VERSION ""

NS_ :

BS_:

BU_: EOCM2B_IMX6_HS EOCM2A_IMX6_HS EOCM2B_K2_HS EOCM2A_K2_HS TTPM_HS AMM_HS EBOOST_OBD_HS CGM_HS BSM_HS HCP_B_HS AVM_HS PFAF_HS LVMPC_HS DCDC_HS DEFC_HS VPM_HS IPC_HS V2V_HS TCP_HS CSM_HS EOCM2B_K1_HS EOCM2A_K1_HS TRCM_HS ESCM_SP_HS ICCM_B_HS AMP_HS FICM_HS ARS_HS MCP_B_HS MCP_A_HS ICCM_OBD_HS SAS_HS ACCM_HS VLBS_HS EBCM_OBD_HS HCP_T_HS EDI_HS PLCM_HS VITM_OBD_HS VICM_HS HCP_HS APPS_HS ICCM_HS EOCM_F_HS GPCM_HS VCM_HS HMIM_HS VES_HS Dummy_HS MCP_C_HS ONSTAR_HS EPS_HS TestTool_HS MCP_HS BCP_HS ALC_HS AHL_AFL_HS SADS_HS EPB_HS FCM_HS TCCM_HS RDCM_HS PTO_HS EBCM_HS ACC_HS BCM_HS TCM_HS ECM_HS

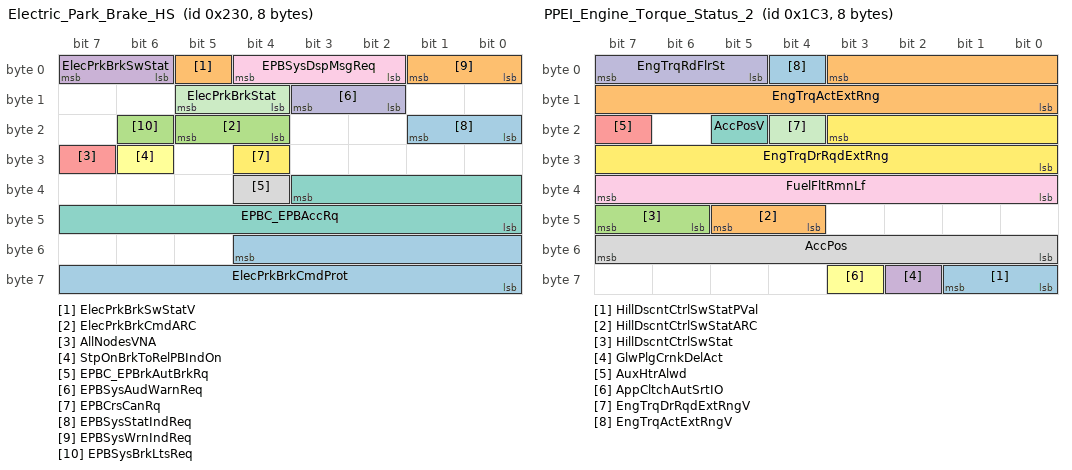
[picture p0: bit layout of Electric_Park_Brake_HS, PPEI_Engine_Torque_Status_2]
BO_ 560 Electric_Park_Brake_HS: 8 EPB_HS
 SG_ ElecPrkBrkCmdProt : 52|13@0+ (1,0) [0|8191] ""  EOCM2B_IMX6_HS,EOCM2A_IMX6_HS,EOCM2B_K1_HS,EOCM2A_K1_HS,CGM_HS,EBCM_OBD_HS,EBCM_HS
 SG_ ElecPrkBrkSwStatV : 5|1@0+ (1,0) [0|1] ""  EOCM2B_IMX6_HS,EOCM2A_IMX6_HS,EOCM2B_K1_HS,EOCM2A_K1_HS,CGM_HS,EBCM_OBD_HS,EBCM_HS
 SG_ ElecPrkBrkCmdARC : 21|2@0+ (1,0) [0|3] ""  EOCM2B_IMX6_HS,EOCM2A_IMX6_HS,EOCM2B_K1_HS,EOCM2A_K1_HS,CGM_HS,EBCM_OBD_HS,EBCM_HS
 SG_ ElecPrkBrkSwStat : 7|2@0+ (1,0) [0|3] ""  EOCM2B_IMX6_HS,EOCM2A_IMX6_HS,EOCM2B_K1_HS,EOCM2A_K1_HS,CGM_HS,EBCM_OBD_HS,EBCM_HS
 SG_ AllNodesVNA : 31|1@0+ (1,0) [0|1] ""  EOCM2B_IMX6_HS,EOCM2A_IMX6_HS,EOCM2B_K1_HS,EOCM2A_K1_HS,CGM_HS,BCM_HS
 SG_ StpOnBrkToRelPBIndOn : 30|1@0+ (1,0) [0|1] ""  EOCM2B_IMX6_HS,EOCM2A_IMX6_HS,EOCM2B_K1_HS,EOCM2A_K1_HS,CGM_HS,BCM_HS
 SG_ EPBC_EPBAccRq : 35|12@0- (0.01,0) [-20.48|20.47] "m/s^2"  EOCM2B_IMX6_HS,EOCM2A_IMX6_HS,EOCM2B_K1_HS,EOCM2A_K1_HS,CGM_HS,EBCM_OBD_HS,EBCM_HS
 SG_ EPBC_EPBrkAutBrkRq : 36|1@0+ (1,0) [0|1] ""  EOCM2B_IMX6_HS,EOCM2A_IMX6_HS,EOCM2B_K1_HS,EOCM2A_K1_HS,CGM_HS,EBCM_OBD_HS,EBCM_HS
 SG_ EPBSysDspMsgReq : 4|3@0+ (1,0) [0|7] ""  EOCM2B_IMX6_HS,EOCM2A_IMX6_HS,EOCM2B_K1_HS,EOCM2A_K1_HS,CGM_HS,BCM_HS
 SG_ EPBSysAudWarnReq : 11|2@0+ (1,0) [0|3] ""  EOCM2B_IMX6_HS,EOCM2A_IMX6_HS,EOCM2B_K1_HS,EOCM2A_K1_HS,CGM_HS,BCM_HS
 SG_ ElecPrkBrkStat : 13|2@0+ (1,0) [0|3] ""  EOCM2B_IMX6_HS,EOCM2A_IMX6_HS,FCM_HS,EOCM2B_K1_HS,EOCM2A_K1_HS,CGM_HS,ICCM_B_HS,ICCM_OBD_HS,ICCM_HS,ACC_HS,EOCM_F_HS,BCM_HS,EBCM_OBD_HS,EBCM_HS,RDCM_HS
 SG_ EPBCrsCanRq : 28|1@0+ (1,0) [0|1] ""  EOCM2B_IMX6_HS,EOCM2A_IMX6_HS,FCM_HS,EOCM2B_K1_HS,EOCM2A_K1_HS,CGM_HS,ACC_HS,EOCM_F_HS,EBCM_OBD_HS,EBCM_HS,BCM_HS
 SG_ EPBSysStatIndReq : 17|2@0+ (1,0) [0|3] ""  EOCM2B_IMX6_HS,EOCM2A_IMX6_HS,EOCM2B_K1_HS,EOCM2A_K1_HS,CGM_HS,BCM_HS
 SG_ EPBSysWrnIndReq : 1|2@0+ (1,0) [0|3] ""  EOCM2B_IMX6_HS,EOCM2A_IMX6_HS,EOCM2B_K1_HS,EOCM2A_K1_HS,CGM_HS,BCM_HS
 SG_ EPBSysBrkLtsReq : 22|1@0+ (1,0) [0|1] ""  EOCM2B_IMX6_HS,EOCM2A_IMX6_HS,EOCM2B_K1_HS,EOCM2A_K1_HS,CGM_HS,BCM_HS

BO_ 451 PPEI_Engine_Torque_Status_2: 8 ECM_HS
 SG_ HillDscntCtrlSwStatPVal : 57|2@0+ (1,0) [0|3] ""  EOCM2B_K2_HS,EOCM2A_K2_HS,EOCM2B_K1_HS,CGM_HS,EOCM2A_K1_HS,EBCM_OBD_HS,EBCM_HS
 SG_ HillDscntCtrlSwStatARC : 45|2@0+ (1,0) [0|3] ""  EOCM2B_K2_HS,EOCM2A_K2_HS,EOCM2B_K1_HS,CGM_HS,EOCM2A_K1_HS,EBCM_OBD_HS,EBCM_HS
 SG_ HillDscntCtrlSwStat : 47|2@0+ (1,0) [0|3] ""  EOCM2B_K2_HS,EOCM2A_K2_HS,EOCM2B_K1_HS,CGM_HS,EOCM2A_K1_HS,EBCM_OBD_HS,EBCM_HS
 SG_ GlwPlgCrnkDelAct : 58|1@0+ (1,0) [0|1] ""  EOCM2B_K2_HS,EOCM2A_K2_HS,EOCM2B_K1_HS,CGM_HS,EOCM2A_K1_HS,BCM_HS
 SG_ AuxHtrAlwd : 23|1@0+ (1,0) [0|1] ""  EOCM2B_K2_HS,EOCM2A_K2_HS,EOCM2B_K1_HS,CGM_HS,EOCM2A_K1_HS,BCM_HS
 SG_ AppCltchAutSrtIO : 59|1@0+ (1,0) [0|1] ""  EOCM2B_K2_HS,EOCM2A_K2_HS,EOCM2B_K1_HS,CGM_HS,EOCM2A_K1_HS,BCM_HS
 SG_ AccPosV : 21|1@0+ (1,0) [0|1] ""  EOCM2B_K2_HS,EOCM2A_K2_HS,FCM_HS,EOCM2B_K1_HS,RDCM_HS,CGM_HS,EOCM2A_K1_HS,ICCM_B_HS,ICCM_OBD_HS,ICCM_HS,ACC_HS,EOCM_F_HS,TCCM_HS,EBCM_OBD_HS,EBCM_HS
 SG_ AccPos : 55|8@0+ (0.392157,0) [0|100.000035] "%"  EOCM2B_K2_HS,EOCM2A_K2_HS,FCM_HS,EOCM2B_K1_HS,RDCM_HS,CGM_HS,EOCM2A_K1_HS,ICCM_B_HS,ICCM_OBD_HS,ICCM_HS,EOCM_F_HS,BSM_HS,VICM_HS,ACC_HS,TCCM_HS,EBCM_OBD_HS,EBCM_HS
 SG_ FuelFltRmnLf : 39|8@0+ (0.392157,0) [0|100.000035] "%"  EOCM2B_K2_HS,EOCM2A_K2_HS,EOCM2B_K1_HS,CGM_HS,EOCM2A_K1_HS,TCP_HS,ONSTAR_HS,BCM_HS
 SG_ EngTrqRdFlrSt : 7|3@0+ (1,0) [0|7] ""  EOCM2B_K2_HS,EOCM2A_K2_HS,EOCM2B_K1_HS,CGM_HS,EOCM2A_K1_HS,EBCM_OBD_HS,EBCM_HS
 SG_ EngTrqDrRqdExtRngV : 20|1@0+ (1,0) [0|1] ""  EOCM2B_K2_HS,EOCM2A_K2_HS,TCCM_HS,EOCM2B_K1_HS,CGM_HS,EOCM2A_K1_HS,BCM_HS,ACC_HS,LVMPC_HS,RDCM_HS,EBCM_OBD_HS,EBCM_HS,SADS_HS
 SG_ EngTrqDrRqdExtRng : 19|12@0+ (0.5,-848) [-848|1199.5] "Nm"  EOCM2B_K2_HS,EOCM2A_K2_HS,TCCM_HS,EOCM2B_K1_HS,CGM_HS,EOCM2A_K1_HS,BCM_HS,LVMPC_HS,ACC_HS,RDCM_HS,EBCM_OBD_HS,EBCM_HS,SADS_HS
 SG_ EngTrqActExtRngV : 4|1@0+ (1,0) [0|1] ""  EOCM2B_K2_HS,EOCM2A_K2_HS,EOCM2B_K1_HS,CGM_HS,EOCM2A_K1_HS,AVM_HS,PTO_HS,ICCM_B_HS,ICCM_OBD_HS,ICCM_HS,AMP_HS,TCCM_HS,VES_HS,ACC_HS,EPS_HS,EPB_HS,BCM_HS,RDCM_HS,EBCM_OBD_HS,EBCM_HS,SADS_HS
 SG_ EngTrqActExtRng : 3|12@0+ (0.5,-848) [-848|1199.5] "Nm"  EOCM2B_K2_HS,EOCM2A_K2_HS,EOCM2B_K1_HS,CGM_HS,EOCM2A_K1_HS,AVM_HS,ICCM_B_HS,ICCM_OBD_HS,ICCM_HS,PTO_HS,AMP_HS,TCCM_HS,VES_HS,ACC_HS,EPS_HS,EPB_HS,BCM_HS,RDCM_HS,EBCM_OBD_HS,EBCM_HS,SADS_HS

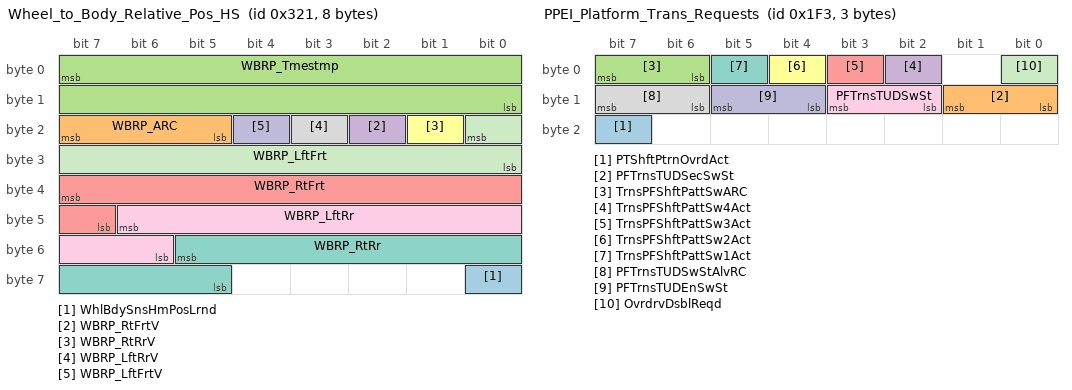
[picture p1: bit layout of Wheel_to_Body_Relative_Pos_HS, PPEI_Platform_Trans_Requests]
BO_ 801 Wheel_to_Body_Relative_Pos_HS: 8 SADS_HS
 SG_ WhlBdySnsHmPosLrnd : 56|1@0+ (1,0) [0|1] ""  EOCM2B_K1_HS,EOCM2A_K1_HS,CGM_HS,EDI_HS,ICCM_B_HS,ICCM_OBD_HS,ICCM_HS,ALC_HS,SADS_HS,FCM_HS,AHL_AFL_HS,EBCM_OBD_HS,EBCM_HS
 SG_ WBRP_ARC : 23|3@0+ (1,0) [0|7] "counts"  LVMPC_HS,EOCM2B_K1_HS,EOCM2A_K1_HS,CGM_HS,EDI_HS,ICCM_B_HS,ICCM_OBD_HS,ICCM_HS,ALC_HS,SADS_HS,FCM_HS,EBCM_OBD_HS,EBCM_HS,AHL_AFL_HS
 SG_ WBRP_Tmestmp : 7|16@0+ (1,0) [0|65535] "micro sec"  LVMPC_HS,EOCM2B_K1_HS,EOCM2A_K1_HS,CGM_HS,EDI_HS,ICCM_B_HS,ICCM_OBD_HS,ICCM_HS,ALC_HS,SADS_HS,FCM_HS,EBCM_OBD_HS,EBCM_HS,AHL_AFL_HS
 SG_ WBRP_RtFrtV : 18|1@0+ (1,0) [0|1] ""  LVMPC_HS,EOCM2B_K1_HS,EOCM2A_K1_HS,CGM_HS,EDI_HS,ICCM_B_HS,ICCM_OBD_HS,ICCM_HS,ALC_HS,SADS_HS,FCM_HS,EBCM_OBD_HS,EBCM_HS,AHL_AFL_HS
 SG_ WBRP_RtFrt : 39|9@0- (1,0) [-256|255] "mm"  LVMPC_HS,EOCM2B_K1_HS,EOCM2A_K1_HS,CGM_HS,EDI_HS,ICCM_B_HS,ICCM_OBD_HS,ICCM_HS,ALC_HS,SADS_HS,FCM_HS,EBCM_OBD_HS,EBCM_HS,AHL_AFL_HS
 SG_ WBRP_RtRrV : 17|1@0+ (1,0) [0|1] ""  LVMPC_HS,EOCM2B_K1_HS,EOCM2A_K1_HS,CGM_HS,EDI_HS,ICCM_B_HS,ICCM_OBD_HS,ICCM_HS,ALC_HS,SADS_HS,FCM_HS,EBCM_OBD_HS,EBCM_HS,AHL_AFL_HS
 SG_ WBRP_RtRr : 53|9@0- (1,0) [-256|255] "mm"  LVMPC_HS,EOCM2B_K1_HS,EOCM2A_K1_HS,CGM_HS,EDI_HS,ICCM_B_HS,ICCM_OBD_HS,ICCM_HS,ALC_HS,SADS_HS,FCM_HS,EBCM_OBD_HS,EBCM_HS,AHL_AFL_HS
 SG_ WBRP_LftRrV : 19|1@0+ (1,0) [0|1] ""  LVMPC_HS,EOCM2B_K1_HS,EOCM2A_K1_HS,CGM_HS,EDI_HS,ICCM_B_HS,ICCM_OBD_HS,ICCM_HS,ALC_HS,SADS_HS,FCM_HS,EBCM_OBD_HS,EBCM_HS,AHL_AFL_HS
 SG_ WBRP_LftRr : 46|9@0- (1,0) [-256|255] "mm"  LVMPC_HS,EOCM2B_K1_HS,EOCM2A_K1_HS,CGM_HS,EDI_HS,ICCM_B_HS,ICCM_OBD_HS,ICCM_HS,ALC_HS,SADS_HS,FCM_HS,EBCM_OBD_HS,EBCM_HS,AHL_AFL_HS
 SG_ WBRP_LftFrtV : 20|1@0+ (1,0) [0|1] ""  LVMPC_HS,EOCM2B_K1_HS,EOCM2A_K1_HS,CGM_HS,EDI_HS,ICCM_B_HS,ICCM_OBD_HS,ICCM_HS,ALC_HS,SADS_HS,FCM_HS,EBCM_OBD_HS,EBCM_HS,AHL_AFL_HS
 SG_ WBRP_LftFrt : 16|9@0- (1,0) [-256|255] "mm"  LVMPC_HS,EOCM2B_K1_HS,EOCM2A_K1_HS,CGM_HS,EDI_HS,ICCM_B_HS,ICCM_OBD_HS,ICCM_HS,ALC_HS,SADS_HS,FCM_HS,EBCM_OBD_HS,EBCM_HS,AHL_AFL_HS

BO_ 320 Exterior_Lighting_HS: 3 BCM_HS
 SG_ Ky_IdDevPrgmAuthReq : 14|1@0+ (1,0) [0|1] ""  EOCM2B_IMX6_HS,EOCM2A_IMX6_HS,EOCM2B_K1_HS,CGM_HS,EPS_HS,EOCM2A_K1_HS
 SG_ ClmnLckStatV : 15|1@0+ (1,0) [0|1] ""  EOCM2B_IMX6_HS,EOCM2A_IMX6_HS,EOCM2B_K1_HS,CGM_HS,EPS_HS,EOCM2A_K1_HS
 SG_ ClmnLckStat : 21|2@0+ (1,0) [0|3] ""  EOCM2B_IMX6_HS,EOCM2A_IMX6_HS,EOCM2B_K1_HS,CGM_HS,EPS_HS,EOCM2A_K1_HS
 SG_ AutoBmSlctAllwd : 13|1@0+ (1,0) [0|1] ""  EOCM2B_IMX6_HS,EOCM2A_IMX6_HS,EOCM2B_K1_HS,CGM_HS,AHL_AFL_HS,EOCM2A_K1_HS
 SG_ BrkLtsAtv : 6|1@0+ (1,0) [0|1] ""  EOCM2B_IMX6_HS,EOCM2A_IMX6_HS,V2V_HS,VPM_HS,EOCM2B_K1_HS,CGM_HS,EOCM2A_K1_HS,AHL_AFL_HS,EOCM_F_HS,ACC_HS
 SG_ TrnSwAct : 19|2@0+ (1,0) [0|3] ""  EOCM2B_IMX6_HS,EOCM2A_IMX6_HS,VPM_HS,EOCM2B_K1_HS,V2V_HS,CGM_HS,EBCM_OBD_HS,EBCM_HS,EOCM2A_K1_HS,ECM_HS,EOCM_F_HS,AHL_AFL_HS
 SG_ RrFogLmpsAct : 8|1@0+ (1,0) [0|1] ""  EOCM2B_IMX6_HS,EOCM2A_IMX6_HS,VPM_HS,EOCM2B_K1_HS,V2V_HS,CGM_HS,EOCM2A_K1_HS,AHL_AFL_HS
 SG_ OtsdAmbtLtLvlStatV : 2|1@0+ (1,0) [0|1] ""  EOCM2B_IMX6_HS,EOCM2A_IMX6_HS,ICCM_B_HS,EBCM_OBD_HS,EBCM_HS,ECM_HS,VPM_HS,ICCM_HS,EOCM2B_K1_HS,CGM_HS,EOCM2A_K1_HS,FCM_HS,EOCM_F_HS,AHL_AFL_HS
 SG_ OtsdAmbtLtLvlStat : 17|2@0+ (1,0) [0|3] ""  EOCM2B_IMX6_HS,EOCM2A_IMX6_HS,ICCM_B_HS,EBCM_OBD_HS,EBCM_HS,ECM_HS,VPM_HS,ICCM_HS,EOCM2B_K1_HS,CGM_HS,EOCM2A_K1_HS,FCM_HS,EOCM_F_HS,AHL_AFL_HS
 SG_ MainLghtSw : 12|2@0+ (1,0) [0|3] "N/A"  EOCM2B_IMX6_HS,EOCM2A_IMX6_HS,VPM_HS,EOCM2B_K1_HS,CGM_HS,EOCM2A_K1_HS,FCM_HS,AHL_AFL_HS
 SG_ LowBmAct : 1|1@0+ (1,0) [0|1] ""  EOCM2B_IMX6_HS,EOCM2A_IMX6_HS,VPM_HS,EOCM2B_K1_HS,V2V_HS,CGM_HS,EOCM2A_K1_HS,FCM_HS,EOCM_F_HS,AHL_AFL_HS
 SG_ HighBmAct : 7|1@0+ (1,0) [0|1] ""  EOCM2B_IMX6_HS,EOCM2A_IMX6_HS,VPM_HS,EOCM2B_K1_HS,V2V_HS,CGM_HS,EOCM2A_K1_HS,FCM_HS,EOCM_F_HS,AHL_AFL_HS
 SG_ HdlmpBmSelectStat : 10|2@0+ (1,0) [0|3] ""  EOCM2B_IMX6_HS,EOCM2A_IMX6_HS,VPM_HS,EOCM2B_K1_HS,CGM_HS,EOCM2A_K1_HS,FCM_HS,AHL_AFL_HS
 SG_ FlToPsSwAtv : 5|1@0+ (1,0) [0|1] ""  EOCM2B_IMX6_HS,EOCM2A_IMX6_HS,EOCM2B_K1_HS,CGM_HS,EOCM2A_K1_HS,FCM_HS,AHL_AFL_HS
 SG_ AdvFrntLghtSysEnbld : 3|1@0+ (1,0) [0|1] ""  EOCM2B_IMX6_HS,EOCM2A_IMX6_HS,V2V_HS,EOCM2B_K1_HS,CGM_HS,EOCM2A_K1_HS,AHL_AFL_HS
 SG_ FrFogLmpsAct : 0|1@0+ (1,0) [0|1] ""  EOCM2B_IMX6_HS,EOCM2A_IMX6_HS,VPM_HS,EOCM2B_K1_HS,V2V_HS,CGM_HS,EOCM2A_K1_HS,FCM_HS,AHL_AFL_HS
 SG_ AutLghtCtrl : 4|1@0+ (1,0) [0|1] "N/A"  EOCM2B_IMX6_HS,EOCM2A_IMX6_HS,V2V_HS,EOCM2B_K1_HS,CGM_HS,EOCM2A_K1_HS,AHL_AFL_HS

BO_ 957 ETEI_Glow_Plug_Diagnostic_Status: 8 GPCM_HS
 SG_ RdctHtrCStat : 26|1@0+ (1,0) [0|1] ""  CGM_HS,ECM_HS
 SG_ RdctHtrBStat : 27|1@0+ (1,0) [0|1] ""  CGM_HS,ECM_HS
 SG_ RdctHtrAStat : 28|1@0+ (1,0) [0|1] ""  CGM_HS,ECM_HS
 SG_ GPCMDS2_DTCStatus : 58|3@0+ (1,0) [0|7] ""  CGM_HS,ECM_HS
 SG_ GPCMDS2_DTCIndex : 63|5@0+ (1,0) [0|31] ""  CGM_HS,ECM_HS
 SG_ IntAirHtrPwrConsmp : 55|8@0+ (20,0) [0|5100] "W"  CGM_HS,ECM_HS
 SG_ IntAirHtrPwrConsmpV : 29|1@0+ (1,0) [0|1] ""  CGM_HS,ECM_HS
 SG_ DslGlwPlgMdOvTmOD : 25|1@0+ (1,0) [0|1] ""  CGM_HS,ECM_HS
 SG_ IQAI_DataByte : 47|8@0+ (1,0) [0|255] ""  CGM_HS,ECM_HS
 SG_ IQAI_DataSeqNmbr : 35|4@0+ (1,0) [0|15] ""  CGM_HS,ECM_HS
 SG_ IQAI_InjIdInd : 38|3@0+ (1,0) [0|7] ""  CGM_HS,ECM_HS
 SG_ IQAI_DataStat : 39|1@0+ (1,0) [0|1] ""  CGM_HS,ECM_HS
 SG_ IntAirHtrTempSensVoltV : 30|1@0+ (1,0) [0|1] ""  CGM_HS,ECM_HS
 SG_ IntAirHtrTempSensVolt : 23|8@0+ (0.0196078,0) [0|4.999989] "volts"  CGM_HS,ECM_HS
 SG_ IntAirHtrSupVoltV : 31|1@0+ (1,0) [0|1] ""  CGM_HS,ECM_HS
 SG_ IntAirHtrSupVolt : 15|8@0+ (0.1,0) [0|25.5] "volts"  CGM_HS,ECM_HS
 SG_ GPCMDS_DTCStatus : 2|3@0+ (1,0) [0|7] ""  CGM_HS,ECM_HS
 SG_ GPCMDS_DTCIndex : 7|5@0+ (1,0) [0|31] ""  CGM_HS,ECM_HS

BO_ 1364 UUDT_Resp_From_EPB_HS: 8 EPB_HS
 SG_ DgnInf_HS554 : 7|64@0+ (1,0) [0|1.8446744074e+19] ""  HMIM_HS,CSM_HS,CGM_HS,TCP_HS,ONSTAR_HS,TestTool_HS

BO_ 2041 PCU_Resp_From_SDM_HS: 8 BCM_HS
 SG_ PCUInfo_7F9 : 7|64@0+ (1,0) [0|1.8446744074e+19] ""  CGM_HS,TestTool_HS

BO_ 1904 DTC_Triggered_770: 7 ICCM_OBD_HS
 SG_ DTCI_WrnIndRqdSt_770 : 47|1@0+ (1,0) [0|1] ""  CGM_HS,CSM_HS,HMIM_HS,TCP_HS,VLBS_HS,ONSTAR_HS
 SG_ DTCIUnused7_770 : 7|1@0+ (1,0) [0|1] ""  CGM_HS,CSM_HS,HMIM_HS,TCP_HS,VLBS_HS,ONSTAR_HS
 SG_ DTCIUnused6_770 : 6|1@0+ (1,0) [0|1] ""  CGM_HS,CSM_HS,HMIM_HS,TCP_HS,VLBS_HS,ONSTAR_HS
 SG_ DTCIUnused5_770 : 5|1@0+ (1,0) [0|1] ""  CGM_HS,CSM_HS,HMIM_HS,TCP_HS,VLBS_HS,ONSTAR_HS
 SG_ DTCIUnused4_770 : 4|1@0+ (1,0) [0|1] ""  CGM_HS,CSM_HS,HMIM_HS,TCP_HS,VLBS_HS,ONSTAR_HS
 SG_ DTCIUnused3_770 : 3|1@0+ (1,0) [0|1] ""  CGM_HS,CSM_HS,HMIM_HS,TCP_HS,VLBS_HS,ONSTAR_HS
 SG_ DTCIUnused2_770 : 2|1@0+ (1,0) [0|1] ""  CGM_HS,CSM_HS,HMIM_HS,TCP_HS,VLBS_HS,ONSTAR_HS
 SG_ DTCIUnused1_770 : 1|1@0+ (1,0) [0|1] ""  CGM_HS,CSM_HS,HMIM_HS,TCP_HS,VLBS_HS,ONSTAR_HS
 SG_ DTCI_TstNPsdPwrUpSt_770 : 45|1@0+ (1,0) [0|1] ""  CGM_HS,CSM_HS,HMIM_HS,TCP_HS,VLBS_HS,ONSTAR_HS
 SG_ DTCI_TstNPsdCdClrdSt_770 : 42|1@0+ (1,0) [0|1] ""  CGM_HS,CSM_HS,HMIM_HS,TCP_HS,VLBS_HS,ONSTAR_HS
 SG_ DTCI_TstFldPwrUpSt_770 : 46|1@0+ (1,0) [0|1] ""  CGM_HS,CSM_HS,HMIM_HS,TCP_HS,VLBS_HS,ONSTAR_HS
 SG_ DTCI_TstFldCdClrdStat_770 : 43|1@0+ (1,0) [0|1] ""  CGM_HS,CSM_HS,HMIM_HS,TCP_HS,VLBS_HS,ONSTAR_HS
 SG_ DTCI_HistStat_770 : 44|1@0+ (1,0) [0|1] ""  CGM_HS,CSM_HS,HMIM_HS,TCP_HS,VLBS_HS,ONSTAR_HS
 SG_ DTCI_DTCTriggered_770 : 0|1@0+ (1,0) [0|1] ""  CGM_HS,CSM_HS,HMIM_HS,TCP_HS,VLBS_HS,ONSTAR_HS
 SG_ DTCI_DTCSource_770 : 15|8@0+ (1,0) [0|255] ""  CGM_HS,CSM_HS,HMIM_HS,TCP_HS,VLBS_HS,ONSTAR_HS
 SG_ DTCI_DTCNumber_770 : 23|16@0+ (1,0) [0|65535] ""  CGM_HS,CSM_HS,HMIM_HS,TCP_HS,VLBS_HS,ONSTAR_HS
 SG_ DTCI_DTCFaultType_770 : 55|8@0+ (1,0) [0|255] ""  CGM_HS,CSM_HS,HMIM_HS,TCP_HS,VLBS_HS,ONSTAR_HS
 SG_ DTCI_DTCFailType_770 : 39|8@0+ (1,0) [0|255] ""  CGM_HS,CSM_HS,HMIM_HS,TCP_HS,VLBS_HS,ONSTAR_HS
 SG_ DTCI_CurrentStatus_770 : 41|1@0+ (1,0) [0|1] ""  CGM_HS,CSM_HS,HMIM_HS,TCP_HS,VLBS_HS,ONSTAR_HS
 SG_ DTCI_CodeSupported_770 : 40|1@0+ (1,0) [0|1] ""  CGM_HS,CSM_HS,HMIM_HS,TCP_HS,VLBS_HS,ONSTAR_HS

BO_ 1908 DTC_Triggered_774: 7 DCDC_HS
 SG_ DTCI_DTCFaultType_774 : 55|8@0+ (1,0) [0|255] ""  CGM_HS,CSM_HS,HMIM_HS,TCP_HS,VLBS_HS,ONSTAR_HS
 SG_ DTCI_CodeSupported_774 : 40|1@0+ (1,0) [0|1] ""  CGM_HS,CSM_HS,HMIM_HS,TCP_HS,VLBS_HS,ONSTAR_HS
 SG_ DTCI_CurrentStatus_774 : 41|1@0+ (1,0) [0|1] ""  CGM_HS,CSM_HS,HMIM_HS,TCP_HS,VLBS_HS,ONSTAR_HS
 SG_ DTCI_TstNPsdCdClrdSt_774 : 42|1@0+ (1,0) [0|1] ""  CGM_HS,CSM_HS,HMIM_HS,TCP_HS,VLBS_HS,ONSTAR_HS
 SG_ DTCI_TstFldCdClrdStat_774 : 43|1@0+ (1,0) [0|1] ""  CGM_HS,CSM_HS,HMIM_HS,TCP_HS,VLBS_HS,ONSTAR_HS
 SG_ DTCI_HistStat_774 : 44|1@0+ (1,0) [0|1] ""  CGM_HS,CSM_HS,HMIM_HS,TCP_HS,VLBS_HS,ONSTAR_HS
 SG_ DTCI_TstNPsdPwrUpSt_774 : 45|1@0+ (1,0) [0|1] ""  CGM_HS,CSM_HS,HMIM_HS,TCP_HS,VLBS_HS,ONSTAR_HS
 SG_ DTCI_TstFldPwrUpSt_774 : 46|1@0+ (1,0) [0|1] ""  CGM_HS,CSM_HS,HMIM_HS,TCP_HS,VLBS_HS,ONSTAR_HS
 SG_ DTCI_WrnIndRqdSt_774 : 47|1@0+ (1,0) [0|1] ""  CGM_HS,CSM_HS,HMIM_HS,TCP_HS,VLBS_HS,ONSTAR_HS
 SG_ DTCI_DTCFailType_774 : 39|8@0+ (1,0) [0|255] ""  CGM_HS,CSM_HS,HMIM_HS,TCP_HS,VLBS_HS,ONSTAR_HS
 SG_ DTCI_DTCNumber_774 : 23|16@0+ (1,0) [0|65535] ""  CGM_HS,CSM_HS,HMIM_HS,TCP_HS,VLBS_HS,ONSTAR_HS
 SG_ DTCI_DTCSource_774 : 15|8@0+ (1,0) [0|255] ""  CGM_HS,CSM_HS,HMIM_HS,TCP_HS,VLBS_HS,ONSTAR_HS
 SG_ DTCI_DTCTriggered_774 : 0|1@0+ (1,0) [0|1] ""  CGM_HS,CSM_HS,HMIM_HS,TCP_HS,VLBS_HS,ONSTAR_HS
 SG_ DTCIUnused7_774 : 1|1@0+ (1,0) [0|1] ""  CGM_HS,CSM_HS,HMIM_HS,TCP_HS,VLBS_HS,ONSTAR_HS
 SG_ DTCIUnused6_774 : 2|1@0+ (1,0) [0|1] ""  CGM_HS,CSM_HS,HMIM_HS,TCP_HS,VLBS_HS,ONSTAR_HS
 SG_ DTCIUnused5_774 : 3|1@0+ (1,0) [0|1] ""  CGM_HS,CSM_HS,HMIM_HS,TCP_HS,VLBS_HS,ONSTAR_HS
 SG_ DTCIUnused4_774 : 4|1@0+ (1,0) [0|1] ""  CGM_HS,CSM_HS,HMIM_HS,TCP_HS,VLBS_HS,ONSTAR_HS
 SG_ DTCIUnused3_774 : 5|1@0+ (1,0) [0|1] ""  CGM_HS,CSM_HS,HMIM_HS,TCP_HS,VLBS_HS,ONSTAR_HS
 SG_ DTCIUnused2_774 : 6|1@0+ (1,0) [0|1] ""  CGM_HS,CSM_HS,HMIM_HS,TCP_HS,VLBS_HS,ONSTAR_HS
 SG_ DTCIUnused1_774 : 7|1@0+ (1,0) [0|1] ""  CGM_HS,CSM_HS,HMIM_HS,TCP_HS,VLBS_HS,ONSTAR_HS

BO_ 1909 DTC_Triggered_775: 7 MCP_HS
 SG_ DTCI_DTCFaultType_775 : 55|8@0+ (1,0) [0|255] ""  CGM_HS,CSM_HS,HMIM_HS,TCP_HS,VLBS_HS,ONSTAR_HS
 SG_ DTCI_CodeSupported_775 : 40|1@0+ (1,0) [0|1] ""  CGM_HS,CSM_HS,HMIM_HS,TCP_HS,VLBS_HS,ONSTAR_HS
 SG_ DTCI_CurrentStatus_775 : 41|1@0+ (1,0) [0|1] ""  CGM_HS,CSM_HS,HMIM_HS,TCP_HS,VLBS_HS,ONSTAR_HS
 SG_ DTCI_TstNPsdCdClrdSt_775 : 42|1@0+ (1,0) [0|1] ""  CGM_HS,CSM_HS,HMIM_HS,TCP_HS,VLBS_HS,ONSTAR_HS
 SG_ DTCI_TstFldCdClrdStat_775 : 43|1@0+ (1,0) [0|1] ""  CGM_HS,CSM_HS,HMIM_HS,TCP_HS,VLBS_HS,ONSTAR_HS
 SG_ DTCI_HistStat_775 : 44|1@0+ (1,0) [0|1] ""  CGM_HS,CSM_HS,HMIM_HS,TCP_HS,VLBS_HS,ONSTAR_HS
 SG_ DTCI_TstNPsdPwrUpSt_775 : 45|1@0+ (1,0) [0|1] ""  CGM_HS,CSM_HS,HMIM_HS,TCP_HS,VLBS_HS,ONSTAR_HS
 SG_ DTCI_TstFldPwrUpSt_775 : 46|1@0+ (1,0) [0|1] ""  CGM_HS,CSM_HS,HMIM_HS,TCP_HS,VLBS_HS,ONSTAR_HS
 SG_ DTCI_WrnIndRqdSt_775 : 47|1@0+ (1,0) [0|1] ""  CGM_HS,CSM_HS,HMIM_HS,TCP_HS,VLBS_HS,ONSTAR_HS
 SG_ DTCI_DTCFailType_775 : 39|8@0+ (1,0) [0|255] ""  CGM_HS,CSM_HS,HMIM_HS,TCP_HS,VLBS_HS,ONSTAR_HS
 SG_ DTCI_DTCNumber_775 : 23|16@0+ (1,0) [0|65535] ""  CGM_HS,CSM_HS,HMIM_HS,TCP_HS,VLBS_HS,ONSTAR_HS
 SG_ DTCI_DTCSource_775 : 15|8@0+ (1,0) [0|255] ""  CGM_HS,CSM_HS,HMIM_HS,TCP_HS,VLBS_HS,ONSTAR_HS
 SG_ DTCI_DTCTriggered_775 : 0|1@0+ (1,0) [0|1] ""  CGM_HS,CSM_HS,HMIM_HS,TCP_HS,VLBS_HS,ONSTAR_HS
 SG_ DTCIUnused7_775 : 1|1@0+ (1,0) [0|1] ""  CGM_HS,CSM_HS,HMIM_HS,TCP_HS,VLBS_HS,ONSTAR_HS
 SG_ DTCIUnused6_775 : 2|1@0+ (1,0) [0|1] ""  CGM_HS,CSM_HS,HMIM_HS,TCP_HS,VLBS_HS,ONSTAR_HS
 SG_ DTCIUnused5_775 : 3|1@0+ (1,0) [0|1] ""  CGM_HS,CSM_HS,HMIM_HS,TCP_HS,VLBS_HS,ONSTAR_HS
 SG_ DTCIUnused4_775 : 4|1@0+ (1,0) [0|1] ""  CGM_HS,CSM_HS,HMIM_HS,TCP_HS,VLBS_HS,ONSTAR_HS
 SG_ DTCIUnused3_775 : 5|1@0+ (1,0) [0|1] ""  CGM_HS,CSM_HS,HMIM_HS,TCP_HS,VLBS_HS,ONSTAR_HS
 SG_ DTCIUnused2_775 : 6|1@0+ (1,0) [0|1] ""  CGM_HS,CSM_HS,HMIM_HS,TCP_HS,VLBS_HS,ONSTAR_HS
 SG_ DTCIUnused1_775 : 7|1@0+ (1,0) [0|1] ""  CGM_HS,CSM_HS,HMIM_HS,TCP_HS,VLBS_HS,ONSTAR_HS

BO_ 1910 DTC_Triggered_776: 7 BCP_HS
 SG_ DTCI_DTCFaultType_776 : 55|8@0+ (1,0) [0|255] ""  CGM_HS,CSM_HS,HMIM_HS,TCP_HS,VLBS_HS,ONSTAR_HS
 SG_ DTCI_CodeSupported_776 : 40|1@0+ (1,0) [0|1] ""  CGM_HS,CSM_HS,HMIM_HS,TCP_HS,VLBS_HS,ONSTAR_HS
 SG_ DTCI_CurrentStatus_776 : 41|1@0+ (1,0) [0|1] ""  CGM_HS,CSM_HS,HMIM_HS,TCP_HS,VLBS_HS,ONSTAR_HS
 SG_ DTCI_TstNPsdCdClrdSt_776 : 42|1@0+ (1,0) [0|1] ""  CGM_HS,CSM_HS,HMIM_HS,TCP_HS,VLBS_HS,ONSTAR_HS
 SG_ DTCI_TstFldCdClrdStat_776 : 43|1@0+ (1,0) [0|1] ""  CGM_HS,CSM_HS,HMIM_HS,TCP_HS,VLBS_HS,ONSTAR_HS
 SG_ DTCI_HistStat_776 : 44|1@0+ (1,0) [0|1] ""  CGM_HS,CSM_HS,HMIM_HS,TCP_HS,VLBS_HS,ONSTAR_HS
 SG_ DTCI_TstNPsdPwrUpSt_776 : 45|1@0+ (1,0) [0|1] ""  CGM_HS,CSM_HS,HMIM_HS,TCP_HS,VLBS_HS,ONSTAR_HS
 SG_ DTCI_TstFldPwrUpSt_776 : 46|1@0+ (1,0) [0|1] ""  CGM_HS,CSM_HS,HMIM_HS,TCP_HS,VLBS_HS,ONSTAR_HS
 SG_ DTCI_WrnIndRqdSt_776 : 47|1@0+ (1,0) [0|1] ""  CGM_HS,CSM_HS,HMIM_HS,TCP_HS,VLBS_HS,ONSTAR_HS
 SG_ DTCI_DTCFailType_776 : 39|8@0+ (1,0) [0|255] ""  CGM_HS,CSM_HS,HMIM_HS,TCP_HS,VLBS_HS,ONSTAR_HS
 SG_ DTCI_DTCNumber_776 : 23|16@0+ (1,0) [0|65535] ""  CGM_HS,CSM_HS,HMIM_HS,TCP_HS,VLBS_HS,ONSTAR_HS
 SG_ DTCI_DTCSource_776 : 15|8@0+ (1,0) [0|255] ""  CGM_HS,CSM_HS,HMIM_HS,TCP_HS,VLBS_HS,ONSTAR_HS
 SG_ DTCI_DTCTriggered_776 : 0|1@0+ (1,0) [0|1] ""  CGM_HS,CSM_HS,HMIM_HS,TCP_HS,VLBS_HS,ONSTAR_HS
 SG_ DTCIUnused7_776 : 1|1@0+ (1,0) [0|1] ""  CGM_HS,CSM_HS,HMIM_HS,TCP_HS,VLBS_HS,ONSTAR_HS
 SG_ DTCIUnused6_776 : 2|1@0+ (1,0) [0|1] ""  CGM_HS,CSM_HS,HMIM_HS,TCP_HS,VLBS_HS,ONSTAR_HS
 SG_ DTCIUnused5_776 : 3|1@0+ (1,0) [0|1] ""  CGM_HS,CSM_HS,HMIM_HS,TCP_HS,VLBS_HS,ONSTAR_HS
 SG_ DTCIUnused4_776 : 4|1@0+ (1,0) [0|1] ""  CGM_HS,CSM_HS,HMIM_HS,TCP_HS,VLBS_HS,ONSTAR_HS
 SG_ DTCIUnused3_776 : 5|1@0+ (1,0) [0|1] ""  CGM_HS,CSM_HS,HMIM_HS,TCP_HS,VLBS_HS,ONSTAR_HS
 SG_ DTCIUnused2_776 : 6|1@0+ (1,0) [0|1] ""  CGM_HS,CSM_HS,HMIM_HS,TCP_HS,VLBS_HS,ONSTAR_HS
 SG_ DTCIUnused1_776 : 7|1@0+ (1,0) [0|1] ""  CGM_HS,CSM_HS,HMIM_HS,TCP_HS,VLBS_HS,ONSTAR_HS

BO_ 1912 DTC_Triggered_778: 7 EPS_HS
 SG_ DTCI_DTCFaultType_778 : 55|8@0+ (1,0) [0|255] ""  CGM_HS,CSM_HS,HMIM_HS,TCP_HS,VLBS_HS,ONSTAR_HS
 SG_ DTCI_CodeSupported_778 : 40|1@0+ (1,0) [0|1] ""  CGM_HS,CSM_HS,HMIM_HS,TCP_HS,VLBS_HS,ONSTAR_HS
 SG_ DTCI_CurrentStatus_778 : 41|1@0+ (1,0) [0|1] ""  CGM_HS,CSM_HS,HMIM_HS,TCP_HS,VLBS_HS,ONSTAR_HS
 SG_ DTCI_TstNPsdCdClrdSt_778 : 42|1@0+ (1,0) [0|1] ""  CGM_HS,CSM_HS,HMIM_HS,TCP_HS,VLBS_HS,ONSTAR_HS
 SG_ DTCI_TstFldCdClrdStat_778 : 43|1@0+ (1,0) [0|1] ""  CGM_HS,CSM_HS,HMIM_HS,TCP_HS,VLBS_HS,ONSTAR_HS
 SG_ DTCI_HistStat_778 : 44|1@0+ (1,0) [0|1] ""  CGM_HS,CSM_HS,HMIM_HS,TCP_HS,VLBS_HS,ONSTAR_HS
 SG_ DTCI_TstNPsdPwrUpSt_778 : 45|1@0+ (1,0) [0|1] ""  CGM_HS,CSM_HS,HMIM_HS,TCP_HS,VLBS_HS,ONSTAR_HS
 SG_ DTCI_TstFldPwrUpSt_778 : 46|1@0+ (1,0) [0|1] ""  CGM_HS,CSM_HS,HMIM_HS,TCP_HS,VLBS_HS,ONSTAR_HS
 SG_ DTCI_WrnIndRqdSt_778 : 47|1@0+ (1,0) [0|1] ""  CGM_HS,CSM_HS,HMIM_HS,TCP_HS,VLBS_HS,ONSTAR_HS
 SG_ DTCI_DTCFailType_778 : 39|8@0+ (1,0) [0|255] ""  CGM_HS,CSM_HS,HMIM_HS,TCP_HS,VLBS_HS,ONSTAR_HS
 SG_ DTCI_DTCNumber_778 : 23|16@0+ (1,0) [0|65535] ""  CGM_HS,CSM_HS,HMIM_HS,TCP_HS,VLBS_HS,ONSTAR_HS
 SG_ DTCI_DTCSource_778 : 15|8@0+ (1,0) [0|255] ""  CGM_HS,CSM_HS,HMIM_HS,TCP_HS,VLBS_HS,ONSTAR_HS
 SG_ DTCI_DTCTriggered_778 : 0|1@0+ (1,0) [0|1] ""  CGM_HS,CSM_HS,HMIM_HS,TCP_HS,VLBS_HS,ONSTAR_HS
 SG_ DTCIUnused7_778 : 1|1@0+ (1,0) [0|1] ""  CGM_HS,CSM_HS,HMIM_HS,TCP_HS,VLBS_HS,ONSTAR_HS
 SG_ DTCIUnused6_778 : 2|1@0+ (1,0) [0|1] ""  CGM_HS,CSM_HS,HMIM_HS,TCP_HS,VLBS_HS,ONSTAR_HS
 SG_ DTCIUnused5_778 : 3|1@0+ (1,0) [0|1] ""  CGM_HS,CSM_HS,HMIM_HS,TCP_HS,VLBS_HS,ONSTAR_HS
 SG_ DTCIUnused4_778 : 4|1@0+ (1,0) [0|1] ""  CGM_HS,CSM_HS,HMIM_HS,TCP_HS,VLBS_HS,ONSTAR_HS
 SG_ DTCIUnused3_778 : 5|1@0+ (1,0) [0|1] ""  CGM_HS,CSM_HS,HMIM_HS,TCP_HS,VLBS_HS,ONSTAR_HS
 SG_ DTCIUnused2_778 : 6|1@0+ (1,0) [0|1] ""  CGM_HS,CSM_HS,HMIM_HS,TCP_HS,VLBS_HS,ONSTAR_HS
 SG_ DTCIUnused1_778 : 7|1@0+ (1,0) [0|1] ""  CGM_HS,CSM_HS,HMIM_HS,TCP_HS,VLBS_HS,ONSTAR_HS

BO_ 1913 DTC_Triggered_779: 7 TRCM_HS
 SG_ DTCI_DTCFaultType_779 : 55|8@0+ (1,0) [0|255] ""  CGM_HS,CSM_HS,HMIM_HS,TCP_HS,VLBS_HS,ONSTAR_HS
 SG_ DTCI_CodeSupported_779 : 40|1@0+ (1,0) [0|1] ""  CGM_HS,CSM_HS,HMIM_HS,TCP_HS,VLBS_HS,ONSTAR_HS
 SG_ DTCI_CurrentStatus_779 : 41|1@0+ (1,0) [0|1] ""  CGM_HS,CSM_HS,HMIM_HS,TCP_HS,VLBS_HS,ONSTAR_HS
 SG_ DTCI_TstNPsdCdClrdSt_779 : 42|1@0+ (1,0) [0|1] ""  CGM_HS,CSM_HS,HMIM_HS,TCP_HS,VLBS_HS,ONSTAR_HS
 SG_ DTCI_TstFldCdClrdStat_779 : 43|1@0+ (1,0) [0|1] ""  CGM_HS,CSM_HS,HMIM_HS,TCP_HS,VLBS_HS,ONSTAR_HS
 SG_ DTCI_HistStat_779 : 44|1@0+ (1,0) [0|1] ""  CGM_HS,CSM_HS,HMIM_HS,TCP_HS,VLBS_HS,ONSTAR_HS
 SG_ DTCI_TstNPsdPwrUpSt_779 : 45|1@0+ (1,0) [0|1] ""  CGM_HS,CSM_HS,HMIM_HS,TCP_HS,VLBS_HS,ONSTAR_HS
 SG_ DTCI_TstFldPwrUpSt_779 : 46|1@0+ (1,0) [0|1] ""  CGM_HS,CSM_HS,HMIM_HS,TCP_HS,VLBS_HS,ONSTAR_HS
 SG_ DTCI_WrnIndRqdSt_779 : 47|1@0+ (1,0) [0|1] ""  CGM_HS,CSM_HS,HMIM_HS,TCP_HS,VLBS_HS,ONSTAR_HS
 SG_ DTCI_DTCFailType_779 : 39|8@0+ (1,0) [0|255] ""  CGM_HS,CSM_HS,HMIM_HS,TCP_HS,VLBS_HS,ONSTAR_HS
 SG_ DTCI_DTCNumber_779 : 23|16@0+ (1,0) [0|65535] ""  CGM_HS,CSM_HS,HMIM_HS,TCP_HS,VLBS_HS,ONSTAR_HS
 SG_ DTCI_DTCSource_779 : 15|8@0+ (1,0) [0|255] ""  CGM_HS,CSM_HS,HMIM_HS,TCP_HS,VLBS_HS,ONSTAR_HS
 SG_ DTCI_DTCTriggered_779 : 0|1@0+ (1,0) [0|1] ""  CGM_HS,CSM_HS,HMIM_HS,TCP_HS,VLBS_HS,ONSTAR_HS
 SG_ DTCIUnused7_779 : 1|1@0+ (1,0) [0|1] ""  CGM_HS,CSM_HS,HMIM_HS,TCP_HS,VLBS_HS,ONSTAR_HS
 SG_ DTCIUnused6_779 : 2|1@0+ (1,0) [0|1] ""  CGM_HS,CSM_HS,HMIM_HS,TCP_HS,VLBS_HS,ONSTAR_HS
 SG_ DTCIUnused5_779 : 3|1@0+ (1,0) [0|1] ""  CGM_HS,CSM_HS,HMIM_HS,TCP_HS,VLBS_HS,ONSTAR_HS
 SG_ DTCIUnused4_779 : 4|1@0+ (1,0) [0|1] ""  CGM_HS,CSM_HS,HMIM_HS,TCP_HS,VLBS_HS,ONSTAR_HS
 SG_ DTCIUnused3_779 : 5|1@0+ (1,0) [0|1] ""  CGM_HS,CSM_HS,HMIM_HS,TCP_HS,VLBS_HS,ONSTAR_HS
 SG_ DTCIUnused2_779 : 6|1@0+ (1,0) [0|1] ""  CGM_HS,CSM_HS,HMIM_HS,TCP_HS,VLBS_HS,ONSTAR_HS
 SG_ DTCIUnused1_779 : 7|1@0+ (1,0) [0|1] ""  CGM_HS,CSM_HS,HMIM_HS,TCP_HS,VLBS_HS,ONSTAR_HS

BO_ 1916 DTC_Triggered_77C: 7 CGM_HS
 SG_ DTCI_DTCFaultType_77C : 55|8@0+ (1,0) [0|255] ""  CGM_HS,CSM_HS,HMIM_HS,TCP_HS,VLBS_HS,ONSTAR_HS
 SG_ DTCI_CodeSupported_77C : 40|1@0+ (1,0) [0|1] ""  CGM_HS,CSM_HS,HMIM_HS,TCP_HS,VLBS_HS,ONSTAR_HS
 SG_ DTCI_CurrentStatus_77C : 41|1@0+ (1,0) [0|1] ""  CGM_HS,CSM_HS,HMIM_HS,TCP_HS,VLBS_HS,ONSTAR_HS
 SG_ DTCI_TstNPsdCdClrdSt_77C : 42|1@0+ (1,0) [0|1] ""  CGM_HS,CSM_HS,HMIM_HS,TCP_HS,VLBS_HS,ONSTAR_HS
 SG_ DTCI_TstFldCdClrdStat_77C : 43|1@0+ (1,0) [0|1] ""  CGM_HS,CSM_HS,HMIM_HS,TCP_HS,VLBS_HS,ONSTAR_HS
 SG_ DTCI_HistStat_77C : 44|1@0+ (1,0) [0|1] ""  CGM_HS,CSM_HS,HMIM_HS,TCP_HS,VLBS_HS,ONSTAR_HS
 SG_ DTCI_TstNPsdPwrUpSt_77C : 45|1@0+ (1,0) [0|1] ""  CGM_HS,CSM_HS,HMIM_HS,TCP_HS,VLBS_HS,ONSTAR_HS
 SG_ DTCI_TstFldPwrUpSt_77C : 46|1@0+ (1,0) [0|1] ""  CGM_HS,CSM_HS,HMIM_HS,TCP_HS,VLBS_HS,ONSTAR_HS
 SG_ DTCI_WrnIndRqdSt_77C : 47|1@0+ (1,0) [0|1] ""  CGM_HS,CSM_HS,HMIM_HS,TCP_HS,VLBS_HS,ONSTAR_HS
 SG_ DTCI_DTCFailType_77C : 39|8@0+ (1,0) [0|255] ""  CGM_HS,CSM_HS,HMIM_HS,TCP_HS,VLBS_HS,ONSTAR_HS
 SG_ DTCI_DTCNumber_77C : 23|16@0+ (1,0) [0|65535] ""  CGM_HS,CSM_HS,HMIM_HS,TCP_HS,VLBS_HS,ONSTAR_HS
 SG_ DTCI_DTCSource_77C : 15|8@0+ (1,0) [0|255] ""  CGM_HS,CSM_HS,HMIM_HS,TCP_HS,VLBS_HS,ONSTAR_HS
 SG_ DTCI_DTCTriggered_77C : 0|1@0+ (1,0) [0|1] ""  CGM_HS,CSM_HS,HMIM_HS,TCP_HS,VLBS_HS,ONSTAR_HS
 SG_ DTCIUnused7_77C : 1|1@0+ (1,0) [0|1] ""  CGM_HS,CSM_HS,HMIM_HS,TCP_HS,VLBS_HS,ONSTAR_HS
 SG_ DTCIUnused6_77C : 2|1@0+ (1,0) [0|1] ""  CGM_HS,CSM_HS,HMIM_HS,TCP_HS,VLBS_HS,ONSTAR_HS
 SG_ DTCIUnused5_77C : 3|1@0+ (1,0) [0|1] ""  CGM_HS,CSM_HS,HMIM_HS,TCP_HS,VLBS_HS,ONSTAR_HS
 SG_ DTCIUnused4_77C : 4|1@0+ (1,0) [0|1] ""  CGM_HS,CSM_HS,HMIM_HS,TCP_HS,VLBS_HS,ONSTAR_HS
 SG_ DTCIUnused3_77C : 5|1@0+ (1,0) [0|1] ""  CGM_HS,CSM_HS,HMIM_HS,TCP_HS,VLBS_HS,ONSTAR_HS
 SG_ DTCIUnused2_77C : 6|1@0+ (1,0) [0|1] ""  CGM_HS,CSM_HS,HMIM_HS,TCP_HS,VLBS_HS,ONSTAR_HS
 SG_ DTCIUnused1_77C : 7|1@0+ (1,0) [0|1] ""  CGM_HS,CSM_HS,HMIM_HS,TCP_HS,VLBS_HS,ONSTAR_HS

BO_ 1917 DTC_Triggered_77D: 7 EPB_HS
 SG_ DTCI_DTCFaultType_77D : 55|8@0+ (1,0) [0|255] ""  CGM_HS,CSM_HS,HMIM_HS,TCP_HS,VLBS_HS,ONSTAR_HS
 SG_ DTCI_CodeSupported_77D : 40|1@0+ (1,0) [0|1] ""  CGM_HS,CSM_HS,HMIM_HS,TCP_HS,VLBS_HS,ONSTAR_HS
 SG_ DTCI_CurrentStatus_77D : 41|1@0+ (1,0) [0|1] ""  CGM_HS,CSM_HS,HMIM_HS,TCP_HS,VLBS_HS,ONSTAR_HS
 SG_ DTCI_TstNPsdCdClrdSt_77D : 42|1@0+ (1,0) [0|1] ""  CGM_HS,CSM_HS,HMIM_HS,TCP_HS,VLBS_HS,ONSTAR_HS
 SG_ DTCI_TstFldCdClrdStat_77D : 43|1@0+ (1,0) [0|1] ""  CGM_HS,CSM_HS,HMIM_HS,TCP_HS,VLBS_HS,ONSTAR_HS
 SG_ DTCI_HistStat_77D : 44|1@0+ (1,0) [0|1] ""  CGM_HS,CSM_HS,HMIM_HS,TCP_HS,VLBS_HS,ONSTAR_HS
 SG_ DTCI_TstNPsdPwrUpSt_77D : 45|1@0+ (1,0) [0|1] ""  CGM_HS,CSM_HS,HMIM_HS,TCP_HS,VLBS_HS,ONSTAR_HS
 SG_ DTCI_TstFldPwrUpSt_77D : 46|1@0+ (1,0) [0|1] ""  CGM_HS,CSM_HS,HMIM_HS,TCP_HS,VLBS_HS,ONSTAR_HS
 SG_ DTCI_WrnIndRqdSt_77D : 47|1@0+ (1,0) [0|1] ""  CGM_HS,CSM_HS,HMIM_HS,TCP_HS,VLBS_HS,ONSTAR_HS
 SG_ DTCI_DTCFailType_77D : 39|8@0+ (1,0) [0|255] ""  CGM_HS,CSM_HS,HMIM_HS,TCP_HS,VLBS_HS,ONSTAR_HS
 SG_ DTCI_DTCNumber_77D : 23|16@0+ (1,0) [0|65535] ""  CGM_HS,CSM_HS,HMIM_HS,TCP_HS,VLBS_HS,ONSTAR_HS
 SG_ DTCI_DTCSource_77D : 15|8@0+ (1,0) [0|255] ""  CGM_HS,CSM_HS,HMIM_HS,TCP_HS,VLBS_HS,ONSTAR_HS
 SG_ DTCI_DTCTriggered_77D : 0|1@0+ (1,0) [0|1] ""  CGM_HS,CSM_HS,HMIM_HS,TCP_HS,VLBS_HS,ONSTAR_HS
 SG_ DTCIUnused7_77D : 1|1@0+ (1,0) [0|1] ""  CGM_HS,CSM_HS,HMIM_HS,TCP_HS,VLBS_HS,ONSTAR_HS
 SG_ DTCIUnused6_77D : 2|1@0+ (1,0) [0|1] ""  CGM_HS,CSM_HS,HMIM_HS,TCP_HS,VLBS_HS,ONSTAR_HS
 SG_ DTCIUnused5_77D : 3|1@0+ (1,0) [0|1] ""  CGM_HS,CSM_HS,HMIM_HS,TCP_HS,VLBS_HS,ONSTAR_HS
 SG_ DTCIUnused4_77D : 4|1@0+ (1,0) [0|1] ""  CGM_HS,CSM_HS,HMIM_HS,TCP_HS,VLBS_HS,ONSTAR_HS
 SG_ DTCIUnused3_77D : 5|1@0+ (1,0) [0|1] ""  CGM_HS,CSM_HS,HMIM_HS,TCP_HS,VLBS_HS,ONSTAR_HS
 SG_ DTCIUnused2_77D : 6|1@0+ (1,0) [0|1] ""  CGM_HS,CSM_HS,HMIM_HS,TCP_HS,VLBS_HS,ONSTAR_HS
 SG_ DTCIUnused1_77D : 7|1@0+ (1,0) [0|1] ""  CGM_HS,CSM_HS,HMIM_HS,TCP_HS,VLBS_HS,ONSTAR_HS

BO_ 1918 DTC_Triggered_77E: 7 SADS_HS
 SG_ DTCI_DTCFaultType_77E : 55|8@0+ (1,0) [0|255] ""  CGM_HS,CSM_HS,HMIM_HS,TCP_HS,VLBS_HS,ONSTAR_HS
 SG_ DTCI_CodeSupported_77E : 40|1@0+ (1,0) [0|1] ""  CGM_HS,CSM_HS,HMIM_HS,TCP_HS,VLBS_HS,ONSTAR_HS
 SG_ DTCI_CurrentStatus_77E : 41|1@0+ (1,0) [0|1] ""  CGM_HS,CSM_HS,HMIM_HS,TCP_HS,VLBS_HS,ONSTAR_HS
 SG_ DTCI_TstNPsdCdClrdSt_77E : 42|1@0+ (1,0) [0|1] ""  CGM_HS,CSM_HS,HMIM_HS,TCP_HS,VLBS_HS,ONSTAR_HS
 SG_ DTCI_TstFldCdClrdStat_77E : 43|1@0+ (1,0) [0|1] ""  CGM_HS,CSM_HS,HMIM_HS,TCP_HS,VLBS_HS,ONSTAR_HS
 SG_ DTCI_HistStat_77E : 44|1@0+ (1,0) [0|1] ""  CGM_HS,CSM_HS,HMIM_HS,TCP_HS,VLBS_HS,ONSTAR_HS
 SG_ DTCI_TstNPsdPwrUpSt_77E : 45|1@0+ (1,0) [0|1] ""  CGM_HS,CSM_HS,HMIM_HS,TCP_HS,VLBS_HS,ONSTAR_HS
 SG_ DTCI_TstFldPwrUpSt_77E : 46|1@0+ (1,0) [0|1] ""  CGM_HS,CSM_HS,HMIM_HS,TCP_HS,VLBS_HS,ONSTAR_HS
 SG_ DTCI_WrnIndRqdSt_77E : 47|1@0+ (1,0) [0|1] ""  CGM_HS,CSM_HS,HMIM_HS,TCP_HS,VLBS_HS,ONSTAR_HS
 SG_ DTCI_DTCFailType_77E : 39|8@0+ (1,0) [0|255] ""  CGM_HS,CSM_HS,HMIM_HS,TCP_HS,VLBS_HS,ONSTAR_HS
 SG_ DTCI_DTCNumber_77E : 23|16@0+ (1,0) [0|65535] ""  CGM_HS,CSM_HS,HMIM_HS,TCP_HS,VLBS_HS,ONSTAR_HS
 SG_ DTCI_DTCSource_77E : 15|8@0+ (1,0) [0|255] ""  CGM_HS,CSM_HS,HMIM_HS,TCP_HS,VLBS_HS,ONSTAR_HS
 SG_ DTCI_DTCTriggered_77E : 0|1@0+ (1,0) [0|1] ""  CGM_HS,CSM_HS,HMIM_HS,TCP_HS,VLBS_HS,ONSTAR_HS
 SG_ DTCIUnused7_77E : 1|1@0+ (1,0) [0|1] ""  CGM_HS,CSM_HS,HMIM_HS,TCP_HS,VLBS_HS,ONSTAR_HS
 SG_ DTCIUnused6_77E : 2|1@0+ (1,0) [0|1] ""  CGM_HS,CSM_HS,HMIM_HS,TCP_HS,VLBS_HS,ONSTAR_HS
 SG_ DTCIUnused5_77E : 3|1@0+ (1,0) [0|1] ""  CGM_HS,CSM_HS,HMIM_HS,TCP_HS,VLBS_HS,ONSTAR_HS
 SG_ DTCIUnused4_77E : 4|1@0+ (1,0) [0|1] ""  CGM_HS,CSM_HS,HMIM_HS,TCP_HS,VLBS_HS,ONSTAR_HS
 SG_ DTCIUnused3_77E : 5|1@0+ (1,0) [0|1] ""  CGM_HS,CSM_HS,HMIM_HS,TCP_HS,VLBS_HS,ONSTAR_HS
 SG_ DTCIUnused2_77E : 6|1@0+ (1,0) [0|1] ""  CGM_HS,CSM_HS,HMIM_HS,TCP_HS,VLBS_HS,ONSTAR_HS
 SG_ DTCIUnused1_77E : 7|1@0+ (1,0) [0|1] ""  CGM_HS,CSM_HS,HMIM_HS,TCP_HS,VLBS_HS,ONSTAR_HS

BO_ 1919 DTC_Triggered_77F: 7 TCM_HS
 SG_ DTCI_DTCFaultType_77F : 55|8@0+ (1,0) [0|255] ""  CGM_HS,CSM_HS,HMIM_HS,TCP_HS,VLBS_HS,ONSTAR_HS
 SG_ DTCI_CodeSupported_77F : 40|1@0+ (1,0) [0|1] ""  CGM_HS,CSM_HS,HMIM_HS,TCP_HS,VLBS_HS,ONSTAR_HS
 SG_ DTCI_CurrentStatus_77F : 41|1@0+ (1,0) [0|1] ""  CGM_HS,CSM_HS,HMIM_HS,TCP_HS,VLBS_HS,ONSTAR_HS
 SG_ DTCI_TstNPsdCdClrdSt_77F : 42|1@0+ (1,0) [0|1] ""  CGM_HS,CSM_HS,HMIM_HS,TCP_HS,VLBS_HS,ONSTAR_HS
 SG_ DTCI_TstFldCdClrdStat_77F : 43|1@0+ (1,0) [0|1] ""  CGM_HS,CSM_HS,HMIM_HS,TCP_HS,VLBS_HS,ONSTAR_HS
 SG_ DTCI_HistStat_77F : 44|1@0+ (1,0) [0|1] ""  CGM_HS,CSM_HS,HMIM_HS,TCP_HS,VLBS_HS,ONSTAR_HS
 SG_ DTCI_TstNPsdPwrUpSt_77F : 45|1@0+ (1,0) [0|1] ""  CGM_HS,CSM_HS,HMIM_HS,TCP_HS,VLBS_HS,ONSTAR_HS
 SG_ DTCI_TstFldPwrUpSt_77F : 46|1@0+ (1,0) [0|1] ""  CGM_HS,CSM_HS,HMIM_HS,TCP_HS,VLBS_HS,ONSTAR_HS
 SG_ DTCI_WrnIndRqdSt_77F : 47|1@0+ (1,0) [0|1] ""  CGM_HS,CSM_HS,HMIM_HS,TCP_HS,VLBS_HS,ONSTAR_HS
 SG_ DTCI_DTCFailType_77F : 39|8@0+ (1,0) [0|255] ""  CGM_HS,CSM_HS,HMIM_HS,TCP_HS,VLBS_HS,ONSTAR_HS
 SG_ DTCI_DTCNumber_77F : 23|16@0+ (1,0) [0|65535] ""  CGM_HS,CSM_HS,HMIM_HS,TCP_HS,VLBS_HS,ONSTAR_HS
 SG_ DTCI_DTCSource_77F : 15|8@0+ (1,0) [0|255] ""  CGM_HS,CSM_HS,HMIM_HS,TCP_HS,VLBS_HS,ONSTAR_HS
 SG_ DTCI_DTCTriggered_77F : 0|1@0+ (1,0) [0|1] ""  CGM_HS,CSM_HS,HMIM_HS,TCP_HS,VLBS_HS,ONSTAR_HS
 SG_ DTCIUnused7_77F : 1|1@0+ (1,0) [0|1] ""  CGM_HS,CSM_HS,HMIM_HS,TCP_HS,VLBS_HS,ONSTAR_HS
 SG_ DTCIUnused6_77F : 2|1@0+ (1,0) [0|1] ""  CGM_HS,CSM_HS,HMIM_HS,TCP_HS,VLBS_HS,ONSTAR_HS
 SG_ DTCIUnused5_77F : 3|1@0+ (1,0) [0|1] ""  CGM_HS,CSM_HS,HMIM_HS,TCP_HS,VLBS_HS,ONSTAR_HS
 SG_ DTCIUnused4_77F : 4|1@0+ (1,0) [0|1] ""  CGM_HS,CSM_HS,HMIM_HS,TCP_HS,VLBS_HS,ONSTAR_HS
 SG_ DTCIUnused3_77F : 5|1@0+ (1,0) [0|1] ""  CGM_HS,CSM_HS,HMIM_HS,TCP_HS,VLBS_HS,ONSTAR_HS
 SG_ DTCIUnused2_77F : 6|1@0+ (1,0) [0|1] ""  CGM_HS,CSM_HS,HMIM_HS,TCP_HS,VLBS_HS,ONSTAR_HS
 SG_ DTCIUnused1_77F : 7|1@0+ (1,0) [0|1] ""  CGM_HS,CSM_HS,HMIM_HS,TCP_HS,VLBS_HS,ONSTAR_HS

BO_ 589 USDT_Req_to_ONS_HS: 8 TestTool_HS
 SG_ DgnInf : 7|64@0+ (1,0) [0|1.8446744074e+19] ""  HMIM_HS,CGM_HS,TCP_HS,VLBS_HS,ONSTAR_HS

BO_ 1357 UUDT_Resp_From_ONS_HS: 8 ONSTAR_HS
 SG_ DgnInf_HS54D : 7|64@0+ (1,0) [0|1.8446744074e+19] ""  CGM_HS,HMIM_HS,CSM_HS,TestTool_HS

BO_ 1613 USDT_Resp_From_ONS_HS: 8 ONSTAR_HS
 SG_ DgnInf : 7|64@0+ (1,0) [0|1.8446744074e+19] ""  CGM_HS,HMIM_HS,CSM_HS,TestTool_HS

BO_ 1606 USDT_Resp_From_APPS_HS: 8 APPS_HS
 SG_ DgnInf : 7|64@0+ (1,0) [0|1.8446744074e+19] ""  HMIM_HS,CSM_HS,CGM_HS,TCP_HS,ONSTAR_HS,TestTool_HS

BO_ 582 USDT_Req_to_APPS_HS: 8 TestTool_HS
 SG_ DgnInf : 7|64@0+ (1,0) [0|1.8446744074e+19] ""  TCP_HS,ONSTAR_HS,HMIM_HS,CGM_HS,APPS_HS

BO_ 590 USDT_Req_to_SADS_HS: 8 TestTool_HS
 SG_ DgnInf : 7|64@0+ (1,0) [0|1.8446744074e+19] ""  TCP_HS,ONSTAR_HS,CGM_HS,HMIM_HS,SADS_HS

BO_ 601 USDT_Req_to_MCP_C_HS: 8 TestTool_HS
 SG_ DgnInf : 7|64@0+ (1,0) [0|1.8446744074e+19] ""  TCP_HS,ONSTAR_HS,CGM_HS,HMIM_HS,MCP_C_HS

BO_ 1369 UUDT_Resp_From_MCP_C_HS: 8 MCP_C_HS
 SG_ DgnInf_HS559 : 7|64@0+ (1,0) [0|1.8446744074e+19] ""  HMIM_HS,CSM_HS,CGM_HS,TCP_HS,ONSTAR_HS,TestTool_HS

BO_ 1625 USDT_Resp_From_MCP_C_HS: 8 MCP_C_HS
 SG_ DgnInf : 7|64@0+ (1,0) [0|1.8446744074e+19] ""  HMIM_HS,CSM_HS,CGM_HS,TCP_HS,ONSTAR_HS,TestTool_HS

BO_ 1356 UUDT_Resp_From_PFAF_HS: 8 EOCM2B_K1_HS
 SG_ DgnInf_HS54C : 7|64@0+ (1,0) [0|1.8446744074e+19] ""  HMIM_HS,CSM_HS,CGM_HS,TCP_HS,ONSTAR_HS,TestTool_HS

BO_ 1358 UUDT_Resp_From_SADS_HS: 8 SADS_HS
 SG_ DgnInf_HS54E : 7|64@0+ (1,0) [0|1.8446744074e+19] ""  HMIM_HS,CSM_HS,CGM_HS,TCP_HS,ONSTAR_HS,TestTool_HS

BO_ 1359 UUDT_Resp_From_RDCM_HS: 8 RDCM_HS
 SG_ DgnInf_HS54F : 7|64@0+ (1,0) [0|1.8446744074e+19] ""  HMIM_HS,CSM_HS,CGM_HS,TCP_HS,ONSTAR_HS,TestTool_HS

BO_ 2023 USDT_Req_to_VITM_HS: 8 TestTool_HS
 SG_ DgnInf : 7|64@0+ (1,0) [0|1.8446744074e+19] ""  TCP_HS,ONSTAR_HS,CGM_HS,HMIM_HS,VITM_OBD_HS

BO_ 2021 USDT_Req_to_OBD_Device5: 8 CGM_HS
 SG_ DgnInf : 7|64@0+ (1,0) [0|1.8446744074e+19] ""  TCP_HS,ONSTAR_HS,CGM_HS,HMIM_HS,EBCM_OBD_HS

BO_ 2017 USDT_Req_to_BCP_HS: 8 TestTool_HS
 SG_ DgnInf : 7|64@0+ (1,0) [0|1.8446744074e+19] ""  TCP_HS,ONSTAR_HS,CGM_HS,HMIM_HS,HCP_B_HS,HCP_T_HS,HCP_HS,BCP_HS

BO_ 2019 USDT_Req_to_ICCM_OBD_HS: 8 TestTool_HS
 SG_ DgnInf : 7|64@0+ (1,0) [0|1.8446744074e+19] ""  TCP_HS,ONSTAR_HS,CGM_HS,HMIM_HS,ICCM_OBD_HS,ICCM_HS

BO_ 585 USDT_Req_to_AFL_AHL_HS: 8 TestTool_HS
 SG_ DgnInf : 7|64@0+ (1,0) [0|1.8446744074e+19] ""  TCP_HS,ONSTAR_HS,HMIM_HS,CGM_HS,AHL_AFL_HS

BO_ 578 USDT_Req_to_EHPS_EPS_HS: 8 TestTool_HS
 SG_ DgnInf : 7|64@0+ (1,0) [0|1.8446744074e+19] ""  TCP_HS,ONSTAR_HS,CGM_HS,HMIM_HS,VES_HS,EPS_HS

BO_ 2022 USDT_Req_to_OBD_Device6: 8 CGM_HS
 SG_ DgnInf : 7|64@0+ (1,0) [0|1.8446744074e+19] ""  TCP_HS,ONSTAR_HS,CGM_HS,HMIM_HS,EBOOST_OBD_HS,FICM_HS,GPCM_HS

BO_ 584 USDT_Req_to_Free_48_HS: 8 CGM_HS
 SG_ DgnInf : 7|64@0+ (1,0) [0|1.8446744074e+19] ""  TCP_HS,ONSTAR_HS,CGM_HS,HMIM_HS,Dummy_HS

BO_ 591 USDT_Req_to_RDCM_HS: 8 TestTool_HS
 SG_ DgnInf : 7|64@0+ (1,0) [0|1.8446744074e+19] ""  TCP_HS,ONSTAR_HS,CGM_HS,HMIM_HS,RDCM_HS

BO_ 581 USDT_Req_to_ALC_HS: 8 TestTool_HS
 SG_ DgnInf : 7|64@0+ (1,0) [0|1.8446744074e+19] ""  TCP_HS,ONSTAR_HS,CGM_HS,HMIM_HS,DEFC_HS,ALC_HS

BO_ 586 USDT_Req_to_SAS_HS: 8 TestTool_HS
 SG_ DgnInf : 7|64@0+ (1,0) [0|1.8446744074e+19] ""  TCP_HS,ONSTAR_HS,CGM_HS,HMIM_HS,SAS_HS

BO_ 588 USDT_Req_to_PFAF_HS: 8 TestTool_HS
 SG_ DgnInf : 7|64@0+ (1,0) [0|1.8446744074e+19] ""  TCP_HS,ONSTAR_HS,HMIM_HS,CGM_HS,PFAF_HS,EOCM2B_K1_HS

BO_ 580 USDT_Req_to_OBCM_HS: 8 TestTool_HS
 SG_ DgnInf : 7|64@0+ (1,0) [0|1.8446744074e+19] ""  TCP_HS,ONSTAR_HS,CGM_HS,HMIM_HS,DCDC_HS

BO_ 499 PPEI_Platform_Trans_Requests: 3 BCM_HS
 SG_ PTShftPtrnOvrdAct : 23|1@0+ (1,0) [0|1] ""  CGM_HS,TCM_HS
 SG_ PFTrnsTUDSecSwSt : 9|2@0+ (1,0) [0|3] ""  CGM_HS,HCP_HS,HCP_T_HS,TCM_HS
 SG_ TrnsPFShftPattSwARC : 7|2@0+ (1,0) [0|3] ""  CGM_HS,HCP_T_HS,ECM_HS,TCM_HS
 SG_ TrnsPFShftPattSw4Act : 2|1@0+ (1,0) [0|1] ""  CGM_HS,HCP_T_HS,ECM_HS,TCM_HS
 SG_ TrnsPFShftPattSw3Act : 3|1@0+ (1,0) [0|1] ""  CGM_HS,HCP_T_HS,ECM_HS,TCM_HS
 SG_ TrnsPFShftPattSw2Act : 4|1@0+ (1,0) [0|1] ""  CGM_HS,HCP_T_HS,ECM_HS,TCM_HS
 SG_ TrnsPFShftPattSw1Act : 5|1@0+ (1,0) [0|1] ""  CGM_HS,HCP_T_HS,ECM_HS,TCM_HS
 SG_ PFTrnsTUDSwStAlvRC : 15|2@0+ (1,0) [0|3] ""  CGM_HS,HCP_HS,HCP_T_HS,TCM_HS
 SG_ PFTrnsTUDSwSt : 11|2@0+ (1,0) [0|3] ""  CGM_HS,HCP_HS,HCP_T_HS,TCM_HS
 SG_ PFTrnsTUDEnSwSt : 13|2@0+ (1,0) [0|3] ""  CGM_HS,HCP_HS,HCP_T_HS,TCM_HS
 SG_ OvrdrvDsblReqd : 0|1@0+ (1,0) [0|1] ""  CGM_HS

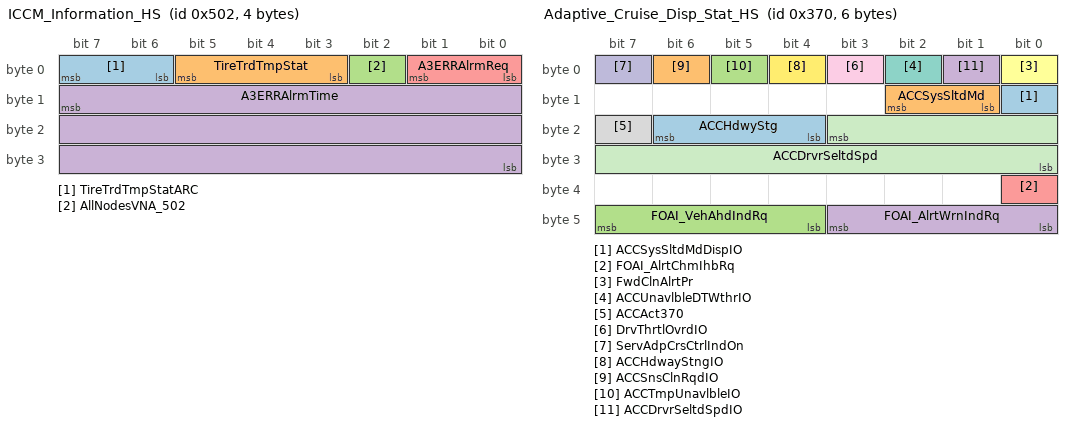
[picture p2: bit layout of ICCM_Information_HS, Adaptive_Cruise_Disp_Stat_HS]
BO_ 1282 ICCM_Information_HS: 4 ALC_HS
 SG_ TireTrdTmpStatARC : 7|2@0+ (1,0) [0|3] ""  CGM_HS,EBCM_OBD_HS,EBCM_HS
 SG_ TireTrdTmpStat : 5|3@0+ (1,0) [0|7] ""  CGM_HS,BCM_HS,EBCM_OBD_HS,EBCM_HS
 SG_ AllNodesVNA_502 : 2|1@0+ (1,0) [0|1] ""  CGM_HS,BCM_HS
 SG_ A3ERRAlrmTime : 15|24@0+ (1,0) [0|16777215] "min"  CGM_HS,BCM_HS
 SG_ A3ERRAlrmReq : 1|2@0+ (1,0) [0|3] ""  CGM_HS,BCM_HS

BO_ 1360 UUDT_Resp_From_AVM_HS: 8 PLCM_HS
 SG_ DgnInf_HS550 : 7|64@0+ (1,0) [0|1.8446744074e+19] ""  HMIM_HS,CSM_HS,CGM_HS,TCP_HS,ONSTAR_HS,TestTool_HS

BO_ 1616 USDT_Resp_From_AVM_HS: 8 PLCM_HS
 SG_ DgnInf : 7|64@0+ (1,0) [0|1.8446744074e+19] ""  HMIM_HS,CSM_HS,CGM_HS,TCP_HS,ONSTAR_HS,TestTool_HS

BO_ 1921 DTC_Triggered_781: 7 APPS_HS
 SG_ DTCI_CurrentStatus_781 : 41|1@0+ (1,0) [0|1] ""  CGM_HS,CSM_HS,HMIM_HS,TCP_HS,VLBS_HS,ONSTAR_HS
 SG_ DTCI_WrnIndRqdSt_781 : 47|1@0+ (1,0) [0|1] ""  CGM_HS,CSM_HS,HMIM_HS,TCP_HS,VLBS_HS,ONSTAR_HS
 SG_ DTCIUnused7_781 : 1|1@0+ (1,0) [0|1] ""  CGM_HS,CSM_HS,HMIM_HS,TCP_HS,VLBS_HS,ONSTAR_HS
 SG_ DTCIUnused6_781 : 2|1@0+ (1,0) [0|1] ""  CGM_HS,CSM_HS,HMIM_HS,TCP_HS,VLBS_HS,ONSTAR_HS
 SG_ DTCIUnused5_781 : 3|1@0+ (1,0) [0|1] ""  CGM_HS,CSM_HS,HMIM_HS,TCP_HS,VLBS_HS,ONSTAR_HS
 SG_ DTCIUnused4_781 : 4|1@0+ (1,0) [0|1] ""  CGM_HS,CSM_HS,HMIM_HS,TCP_HS,VLBS_HS,ONSTAR_HS
 SG_ DTCIUnused3_781 : 5|1@0+ (1,0) [0|1] ""  CGM_HS,CSM_HS,HMIM_HS,TCP_HS,VLBS_HS,ONSTAR_HS
 SG_ DTCIUnused2_781 : 6|1@0+ (1,0) [0|1] ""  CGM_HS,CSM_HS,HMIM_HS,TCP_HS,VLBS_HS,ONSTAR_HS
 SG_ DTCIUnused1_781 : 7|1@0+ (1,0) [0|1] ""  CGM_HS,CSM_HS,HMIM_HS,TCP_HS,VLBS_HS,ONSTAR_HS
 SG_ DTCI_TstNPsdPwrUpSt_781 : 45|1@0+ (1,0) [0|1] ""  CGM_HS,CSM_HS,HMIM_HS,TCP_HS,VLBS_HS,ONSTAR_HS
 SG_ DTCI_TstNPsdCdClrdSt_781 : 42|1@0+ (1,0) [0|1] ""  CGM_HS,CSM_HS,HMIM_HS,TCP_HS,VLBS_HS,ONSTAR_HS
 SG_ DTCI_TstFldPwrUpSt_781 : 46|1@0+ (1,0) [0|1] ""  CGM_HS,CSM_HS,HMIM_HS,TCP_HS,VLBS_HS,ONSTAR_HS
 SG_ DTCI_TstFldCdClrdStat_781 : 43|1@0+ (1,0) [0|1] ""  CGM_HS,CSM_HS,HMIM_HS,TCP_HS,VLBS_HS,ONSTAR_HS
 SG_ DTCI_HistStat_781 : 44|1@0+ (1,0) [0|1] ""  CGM_HS,CSM_HS,HMIM_HS,TCP_HS,VLBS_HS,ONSTAR_HS
 SG_ DTCI_DTCTriggered_781 : 0|1@0+ (1,0) [0|1] ""  CGM_HS,CSM_HS,HMIM_HS,TCP_HS,VLBS_HS,ONSTAR_HS
 SG_ DTCI_DTCSource_781 : 15|8@0+ (1,0) [0|255] ""  CGM_HS,CSM_HS,HMIM_HS,TCP_HS,VLBS_HS,ONSTAR_HS
 SG_ DTCI_DTCNumber_781 : 23|16@0+ (1,0) [0|65535] ""  CGM_HS,CSM_HS,HMIM_HS,TCP_HS,VLBS_HS,ONSTAR_HS
 SG_ DTCI_DTCFaultType_781 : 55|8@0+ (1,0) [0|255] ""  CGM_HS,CSM_HS,HMIM_HS,TCP_HS,VLBS_HS,ONSTAR_HS
 SG_ DTCI_DTCFailType_781 : 39|8@0+ (1,0) [0|255] ""  CGM_HS,CSM_HS,HMIM_HS,TCP_HS,VLBS_HS,ONSTAR_HS
 SG_ DTCI_CodeSupported_781 : 40|1@0+ (1,0) [0|1] ""  CGM_HS,CSM_HS,HMIM_HS,TCP_HS,VLBS_HS,ONSTAR_HS

BO_ 1920 DTC_Triggered_780: 7 EBCM_HS
 SG_ DTCI_CurrentStatus_780 : 41|1@0+ (1,0) [0|1] ""  CGM_HS,CSM_HS,HMIM_HS,TCP_HS,VLBS_HS,ONSTAR_HS
 SG_ DTCI_WrnIndRqdSt_780 : 47|1@0+ (1,0) [0|1] ""  CGM_HS,CSM_HS,HMIM_HS,TCP_HS,VLBS_HS,ONSTAR_HS
 SG_ DTCIUnused7_780 : 1|1@0+ (1,0) [0|1] ""  CGM_HS,CSM_HS,HMIM_HS,TCP_HS,VLBS_HS,ONSTAR_HS
 SG_ DTCIUnused6_780 : 2|1@0+ (1,0) [0|1] ""  CGM_HS,CSM_HS,HMIM_HS,TCP_HS,VLBS_HS,ONSTAR_HS
 SG_ DTCIUnused5_780 : 3|1@0+ (1,0) [0|1] ""  CGM_HS,CSM_HS,HMIM_HS,TCP_HS,VLBS_HS,ONSTAR_HS
 SG_ DTCIUnused4_780 : 4|1@0+ (1,0) [0|1] ""  CGM_HS,CSM_HS,HMIM_HS,TCP_HS,VLBS_HS,ONSTAR_HS
 SG_ DTCIUnused3_780 : 5|1@0+ (1,0) [0|1] ""  CGM_HS,CSM_HS,HMIM_HS,TCP_HS,VLBS_HS,ONSTAR_HS
 SG_ DTCIUnused2_780 : 6|1@0+ (1,0) [0|1] ""  CGM_HS,CSM_HS,HMIM_HS,TCP_HS,VLBS_HS,ONSTAR_HS
 SG_ DTCIUnused1_780 : 7|1@0+ (1,0) [0|1] ""  CGM_HS,CSM_HS,HMIM_HS,TCP_HS,VLBS_HS,ONSTAR_HS
 SG_ DTCI_TstNPsdPwrUpSt_780 : 45|1@0+ (1,0) [0|1] ""  CGM_HS,CSM_HS,HMIM_HS,TCP_HS,VLBS_HS,ONSTAR_HS
 SG_ DTCI_TstNPsdCdClrdSt_780 : 42|1@0+ (1,0) [0|1] ""  CGM_HS,CSM_HS,HMIM_HS,TCP_HS,VLBS_HS,ONSTAR_HS
 SG_ DTCI_TstFldPwrUpSt_780 : 46|1@0+ (1,0) [0|1] ""  CGM_HS,CSM_HS,HMIM_HS,TCP_HS,VLBS_HS,ONSTAR_HS
 SG_ DTCI_TstFldCdClrdStat_780 : 43|1@0+ (1,0) [0|1] ""  CGM_HS,CSM_HS,HMIM_HS,TCP_HS,VLBS_HS,ONSTAR_HS
 SG_ DTCI_HistStat_780 : 44|1@0+ (1,0) [0|1] ""  CGM_HS,CSM_HS,HMIM_HS,TCP_HS,VLBS_HS,ONSTAR_HS
 SG_ DTCI_DTCTriggered_780 : 0|1@0+ (1,0) [0|1] ""  CGM_HS,CSM_HS,HMIM_HS,TCP_HS,VLBS_HS,ONSTAR_HS
 SG_ DTCI_DTCSource_780 : 15|8@0+ (1,0) [0|255] ""  CGM_HS,CSM_HS,HMIM_HS,TCP_HS,VLBS_HS,ONSTAR_HS
 SG_ DTCI_DTCNumber_780 : 23|16@0+ (1,0) [0|65535] ""  CGM_HS,CSM_HS,HMIM_HS,TCP_HS,VLBS_HS,ONSTAR_HS
 SG_ DTCI_DTCFaultType_780 : 55|8@0+ (1,0) [0|255] ""  CGM_HS,CSM_HS,HMIM_HS,TCP_HS,VLBS_HS,ONSTAR_HS
 SG_ DTCI_DTCFailType_780 : 39|8@0+ (1,0) [0|255] ""  CGM_HS,CSM_HS,HMIM_HS,TCP_HS,VLBS_HS,ONSTAR_HS
 SG_ DTCI_CodeSupported_780 : 40|1@0+ (1,0) [0|1] ""  CGM_HS,CSM_HS,HMIM_HS,TCP_HS,VLBS_HS,ONSTAR_HS

BO_ 596 USDT_Req_to_EPB_HS: 8 TestTool_HS
 SG_ DgnInf : 7|64@0+ (1,0) [0|1.8446744074e+19] ""  TCP_HS,ONSTAR_HS,HMIM_HS,CGM_HS,EPB_HS

BO_ 2033 PCU_Req_to_SDM_HS: 8 TestTool_HS
 SG_ PCUInfo : 7|64@0+ (1,0) [0|1.8446744074e+19] ""  CGM_HS,BCM_HS

BO_ 495 PPEI_Fuel_System_Request_2: 4 ECM_HS
 SG_ MassAirFloV : 7|1@0+ (1,0) [0|1] ""  CGM_HS,BSM_HS,VICM_HS
 SG_ MassAirFlo : 23|16@0+ (0.01,0) [0|655.35] "grams/s"  CGM_HS,BSM_HS,VICM_HS

BO_ 1350 UUDT_Resp_From_APPS_HS: 8 APPS_HS
 SG_ DgnInf_HS546 : 7|64@0+ (1,0) [0|1.8446744074e+19] ""  HMIM_HS,CSM_HS,CGM_HS,TCP_HS,ONSTAR_HS,TestTool_HS

BO_ 1914 DTC_Triggered_77A: 7 RDCM_HS
 SG_ DTCI_DTCFaultType_77A : 55|8@0+ (1,0) [0|255] ""  CGM_HS,CSM_HS,HMIM_HS,TCP_HS,VLBS_HS,ONSTAR_HS
 SG_ DTCI_CodeSupported_77A : 40|1@0+ (1,0) [0|1] ""  CGM_HS,CSM_HS,HMIM_HS,TCP_HS,VLBS_HS,ONSTAR_HS
 SG_ DTCI_CurrentStatus_77A : 41|1@0+ (1,0) [0|1] ""  CGM_HS,CSM_HS,HMIM_HS,TCP_HS,VLBS_HS,ONSTAR_HS
 SG_ DTCI_TstNPsdCdClrdSt_77A : 42|1@0+ (1,0) [0|1] ""  CGM_HS,CSM_HS,HMIM_HS,TCP_HS,VLBS_HS,ONSTAR_HS
 SG_ DTCI_TstFldCdClrdStat_77A : 43|1@0+ (1,0) [0|1] ""  CGM_HS,CSM_HS,HMIM_HS,TCP_HS,VLBS_HS,ONSTAR_HS
 SG_ DTCI_HistStat_77A : 44|1@0+ (1,0) [0|1] ""  CGM_HS,CSM_HS,HMIM_HS,TCP_HS,VLBS_HS,ONSTAR_HS
 SG_ DTCI_TstNPsdPwrUpSt_77A : 45|1@0+ (1,0) [0|1] ""  CGM_HS,CSM_HS,HMIM_HS,TCP_HS,VLBS_HS,ONSTAR_HS
 SG_ DTCI_TstFldPwrUpSt_77A : 46|1@0+ (1,0) [0|1] ""  CGM_HS,CSM_HS,HMIM_HS,TCP_HS,VLBS_HS,ONSTAR_HS
 SG_ DTCI_WrnIndRqdSt_77A : 47|1@0+ (1,0) [0|1] ""  CGM_HS,CSM_HS,HMIM_HS,TCP_HS,VLBS_HS,ONSTAR_HS
 SG_ DTCI_DTCFailType_77A : 39|8@0+ (1,0) [0|255] ""  CGM_HS,CSM_HS,HMIM_HS,TCP_HS,VLBS_HS,ONSTAR_HS
 SG_ DTCI_DTCNumber_77A : 23|16@0+ (1,0) [0|65535] ""  CGM_HS,CSM_HS,HMIM_HS,TCP_HS,VLBS_HS,ONSTAR_HS
 SG_ DTCI_DTCSource_77A : 15|8@0+ (1,0) [0|255] ""  CGM_HS,CSM_HS,HMIM_HS,TCP_HS,VLBS_HS,ONSTAR_HS
 SG_ DTCI_DTCTriggered_77A : 0|1@0+ (1,0) [0|1] ""  CGM_HS,CSM_HS,HMIM_HS,TCP_HS,VLBS_HS,ONSTAR_HS
 SG_ DTCIUnused7_77A : 1|1@0+ (1,0) [0|1] ""  CGM_HS,CSM_HS,HMIM_HS,TCP_HS,VLBS_HS,ONSTAR_HS
 SG_ DTCIUnused6_77A : 2|1@0+ (1,0) [0|1] ""  CGM_HS,CSM_HS,HMIM_HS,TCP_HS,VLBS_HS,ONSTAR_HS
 SG_ DTCIUnused5_77A : 3|1@0+ (1,0) [0|1] ""  CGM_HS,CSM_HS,HMIM_HS,TCP_HS,VLBS_HS,ONSTAR_HS
 SG_ DTCIUnused4_77A : 4|1@0+ (1,0) [0|1] ""  CGM_HS,CSM_HS,HMIM_HS,TCP_HS,VLBS_HS,ONSTAR_HS
 SG_ DTCIUnused3_77A : 5|1@0+ (1,0) [0|1] ""  CGM_HS,CSM_HS,HMIM_HS,TCP_HS,VLBS_HS,ONSTAR_HS
 SG_ DTCIUnused2_77A : 6|1@0+ (1,0) [0|1] ""  CGM_HS,CSM_HS,HMIM_HS,TCP_HS,VLBS_HS,ONSTAR_HS
 SG_ DTCIUnused1_77A : 7|1@0+ (1,0) [0|1] ""  CGM_HS,CSM_HS,HMIM_HS,TCP_HS,VLBS_HS,ONSTAR_HS

BO_ 1911 DTC_Triggered_777: 7 PTO_HS
 SG_ DTCI_DTCFaultType_777 : 55|8@0+ (1,0) [0|255] ""  CGM_HS,CSM_HS,HMIM_HS,TCP_HS,VLBS_HS,ONSTAR_HS
 SG_ DTCI_CodeSupported_777 : 40|1@0+ (1,0) [0|1] ""  CGM_HS,CSM_HS,HMIM_HS,TCP_HS,VLBS_HS,ONSTAR_HS
 SG_ DTCI_CurrentStatus_777 : 41|1@0+ (1,0) [0|1] ""  CGM_HS,CSM_HS,HMIM_HS,TCP_HS,VLBS_HS,ONSTAR_HS
 SG_ DTCI_TstNPsdCdClrdSt_777 : 42|1@0+ (1,0) [0|1] ""  CGM_HS,CSM_HS,HMIM_HS,TCP_HS,VLBS_HS,ONSTAR_HS
 SG_ DTCI_TstFldCdClrdStat_777 : 43|1@0+ (1,0) [0|1] ""  CGM_HS,CSM_HS,HMIM_HS,TCP_HS,VLBS_HS,ONSTAR_HS
 SG_ DTCI_HistStat_777 : 44|1@0+ (1,0) [0|1] ""  CGM_HS,CSM_HS,HMIM_HS,TCP_HS,VLBS_HS,ONSTAR_HS
 SG_ DTCI_TstNPsdPwrUpSt_777 : 45|1@0+ (1,0) [0|1] ""  CGM_HS,CSM_HS,HMIM_HS,TCP_HS,VLBS_HS,ONSTAR_HS
 SG_ DTCI_TstFldPwrUpSt_777 : 46|1@0+ (1,0) [0|1] ""  CGM_HS,CSM_HS,HMIM_HS,TCP_HS,VLBS_HS,ONSTAR_HS
 SG_ DTCI_WrnIndRqdSt_777 : 47|1@0+ (1,0) [0|1] ""  CGM_HS,CSM_HS,HMIM_HS,TCP_HS,VLBS_HS,ONSTAR_HS
 SG_ DTCI_DTCFailType_777 : 39|8@0+ (1,0) [0|255] ""  CGM_HS,CSM_HS,HMIM_HS,TCP_HS,VLBS_HS,ONSTAR_HS
 SG_ DTCI_DTCNumber_777 : 23|16@0+ (1,0) [0|65535] ""  CGM_HS,CSM_HS,HMIM_HS,TCP_HS,VLBS_HS,ONSTAR_HS
 SG_ DTCI_DTCSource_777 : 15|8@0+ (1,0) [0|255] ""  CGM_HS,CSM_HS,HMIM_HS,TCP_HS,VLBS_HS,ONSTAR_HS
 SG_ DTCI_DTCTriggered_777 : 0|1@0+ (1,0) [0|1] ""  CGM_HS,CSM_HS,HMIM_HS,TCP_HS,VLBS_HS,ONSTAR_HS
 SG_ DTCIUnused7_777 : 1|1@0+ (1,0) [0|1] ""  CGM_HS,CSM_HS,HMIM_HS,TCP_HS,VLBS_HS,ONSTAR_HS
 SG_ DTCIUnused6_777 : 2|1@0+ (1,0) [0|1] ""  CGM_HS,CSM_HS,HMIM_HS,TCP_HS,VLBS_HS,ONSTAR_HS
 SG_ DTCIUnused5_777 : 3|1@0+ (1,0) [0|1] ""  CGM_HS,CSM_HS,HMIM_HS,TCP_HS,VLBS_HS,ONSTAR_HS
 SG_ DTCIUnused4_777 : 4|1@0+ (1,0) [0|1] ""  CGM_HS,CSM_HS,HMIM_HS,TCP_HS,VLBS_HS,ONSTAR_HS
 SG_ DTCIUnused3_777 : 5|1@0+ (1,0) [0|1] ""  CGM_HS,CSM_HS,HMIM_HS,TCP_HS,VLBS_HS,ONSTAR_HS
 SG_ DTCIUnused2_777 : 6|1@0+ (1,0) [0|1] ""  CGM_HS,CSM_HS,HMIM_HS,TCP_HS,VLBS_HS,ONSTAR_HS
 SG_ DTCIUnused1_777 : 7|1@0+ (1,0) [0|1] ""  CGM_HS,CSM_HS,HMIM_HS,TCP_HS,VLBS_HS,ONSTAR_HS

BO_ 583 USDT_Req_to_PTO_HS: 8 TestTool_HS
 SG_ DgnInf : 7|64@0+ (1,0) [0|1.8446744074e+19] ""  TCP_HS,ONSTAR_HS,HMIM_HS,CGM_HS,V2V_HS,PTO_HS

BO_ 1351 UUDT_Resp_From_PTO: 8 PTO_HS
 SG_ DgnInf_HS547 : 7|64@0+ (1,0) [0|1.8446744074e+19] ""  HMIM_HS,CSM_HS,CGM_HS,TCP_HS,ONSTAR_HS,TestTool_HS

BO_ 1607 USDT_Resp_From_PTO_HS: 8 PTO_HS
 SG_ DgnInf : 7|64@0+ (1,0) [0|1.8446744074e+19] ""  HMIM_HS,CSM_HS,CGM_HS,TCP_HS,ONSTAR_HS,TestTool_HS

BO_ 1906 DTC_Triggered_772: 7 ECM_HS
 SG_ DTCI_DTCFaultType_772 : 55|8@0+ (1,0) [0|255] ""  CGM_HS,CSM_HS,HMIM_HS,TCP_HS,VLBS_HS,ONSTAR_HS
 SG_ DTCI_CodeSupported_772 : 40|1@0+ (1,0) [0|1] ""  CGM_HS,CSM_HS,HMIM_HS,TCP_HS,VLBS_HS,ONSTAR_HS
 SG_ DTCI_CurrentStatus_772 : 41|1@0+ (1,0) [0|1] ""  CGM_HS,CSM_HS,HMIM_HS,TCP_HS,VLBS_HS,ONSTAR_HS
 SG_ DTCI_TstNPsdCdClrdSt_772 : 42|1@0+ (1,0) [0|1] ""  CGM_HS,CSM_HS,HMIM_HS,TCP_HS,VLBS_HS,ONSTAR_HS
 SG_ DTCI_TstFldCdClrdStat_772 : 43|1@0+ (1,0) [0|1] ""  CGM_HS,CSM_HS,HMIM_HS,TCP_HS,VLBS_HS,ONSTAR_HS
 SG_ DTCI_HistStat_772 : 44|1@0+ (1,0) [0|1] ""  CGM_HS,CSM_HS,HMIM_HS,TCP_HS,VLBS_HS,ONSTAR_HS
 SG_ DTCI_TstNPsdPwrUpSt_772 : 45|1@0+ (1,0) [0|1] ""  CGM_HS,CSM_HS,HMIM_HS,TCP_HS,VLBS_HS,ONSTAR_HS
 SG_ DTCI_TstFldPwrUpSt_772 : 46|1@0+ (1,0) [0|1] ""  CGM_HS,CSM_HS,HMIM_HS,TCP_HS,VLBS_HS,ONSTAR_HS
 SG_ DTCI_WrnIndRqdSt_772 : 47|1@0+ (1,0) [0|1] ""  CGM_HS,CSM_HS,HMIM_HS,TCP_HS,VLBS_HS,ONSTAR_HS
 SG_ DTCI_DTCFailType_772 : 39|8@0+ (1,0) [0|255] ""  CGM_HS,CSM_HS,HMIM_HS,TCP_HS,VLBS_HS,ONSTAR_HS
 SG_ DTCI_DTCNumber_772 : 23|16@0+ (1,0) [0|65535] ""  CGM_HS,CSM_HS,HMIM_HS,TCP_HS,VLBS_HS,ONSTAR_HS
 SG_ DTCI_DTCSource_772 : 15|8@0+ (1,0) [0|255] ""  CGM_HS,CSM_HS,HMIM_HS,TCP_HS,VLBS_HS,ONSTAR_HS
 SG_ DTCI_DTCTriggered_772 : 0|1@0+ (1,0) [0|1] ""  CGM_HS,CSM_HS,HMIM_HS,TCP_HS,VLBS_HS,ONSTAR_HS
 SG_ DTCIUnused7_772 : 1|1@0+ (1,0) [0|1] ""  CGM_HS,CSM_HS,HMIM_HS,TCP_HS,VLBS_HS,ONSTAR_HS
 SG_ DTCIUnused6_772 : 2|1@0+ (1,0) [0|1] ""  CGM_HS,CSM_HS,HMIM_HS,TCP_HS,VLBS_HS,ONSTAR_HS
 SG_ DTCIUnused5_772 : 3|1@0+ (1,0) [0|1] ""  CGM_HS,CSM_HS,HMIM_HS,TCP_HS,VLBS_HS,ONSTAR_HS
 SG_ DTCIUnused4_772 : 4|1@0+ (1,0) [0|1] ""  CGM_HS,CSM_HS,HMIM_HS,TCP_HS,VLBS_HS,ONSTAR_HS
 SG_ DTCIUnused3_772 : 5|1@0+ (1,0) [0|1] ""  CGM_HS,CSM_HS,HMIM_HS,TCP_HS,VLBS_HS,ONSTAR_HS
 SG_ DTCIUnused2_772 : 6|1@0+ (1,0) [0|1] ""  CGM_HS,CSM_HS,HMIM_HS,TCP_HS,VLBS_HS,ONSTAR_HS
 SG_ DTCIUnused1_772 : 7|1@0+ (1,0) [0|1] ""  CGM_HS,CSM_HS,HMIM_HS,TCP_HS,VLBS_HS,ONSTAR_HS

BO_ 1907 DTC_Triggered_773: 7 EBCM_HS
 SG_ DTCI_DTCFaultType_773 : 55|8@0+ (1,0) [0|255] ""  CGM_HS,CSM_HS,HMIM_HS,TCP_HS,VLBS_HS,ONSTAR_HS
 SG_ DTCI_CodeSupported_773 : 40|1@0+ (1,0) [0|1] ""  CGM_HS,CSM_HS,HMIM_HS,TCP_HS,VLBS_HS,ONSTAR_HS
 SG_ DTCI_CurrentStatus_773 : 41|1@0+ (1,0) [0|1] ""  CGM_HS,CSM_HS,HMIM_HS,TCP_HS,VLBS_HS,ONSTAR_HS
 SG_ DTCI_TstNPsdCdClrdSt_773 : 42|1@0+ (1,0) [0|1] ""  CGM_HS,CSM_HS,HMIM_HS,TCP_HS,VLBS_HS,ONSTAR_HS
 SG_ DTCI_TstFldCdClrdStat_773 : 43|1@0+ (1,0) [0|1] ""  CGM_HS,CSM_HS,HMIM_HS,TCP_HS,VLBS_HS,ONSTAR_HS
 SG_ DTCI_HistStat_773 : 44|1@0+ (1,0) [0|1] ""  CGM_HS,CSM_HS,HMIM_HS,TCP_HS,VLBS_HS,ONSTAR_HS
 SG_ DTCI_TstNPsdPwrUpSt_773 : 45|1@0+ (1,0) [0|1] ""  CGM_HS,CSM_HS,HMIM_HS,TCP_HS,VLBS_HS,ONSTAR_HS
 SG_ DTCI_TstFldPwrUpSt_773 : 46|1@0+ (1,0) [0|1] ""  CGM_HS,CSM_HS,HMIM_HS,TCP_HS,VLBS_HS,ONSTAR_HS
 SG_ DTCI_WrnIndRqdSt_773 : 47|1@0+ (1,0) [0|1] ""  CGM_HS,CSM_HS,HMIM_HS,TCP_HS,VLBS_HS,ONSTAR_HS
 SG_ DTCI_DTCFailType_773 : 39|8@0+ (1,0) [0|255] ""  CGM_HS,CSM_HS,HMIM_HS,TCP_HS,VLBS_HS,ONSTAR_HS
 SG_ DTCI_DTCNumber_773 : 23|16@0+ (1,0) [0|65535] ""  CGM_HS,CSM_HS,HMIM_HS,TCP_HS,VLBS_HS,ONSTAR_HS
 SG_ DTCI_DTCSource_773 : 15|8@0+ (1,0) [0|255] ""  CGM_HS,CSM_HS,HMIM_HS,TCP_HS,VLBS_HS,ONSTAR_HS
 SG_ DTCI_DTCTriggered_773 : 0|1@0+ (1,0) [0|1] ""  CGM_HS,CSM_HS,HMIM_HS,TCP_HS,VLBS_HS,ONSTAR_HS
 SG_ DTCIUnused7_773 : 1|1@0+ (1,0) [0|1] ""  CGM_HS,CSM_HS,HMIM_HS,TCP_HS,VLBS_HS,ONSTAR_HS
 SG_ DTCIUnused6_773 : 2|1@0+ (1,0) [0|1] ""  CGM_HS,CSM_HS,HMIM_HS,TCP_HS,VLBS_HS,ONSTAR_HS
 SG_ DTCIUnused5_773 : 3|1@0+ (1,0) [0|1] ""  CGM_HS,CSM_HS,HMIM_HS,TCP_HS,VLBS_HS,ONSTAR_HS
 SG_ DTCIUnused4_773 : 4|1@0+ (1,0) [0|1] ""  CGM_HS,CSM_HS,HMIM_HS,TCP_HS,VLBS_HS,ONSTAR_HS
 SG_ DTCIUnused3_773 : 5|1@0+ (1,0) [0|1] ""  CGM_HS,CSM_HS,HMIM_HS,TCP_HS,VLBS_HS,ONSTAR_HS
 SG_ DTCIUnused2_773 : 6|1@0+ (1,0) [0|1] ""  CGM_HS,CSM_HS,HMIM_HS,TCP_HS,VLBS_HS,ONSTAR_HS
 SG_ DTCIUnused1_773 : 7|1@0+ (1,0) [0|1] ""  CGM_HS,CSM_HS,HMIM_HS,TCP_HS,VLBS_HS,ONSTAR_HS

BO_ 579 USDT_Req_to_EBCM_HPCC_HS: 8 TestTool_HS
 SG_ DgnInf : 7|64@0+ (1,0) [0|1.8446744074e+19] ""  TCP_HS,ONSTAR_HS,CGM_HS,HMIM_HS,EBCM_HS

BO_ 1603 USDT_Resp_From_EBCM_HPCC_HS: 8 EBCM_HS
 SG_ DgnInf : 7|64@0+ (1,0) [0|1.8446744074e+19] ""  HMIM_HS,CSM_HS,CGM_HS,TCP_HS,ONSTAR_HS,TestTool_HS

BO_ 1347 UUDT_Resp_From_EBCM_HPCC_HS: 8 EBCM_HS
 SG_ DgnInf_HS543 : 7|64@0+ (1,0) [0|1.8446744074e+19] ""  HMIM_HS,CSM_HS,CGM_HS,TCP_HS,ONSTAR_HS,TestTool_HS

BO_ 1915 DTC_Triggered_77B: 7 ACC_HS
 SG_ DTCI_DTCFaultType_77B : 55|8@0+ (1,0) [0|255] ""  CGM_HS,CSM_HS,HMIM_HS,TCP_HS,VLBS_HS,ONSTAR_HS
 SG_ DTCI_CodeSupported_77B : 40|1@0+ (1,0) [0|1] ""  CGM_HS,CSM_HS,HMIM_HS,TCP_HS,VLBS_HS,ONSTAR_HS
 SG_ DTCI_CurrentStatus_77B : 41|1@0+ (1,0) [0|1] ""  CGM_HS,CSM_HS,HMIM_HS,TCP_HS,VLBS_HS,ONSTAR_HS
 SG_ DTCI_TstNPsdCdClrdSt_77B : 42|1@0+ (1,0) [0|1] ""  CGM_HS,CSM_HS,HMIM_HS,TCP_HS,VLBS_HS,ONSTAR_HS
 SG_ DTCI_TstFldCdClrdStat_77B : 43|1@0+ (1,0) [0|1] ""  CGM_HS,CSM_HS,HMIM_HS,TCP_HS,VLBS_HS,ONSTAR_HS
 SG_ DTCI_HistStat_77B : 44|1@0+ (1,0) [0|1] ""  CGM_HS,CSM_HS,HMIM_HS,TCP_HS,VLBS_HS,ONSTAR_HS
 SG_ DTCI_TstNPsdPwrUpSt_77B : 45|1@0+ (1,0) [0|1] ""  CGM_HS,CSM_HS,HMIM_HS,TCP_HS,VLBS_HS,ONSTAR_HS
 SG_ DTCI_TstFldPwrUpSt_77B : 46|1@0+ (1,0) [0|1] ""  CGM_HS,CSM_HS,HMIM_HS,TCP_HS,VLBS_HS,ONSTAR_HS
 SG_ DTCI_WrnIndRqdSt_77B : 47|1@0+ (1,0) [0|1] ""  CGM_HS,CSM_HS,HMIM_HS,TCP_HS,VLBS_HS,ONSTAR_HS
 SG_ DTCI_DTCFailType_77B : 39|8@0+ (1,0) [0|255] ""  CGM_HS,CSM_HS,HMIM_HS,TCP_HS,VLBS_HS,ONSTAR_HS
 SG_ DTCI_DTCNumber_77B : 23|16@0+ (1,0) [0|65535] ""  CGM_HS,CSM_HS,HMIM_HS,TCP_HS,VLBS_HS,ONSTAR_HS
 SG_ DTCI_DTCSource_77B : 15|8@0+ (1,0) [0|255] ""  CGM_HS,CSM_HS,HMIM_HS,TCP_HS,VLBS_HS,ONSTAR_HS
 SG_ DTCI_DTCTriggered_77B : 0|1@0+ (1,0) [0|1] ""  CGM_HS,CSM_HS,HMIM_HS,TCP_HS,VLBS_HS,ONSTAR_HS
 SG_ DTCIUnused7_77B : 1|1@0+ (1,0) [0|1] ""  CGM_HS,CSM_HS,HMIM_HS,TCP_HS,VLBS_HS,ONSTAR_HS
 SG_ DTCIUnused6_77B : 2|1@0+ (1,0) [0|1] ""  CGM_HS,CSM_HS,HMIM_HS,TCP_HS,VLBS_HS,ONSTAR_HS
 SG_ DTCIUnused5_77B : 3|1@0+ (1,0) [0|1] ""  CGM_HS,CSM_HS,HMIM_HS,TCP_HS,VLBS_HS,ONSTAR_HS
 SG_ DTCIUnused4_77B : 4|1@0+ (1,0) [0|1] ""  CGM_HS,CSM_HS,HMIM_HS,TCP_HS,VLBS_HS,ONSTAR_HS
 SG_ DTCIUnused3_77B : 5|1@0+ (1,0) [0|1] ""  CGM_HS,CSM_HS,HMIM_HS,TCP_HS,VLBS_HS,ONSTAR_HS
 SG_ DTCIUnused2_77B : 6|1@0+ (1,0) [0|1] ""  CGM_HS,CSM_HS,HMIM_HS,TCP_HS,VLBS_HS,ONSTAR_HS
 SG_ DTCIUnused1_77B : 7|1@0+ (1,0) [0|1] ""  CGM_HS,CSM_HS,HMIM_HS,TCP_HS,VLBS_HS,ONSTAR_HS

BO_ 587 USDT_Req_to_EOCM_FCM_HS: 8 TestTool_HS
 SG_ DgnInf : 7|64@0+ (1,0) [0|1.8446744074e+19] ""  TCP_HS,ONSTAR_HS,HMIM_HS,CGM_HS,EOCM2A_K1_HS,EOCM_F_HS,FCM_HS

BO_ 1611 USDT_Resp_From_EOCM_FCM_HS: 8 FCM_HS
 SG_ DgnInf : 7|64@0+ (1,0) [0|1.8446744074e+19] ""  HMIM_HS,CSM_HS,CGM_HS,TCP_HS,ONSTAR_HS,TestTool_HS

BO_ 1355 UUDT_Resp_From_EOCM_FCM_HS: 8 FCM_HS
 SG_ DgnInf_HS54B : 7|64@0+ (1,0) [0|1.8446744074e+19] ""  HMIM_HS,CSM_HS,CGM_HS,TCP_HS,ONSTAR_HS,TestTool_HS

BO_ 880 Adaptive_Cruise_Disp_Stat_HS: 6 ACC_HS
 SG_ ACCSysSltdMdDispIO : 8|1@0+ (1,0) [0|1] ""  BCM_HS,EOCM2B_K1_HS
 SG_ ACCSysSltdMd : 10|2@0+ (1,0) [0|3] ""  BCM_HS,EOCM2B_K1_HS
 SG_ FOAI_VehAhdIndRq : 47|4@0+ (1,0) [0|15] ""  EOCM2B_K1_HS,BCM_HS
 SG_ FOAI_AlrtWrnIndRq : 43|4@0+ (1,0) [0|15] ""  EOCM2B_K1_HS,BCM_HS
 SG_ FOAI_AlrtChmIhbRq : 32|1@0+ (1,0) [0|1] ""  EOCM2B_K1_HS,BCM_HS
 SG_ FwdClnAlrtPr : 0|1@0+ (1,0) [0|1] ""  EOCM2B_K1_HS,BCM_HS
 SG_ ACCUnavlbleDTWthrIO : 2|1@0+ (1,0) [0|1] ""  EOCM2B_K1_HS,BCM_HS
 SG_ ACCAct370 : 23|1@0+ (1,0) [0|1] ""  EOCM2B_K1_HS,EBCM_OBD_HS,EBCM_HS,TCM_HS,BCM_HS
 SG_ DrvThrtlOvrdIO : 3|1@0+ (1,0) [0|1] ""  EOCM2B_K1_HS,BCM_HS
 SG_ ServAdpCrsCtrlIndOn : 7|1@0+ (1,0) [0|1] ""  EOCM2B_K1_HS,BCM_HS
 SG_ ACCDrvrSeltdSpd : 19|12@0+ (0.0625,0) [0|255.9375] "km / h"  EOCM2B_K1_HS,ECM_HS,BCM_HS
 SG_ ACCHdwayStngIO : 4|1@0+ (1,0) [0|1] ""  EOCM2B_K1_HS,BCM_HS
 SG_ ACCHdwyStg : 22|3@0+ (1,0) [0|7] ""  EOCM2B_K1_HS,BCM_HS
 SG_ ACCSnsClnRqdIO : 6|1@0+ (1,0) [0|1] ""  EOCM2B_K1_HS,BCM_HS
 SG_ ACCTmpUnavlbleIO : 5|1@0+ (1,0) [0|1] ""  EOCM2B_K1_HS,BCM_HS
 SG_ ACCDrvrSeltdSpdIO : 1|1@0+ (1,0) [0|1] ""  EOCM2B_K1_HS,BCM_HS

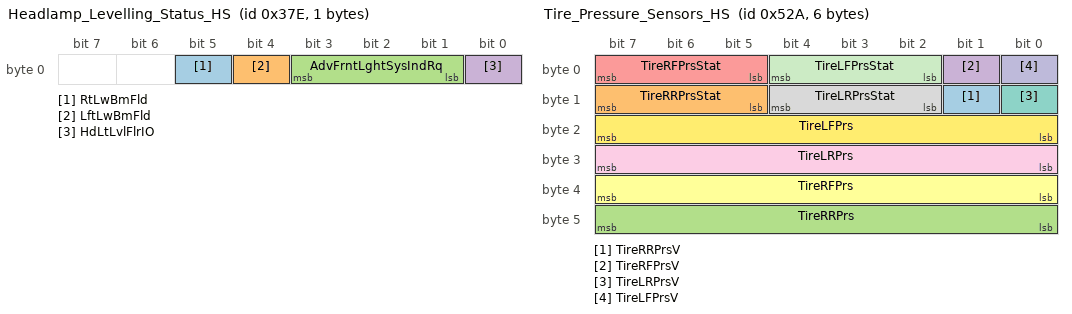
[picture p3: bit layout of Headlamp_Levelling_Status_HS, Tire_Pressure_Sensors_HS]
BO_ 894 Headlamp_Levelling_Status_HS: 1 AHL_AFL_HS
 SG_ RtLwBmFld : 5|1@0+ (1,0) [0|1] ""  EOCM2B_IMX6_HS,EOCM2A_IMX6_HS,EOCM2A_K1_HS,EOCM_F_HS,BCM_HS
 SG_ LftLwBmFld : 4|1@0+ (1,0) [0|1] ""  EOCM2B_IMX6_HS,EOCM2A_IMX6_HS,EOCM2A_K1_HS,EOCM_F_HS,BCM_HS
 SG_ AdvFrntLghtSysIndRq : 3|3@0+ (1,0) [0|7] ""  BCM_HS
 SG_ HdLtLvlFlrIO : 0|1@0+ (1,0) [0|1] ""  BCM_HS

BO_ 577 USDT_Req_to_BCM_HS: 8 TestTool_HS
 SG_ DgnInf : 7|64@0+ (1,0) [0|1.8446744074e+19] ""  TCP_HS,ONSTAR_HS,CGM_HS,HMIM_HS,BCM_HS

BO_ 298 Body_Information_HS: 8 BCM_HS
 SG_ DrvrDrAjrSwVDA : 58|1@0+ (1,0) [0|1] ""  HCP_T_HS,ECM_HS,ICCM_HS,CGM_HS
 SG_ ValetMdAct : 59|1@0+ (1,0) [0|1] ""  EBCM_OBD_HS,EBCM_HS,CGM_HS
 SG_ AutoMdSpdLmtCnfrmd : 57|1@0+ (1,0) [0|1] ""  EOCM2B_IMX6_HS,EOCM2A_IMX6_HS,FCM_HS,EOCM2B_K1_HS,EOCM2A_K1_HS,EOCM_F_HS,ACC_HS,CGM_HS,ECM_HS
 SG_ TCSysDisSwAtvARC : 61|2@0+ (1,0) [0|3] ""  EOCM2B_IMX6_HS,EOCM2A_IMX6_HS,EOCM2B_K1_HS,EOCM2A_K1_HS,CGM_HS,ECM_HS,EBCM_OBD_HS,EBCM_HS
 SG_ TCSysDisSwAtv_12A : 62|1@0+ (1,0) [0|1] ""  EOCM2B_IMX6_HS,EOCM2A_IMX6_HS,EOCM2B_K1_HS,EOCM2A_K1_HS,CGM_HS,ECM_HS
 SG_ ChmAct : 55|1@0+ (1,0) [0|1] ""  EOCM2B_IMX6_HS,EOCM2A_IMX6_HS,EOCM2B_K1_HS,EOCM2A_K1_HS,CGM_HS,ACC_HS
 SG_ Ky_IdDevPr : 56|1@0+ (1,0) [0|1] ""  EOCM2B_IMX6_HS,EOCM2A_IMX6_HS,EOCM2B_K1_HS,EOCM2A_K1_HS,CGM_HS,EBCM_OBD_HS,EBCM_HS,EPB_HS
 SG_ DDAjrSwAtvM : 63|1@0+ (1,0) [0|1] ""  EOCM2B_IMX6_HS,EOCM2A_IMX6_HS,PTO_HS,ICCM_HS,EOCM2B_K1_HS,EOCM2A_K1_HS,CGM_HS,EBCM_OBD_HS,EBCM_HS,ECM_HS,ACC_HS
 SG_ CrshAlrtDrvrSlctdType : 5|1@0+ (1,0) [0|1] ""  EOCM2B_IMX6_HS,EOCM2A_IMX6_HS,EOCM2B_K1_HS,EOCM2A_K1_HS,CGM_HS,EBCM_OBD_HS,EBCM_HS,ACC_HS
 SG_ PsSbltAtcV : 54|1@0+ (1,0) [0|1] ""  EOCM2B_IMX6_HS,EOCM2A_IMX6_HS,EOCM2B_K1_HS,EOCM2A_K1_HS,CGM_HS,EBCM_OBD_HS,EBCM_HS
 SG_ PsSbltAtc : 53|1@0+ (1,0) [0|1] ""  EOCM2B_IMX6_HS,EOCM2A_IMX6_HS,EOCM2B_K1_HS,EOCM2A_K1_HS,CGM_HS,EBCM_OBD_HS,EBCM_HS
 SG_ TrlrBrkDsplyAct : 51|1@0+ (1,0) [0|1] ""  EOCM2B_IMX6_HS,EOCM2A_IMX6_HS,EBCM_OBD_HS,EBCM_HS,EOCM2B_K1_HS,EOCM2A_K1_HS,CGM_HS,ICCM_B_HS,ICCM_OBD_HS,ICCM_HS
 SG_ RdSpdCatType : 45|2@0+ (1,0) [0|3] ""  EOCM2B_IMX6_HS,EOCM2A_IMX6_HS,EOCM2B_K1_HS,EOCM2A_K1_HS,CGM_HS,FCM_HS,AHL_AFL_HS
 SG_ LnCat : 47|2@0+ (1,0) [0|3] ""  EOCM2B_IMX6_HS,EOCM2A_IMX6_HS,EOCM2B_K1_HS,EOCM2A_K1_HS,CGM_HS,FCM_HS,AHL_AFL_HS
 SG_ FncRdClass : 50|3@0+ (1,0) [0|7] ""  EOCM2B_IMX6_HS,EOCM2A_IMX6_HS,EOCM2B_K1_HS,EOCM2A_K1_HS,CGM_HS,FCM_HS,AHL_AFL_HS
 SG_ SprtLnRd : 43|1@0+ (1,0) [0|1] ""  EOCM2B_IMX6_HS,EOCM2A_IMX6_HS,EOCM2B_K1_HS,EOCM2A_K1_HS,CGM_HS,FCM_HS,AHL_AFL_HS
 SG_ CntrldAccRd : 39|1@0+ (1,0) [0|1] ""  EOCM2B_IMX6_HS,EOCM2A_IMX6_HS,EOCM2B_K1_HS,EOCM2A_K1_HS,CGM_HS,FCM_HS,AHL_AFL_HS
 SG_ BldUpArDet : 11|1@0+ (1,0) [0|1] ""  EOCM2B_IMX6_HS,EOCM2A_IMX6_HS,EOCM2B_K1_HS,EOCM2A_K1_HS,CGM_HS,FCM_HS,AHL_AFL_HS
 SG_ MpDataAvlbl : 3|1@0+ (1,0) [0|1] ""  EOCM2B_IMX6_HS,EOCM2A_IMX6_HS,EOCM2B_K1_HS,EOCM2A_K1_HS,CGM_HS,FCM_HS,AHL_AFL_HS
 SG_ SusCustStngReq : 42|3@0+ (1,0) [0|7] ""  EOCM2B_IMX6_HS,EOCM2A_IMX6_HS,EOCM2B_K1_HS,EOCM2A_K1_HS,CGM_HS,EBCM_OBD_HS,EBCM_HS
 SG_ StrCustStngReq : 38|3@0+ (1,0) [0|7] ""  EOCM2B_IMX6_HS,EOCM2A_IMX6_HS,EOCM2B_K1_HS,EOCM2A_K1_HS,CGM_HS,EBCM_OBD_HS,EBCM_HS
 SG_ RstrCustFctrDef : 35|1@0+ (1,0) [0|1] ""  EOCM2B_IMX6_HS,EOCM2A_IMX6_HS,EOCM2B_K1_HS,EOCM2A_K1_HS,CGM_HS,AHL_AFL_HS,EBCM_OBD_HS,EBCM_HS
 SG_ DrvlnCustStngReq : 34|3@0+ (1,0) [0|7] ""  EOCM2B_IMX6_HS,EOCM2A_IMX6_HS,EOCM2B_K1_HS,EOCM2A_K1_HS,CGM_HS,EBCM_OBD_HS,EBCM_HS
 SG_ ChmMstrVDA : 22|1@0+ (1,0) [0|1] ""  EOCM2B_IMX6_HS,EOCM2A_IMX6_HS,EOCM2B_K1_HS,EOCM2A_K1_HS,CGM_HS,EOCM_F_HS,FCM_HS,ACC_HS
 SG_ IPCVDA : 21|1@0+ (1,0) [0|1] ""  EOCM2B_IMX6_HS,EOCM2A_IMX6_HS,FCM_HS,EOCM2B_K1_HS,EOCM2A_K1_HS,CGM_HS,EOCM_F_HS,ACC_HS,EBCM_OBD_HS,EBCM_HS
 SG_ HeadUpDispVDA : 20|1@0+ (1,0) [0|1] ""  EOCM2B_IMX6_HS,EOCM2A_IMX6_HS,EOCM2B_K1_HS,EOCM2A_K1_HS,CGM_HS,EOCM_F_HS,ACC_HS
 SG_ HapticSeatVDA : 52|1@0+ (1,0) [0|1] ""  EOCM2B_IMX6_HS,EOCM2A_IMX6_HS,EOCM2B_K1_HS,EOCM2A_K1_HS,CGM_HS,ACC_HS
 SG_ RRDoorAjarSwAct : 23|1@0+ (1,0) [0|1] ""  EOCM2B_IMX6_HS,EOCM2A_IMX6_HS,EOCM_F_HS,EOCM2B_K1_HS,EOCM2A_K1_HS,CGM_HS,ICCM_B_HS,ICCM_OBD_HS,ICCM_HS,ALC_HS,EPB_HS,SADS_HS
 SG_ PDAjrSwAtv : 10|1@0+ (1,0) [0|1] ""  EOCM2B_IMX6_HS,EOCM2A_IMX6_HS,EOCM_F_HS,EOCM2B_K1_HS,EOCM2A_K1_HS,CGM_HS,EPB_HS,ICCM_B_HS,ICCM_OBD_HS,ICCM_HS,ALC_HS,SADS_HS
 SG_ DDAjrSwAtv : 9|1@0+ (1,0) [0|1] ""  EOCM2B_IMX6_HS,EOCM2A_IMX6_HS,HCP_T_HS,PTO_HS,EOCM2B_K1_HS,EOCM2A_K1_HS,CGM_HS,ECM_HS,EBCM_OBD_HS,EBCM_HS,ACC_HS,EPB_HS,ICCM_B_HS,ICCM_OBD_HS,ICCM_HS,ALC_HS,SADS_HS
 SG_ TrlrHWIntrfcVDA : 4|1@0+ (1,0) [0|1] ""  EOCM2B_IMX6_HS,EOCM2A_IMX6_HS,AHL_AFL_HS,EOCM2B_K1_HS,EOCM2A_K1_HS,CGM_HS,EBCM_OBD_HS,EBCM_HS,RDCM_HS
 SG_ DrId : 15|3@0+ (1,0) [0|7] ""  EOCM2B_IMX6_HS,EOCM2A_IMX6_HS,EOCM2B_K1_HS,EOCM2A_K1_HS,CGM_HS,EBCM_OBD_HS,EBCM_HS,ACC_HS
 SG_ EnrgMgtLdShdRq : 19|4@0+ (1,0) [0|15] ""  EOCM2B_IMX6_HS,EOCM2A_IMX6_HS,EOCM2B_K1_HS,EOCM2A_K1_HS,CGM_HS,PTO_HS,ICCM_B_HS,ICCM_OBD_HS,ICCM_HS,ALC_HS,SADS_HS
 SG_ DrSbltAtcV : 2|1@0+ (1,0) [0|1] ""  EOCM2B_IMX6_HS,EOCM2A_IMX6_HS,HCP_T_HS,ICCM_HS,EOCM2B_K1_HS,EOCM2A_K1_HS,CGM_HS,ECM_HS,ACC_HS,EPB_HS,EBCM_OBD_HS,EBCM_HS
 SG_ TrlrHtchSwAtv : 0|1@0+ (1,0) [0|1] ""  EOCM2B_IMX6_HS,EOCM2A_IMX6_HS,AHL_AFL_HS,EOCM2B_K1_HS,EOCM2A_K1_HS,CGM_HS,ECM_HS,EBCM_OBD_HS,EBCM_HS,RDCM_HS
 SG_ TreInfMonSysRstReq : 7|1@0+ (1,0) [0|1] ""  EOCM2B_IMX6_HS,EOCM2A_IMX6_HS,EOCM2B_K1_HS,EOCM2A_K1_HS,CGM_HS,EBCM_OBD_HS,EBCM_HS
 SG_ HUDActv : 6|1@0+ (1,0) [0|1] ""  EOCM2B_IMX6_HS,EOCM2A_IMX6_HS,EOCM2B_K1_HS,EOCM2A_K1_HS,CGM_HS,ACC_HS
 SG_ BatVltV : 1|1@0+ (1,0) [0|1] ""  EOCM2B_IMX6_HS,EOCM2A_IMX6_HS,EOCM2B_K1_HS,EOCM2A_K1_HS,CGM_HS,FICM_HS,LVMPC_HS,EDI_HS,TCM_HS,HCP_HS,BCP_HS,MCP_C_HS,MCP_B_HS,MCP_A_HS,ECM_HS,EPB_HS,ICCM_B_HS,ICCM_OBD_HS,ICCM_HS,ALC_HS,SADS_HS
 SG_ BatVlt : 31|8@0+ (0.1,3) [3|28.5] "volts"  EOCM2B_IMX6_HS,EOCM2A_IMX6_HS,EOCM2B_K1_HS,EOCM2A_K1_HS,HCP_B_HS,CGM_HS,FICM_HS,HCP_T_HS,LVMPC_HS,EDI_HS,TCM_HS,HCP_HS,BCP_HS,MCP_C_HS,MCP_B_HS,MCP_A_HS,ECM_HS,EPB_HS,ICCM_B_HS,ICCM_OBD_HS,ICCM_HS,ALC_HS,SADS_HS
 SG_ RLDoorAjarSwAct : 8|1@0+ (1,0) [0|1] ""  EOCM2B_IMX6_HS,EOCM2A_IMX6_HS,EOCM_F_HS,EOCM2B_K1_HS,EOCM2A_K1_HS,CGM_HS,ICCM_B_HS,ICCM_OBD_HS,ICCM_HS,ALC_HS,EPB_HS,SADS_HS
 SG_ DrSbltAtc : 12|1@0+ (1,0) [0|1] ""  EOCM2B_IMX6_HS,EOCM2A_IMX6_HS,HCP_T_HS,ICCM_HS,EOCM2B_K1_HS,EOCM2A_K1_HS,CGM_HS,ECM_HS,ACC_HS,EPB_HS,EBCM_OBD_HS,EBCM_HS

BO_ 1322 Tire_Pressure_Sensors_HS: 6 BCM_HS
 SG_ TireRRPrsV : 9|1@0+ (1,0) [0|1] ""  CGM_HS,LVMPC_HS,EDI_HS,ICCM_B_HS,ICCM_OBD_HS,ICCM_HS,RDCM_HS,EBCM_OBD_HS,EBCM_HS
 SG_ TireRRPrsStat : 15|3@0+ (1,0) [0|7] ""  CGM_HS,LVMPC_HS,EDI_HS,ICCM_B_HS,ICCM_OBD_HS,ICCM_HS,RDCM_HS,EBCM_OBD_HS,EBCM_HS
 SG_ TireRRPrs : 47|8@0+ (4,0) [0|1020] "kPaG"  CGM_HS,LVMPC_HS,EDI_HS,ICCM_B_HS,ICCM_OBD_HS,ICCM_HS,RDCM_HS,EBCM_OBD_HS,EBCM_HS
 SG_ TireRFPrsV : 1|1@0+ (1,0) [0|1] ""  CGM_HS,LVMPC_HS,EDI_HS,ICCM_B_HS,ICCM_OBD_HS,ICCM_HS,RDCM_HS,EBCM_OBD_HS,EBCM_HS
 SG_ TireRFPrsStat : 7|3@0+ (1,0) [0|7] ""  CGM_HS,LVMPC_HS,EDI_HS,ICCM_B_HS,ICCM_OBD_HS,ICCM_HS,RDCM_HS,EBCM_OBD_HS,EBCM_HS
 SG_ TireRFPrs : 39|8@0+ (4,0) [0|1020] "kPaG"  CGM_HS,LVMPC_HS,EDI_HS,ICCM_B_HS,ICCM_OBD_HS,ICCM_HS,RDCM_HS,EBCM_OBD_HS,EBCM_HS
 SG_ TireLRPrsV : 8|1@0+ (1,0) [0|1] ""  CGM_HS,LVMPC_HS,EDI_HS,ICCM_B_HS,ICCM_OBD_HS,ICCM_HS,RDCM_HS,EBCM_OBD_HS,EBCM_HS
 SG_ TireLRPrsStat : 12|3@0+ (1,0) [0|7] ""  CGM_HS,LVMPC_HS,EDI_HS,ICCM_B_HS,ICCM_OBD_HS,ICCM_HS,RDCM_HS,EBCM_OBD_HS,EBCM_HS
 SG_ TireLRPrs : 31|8@0+ (4,0) [0|1020] "kPaG"  CGM_HS,LVMPC_HS,EDI_HS,ICCM_B_HS,ICCM_OBD_HS,ICCM_HS,RDCM_HS,EBCM_OBD_HS,EBCM_HS
 SG_ TireLFPrsV : 0|1@0+ (1,0) [0|1] ""  CGM_HS,LVMPC_HS,EDI_HS,ICCM_B_HS,ICCM_OBD_HS,ICCM_HS,RDCM_HS,EBCM_OBD_HS,EBCM_HS
 SG_ TireLFPrsStat : 4|3@0+ (1,0) [0|7] ""  CGM_HS,LVMPC_HS,EDI_HS,ICCM_B_HS,ICCM_OBD_HS,ICCM_HS,RDCM_HS,EBCM_OBD_HS,EBCM_HS
 SG_ TireLFPrs : 23|8@0+ (4,0) [0|1020] "kPaG"  CGM_HS,LVMPC_HS,EDI_HS,ICCM_B_HS,ICCM_OBD_HS,ICCM_HS,RDCM_HS,EBCM_OBD_HS,EBCM_HS

BO_ 1601 USDT_Resp_From_BCM_HS: 8 BCM_HS
 SG_ DgnInf : 7|64@0+ (1,0) [0|1.8446744074e+19] ""  HMIM_HS,CSM_HS,CGM_HS,TCP_HS,ONSTAR_HS,TestTool_HS

BO_ 2018 USDT_Req_to_TCM_MTA_MTIO_HS: 8 TestTool_HS
 SG_ DgnInf : 7|64@0+ (1,0) [0|1.8446744074e+19] ""  TCP_HS,ONSTAR_HS,CGM_HS,HMIM_HS,TCM_HS

BO_ 2026 USDT_Resp_From_TCM_MTA_MTIO_HS: 8 TCM_HS
 SG_ DgnInf : 7|64@0+ (1,0) [0|1.8446744074e+19] ""  HMIM_HS,CSM_HS,CGM_HS,TCP_HS,ONSTAR_HS,TestTool_HS

BO_ 1514 UUDT_Resp_From_TCM_MTA_MTIO_HS: 8 TCM_HS
 SG_ DgnInf : 7|64@0+ (1,0) [0|1.8446744074e+19] ""  HMIM_HS,CSM_HS,CGM_HS,TCP_HS,ONSTAR_HS,TestTool_HS

BO_ 1300 VIN_Digits_2_to_9_HS: 8 BCM_HS
 SG_ VehIdNmDig2_9 : 7|64@0+ (1,0) [0|1] ""  EOCM2B_IMX6_HS,EOCM2A_IMX6_HS,V2V_HS,CGM_HS,EBCM_OBD_HS,EBCM_HS,VES_HS,EPS_HS,VLBS_HS,ACC_HS,TCCM_HS,EPB_HS,RDCM_HS

BO_ 288 Vehicle_Odometer_HS: 5 BCM_HS
 SG_ VehOdo : 7|32@0+ (0.015625,0) [0|67108863.984] "km"  EOCM2B_IMX6_HS,EOCM2A_IMX6_HS,V2V_HS,EBOOST_OBD_HS,EBCM_OBD_HS,EBCM_HS,CGM_HS,EPB_HS,LVMPC_HS,TCCM_HS,RDCM_HS,ACC_HS
 SG_ VehOdoV : 32|1@0+ (1,0) [0|1] ""  EOCM2B_IMX6_HS,EOCM2A_IMX6_HS,V2V_HS,EBOOST_OBD_HS,EBCM_OBD_HS,EBCM_HS,CGM_HS,EPB_HS,LVMPC_HS,TCCM_HS,RDCM_HS,ACC_HS

BO_ 2020 USDT_Req_to_VICM_HS: 8 TestTool_HS
 SG_ DgnInf : 7|64@0+ (1,0) [0|1.8446744074e+19] ""  TCP_HS,ONSTAR_HS,CGM_HS,HMIM_HS,BSM_HS,VICM_HS

BO_ 2028 USDT_Resp_From_VICM_HS: 8 VICM_HS
 SG_ DgnInf : 7|64@0+ (1,0) [0|1.8446744074e+19] ""  HMIM_HS,CSM_HS,CGM_HS,TCP_HS,ONSTAR_HS,TestTool_HS

BO_ 1516 UUDT_Resp_From_VICM_HS: 8 VICM_HS
 SG_ DgnInf : 7|64@0+ (1,0) [0|1.8446744074e+19] ""  HMIM_HS,CSM_HS,CGM_HS,TCP_HS,ONSTAR_HS,TestTool_HS

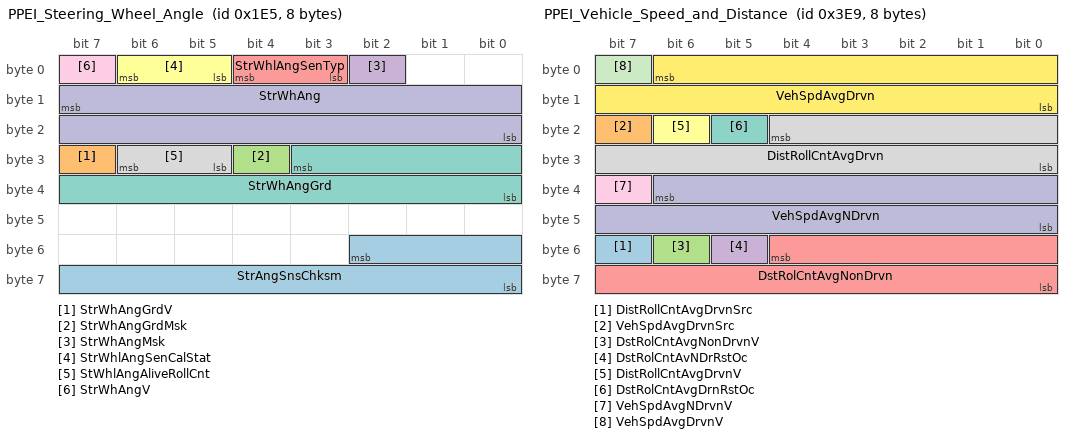
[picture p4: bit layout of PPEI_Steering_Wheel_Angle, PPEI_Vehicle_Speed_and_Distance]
BO_ 485 PPEI_Steering_Wheel_Angle: 8 EBCM_HS
 SG_ StrAngSnsChksm : 50|11@0+ (1,0) [0|2047] ""  EOCM2B_K2_HS,EOCM2A_K2_HS,TCCM_HS,ICCM_HS,V2V_HS,VPM_HS,CSM_HS,ECM_HS,EOCM2B_K1_HS,EOCM2A_K1_HS,CGM_HS,FCM_HS,HMIM_HS,VES_HS,EPS_HS,EBCM_OBD_HS,EBCM_HS,EPB_HS
 SG_ StrWhAngGrdV : 31|1@0+ (1,0) [0|1] ""  EOCM2B_K2_HS,EOCM2A_K2_HS,VPM_HS,CSM_HS,EOCM2B_K1_HS,EOCM2A_K1_HS,V2V_HS,CGM_HS,FCM_HS,HMIM_HS,ACC_HS,TCP_HS,ONSTAR_HS,ICCM_B_HS,ICCM_OBD_HS,ICCM_HS,ALC_HS,SADS_HS,ECM_HS,VES_HS,EPS_HS,EPB_HS,RDCM_HS,TCCM_HS,EBCM_OBD_HS,EBCM_HS
 SG_ StrWhAngGrdMsk : 28|1@0+ (1,0) [0|1] ""  EOCM2B_K2_HS,EOCM2A_K2_HS,TCCM_HS,ICCM_HS,V2V_HS,VPM_HS,CSM_HS,EOCM2B_K1_HS,EOCM2A_K1_HS,CGM_HS,FCM_HS,VES_HS,EPS_HS,HMIM_HS,EPB_HS,EBCM_OBD_HS,EBCM_HS
 SG_ StrWhAngMsk : 2|1@0+ (1,0) [0|1] ""  EOCM2B_K2_HS,EOCM2A_K2_HS,TCCM_HS,V2V_HS,VPM_HS,ECM_HS,CSM_HS,EOCM2B_K1_HS,EOCM2A_K1_HS,CGM_HS,LVMPC_HS,EDI_HS,FCM_HS,HMIM_HS,ICCM_B_HS,ICCM_OBD_HS,ICCM_HS,ALC_HS,SADS_HS,VES_HS,EPS_HS,EPB_HS,RDCM_HS,EBCM_OBD_HS,EBCM_HS
 SG_ StrWhlAngSenTyp : 4|2@0+ (1,0) [0|3] ""  EOCM2B_K2_HS,EOCM2A_K2_HS,TCCM_HS,ICCM_HS,V2V_HS,VPM_HS,CSM_HS,EOCM2B_K1_HS,EOCM2A_K1_HS,CGM_HS,EBCM_OBD_HS,EBCM_HS,VES_HS,EPS_HS,HMIM_HS,FCM_HS,EPB_HS
 SG_ StrWhlAngSenCalStat : 6|2@0+ (1,0) [0|3] ""  EOCM2B_K2_HS,EOCM2A_K2_HS,V2V_HS,VPM_HS,CSM_HS,EOCM2B_K1_HS,EOCM2A_K1_HS,CGM_HS,ECM_HS,EBCM_OBD_HS,EBCM_HS,HMIM_HS,FCM_HS,ICCM_B_HS,ICCM_OBD_HS,ICCM_HS,ALC_HS,SADS_HS,VES_HS,EPS_HS,AHL_AFL_HS,EPB_HS,RDCM_HS,ACC_HS,BCM_HS,TCCM_HS
 SG_ StrWhAngGrd : 27|12@0- (1,0) [-2048|2047] "deg/sec"  EOCM2B_K2_HS,EOCM2A_K2_HS,VPM_HS,CSM_HS,EOCM2B_K1_HS,EOCM2A_K1_HS,V2V_HS,CGM_HS,FCM_HS,EBCM_OBD_HS,EBCM_HS,HMIM_HS,ACC_HS,ECM_HS,TCCM_HS,RDCM_HS,ICCM_B_HS,ICCM_OBD_HS,ICCM_HS,ALC_HS,SADS_HS,VES_HS,EPS_HS,EPB_HS,TCP_HS,ONSTAR_HS
 SG_ StWhlAngAliveRollCnt : 30|2@0+ (1,0) [0|3] ""  EOCM2B_K2_HS,EOCM2A_K2_HS,TCCM_HS,V2V_HS,VPM_HS,ECM_HS,CSM_HS,EOCM2B_K1_HS,EOCM2A_K1_HS,CGM_HS,HMIM_HS,EBCM_OBD_HS,EBCM_HS,ICCM_B_HS,ICCM_OBD_HS,ICCM_HS,ALC_HS,SADS_HS,VES_HS,EPS_HS,FCM_HS,RDCM_HS,EPB_HS
 SG_ StrWhAngV : 7|1@0+ (1,0) [0|1] ""  EOCM2B_K2_HS,EOCM2A_K2_HS,VPM_HS,CSM_HS,EOCM2B_K1_HS,EOCM2A_K1_HS,V2V_HS,CGM_HS,ECM_HS,LVMPC_HS,EDI_HS,HMIM_HS,FCM_HS,EBCM_OBD_HS,EBCM_HS,ICCM_B_HS,ICCM_OBD_HS,ICCM_HS,ALC_HS,SADS_HS,VES_HS,EPS_HS,RDCM_HS,TCP_HS,ONSTAR_HS,ACC_HS,BCM_HS,AHL_AFL_HS,EPB_HS,TCCM_HS
 SG_ StrWhAng : 15|16@0- (0.0625,0) [-2048|2047.9375] "deg"  EOCM2B_K2_HS,EOCM2A_K2_HS,VPM_HS,CSM_HS,EOCM2B_K1_HS,EOCM2A_K1_HS,V2V_HS,CGM_HS,ECM_HS,LVMPC_HS,EDI_HS,HMIM_HS,FCM_HS,EBCM_OBD_HS,EBCM_HS,ICCM_B_HS,ICCM_OBD_HS,ICCM_HS,ALC_HS,SADS_HS,VES_HS,EPS_HS,RDCM_HS,EPB_HS,TCP_HS,ONSTAR_HS,ACC_HS,AHL_AFL_HS,BCM_HS,TCCM_HS

BO_ 1001 PPEI_Vehicle_Speed_and_Distance: 8 ECM_HS
 SG_ DistRollCntAvgDrvnSrc : 55|1@0+ (1,0) [0|1] ""  CSM_HS,HCP_B_HS,CGM_HS,HCP_T_HS,HCP_HS,BCP_HS,HMIM_HS,EBCM_OBD_HS,EBCM_HS,VES_HS,EPS_HS,BSM_HS,VICM_HS,TCM_HS,TCCM_HS,FICM_HS,BCM_HS
 SG_ VehSpdAvgDrvnSrc : 23|1@0+ (1,0) [0|1] ""  CSM_HS,HCP_B_HS,CGM_HS,PTO_HS,FICM_HS,EBCM_OBD_HS,EBCM_HS,HMIM_HS,TCM_HS,VES_HS,EPS_HS,TCCM_HS,EPB_HS,BCM_HS
 SG_ DstRolCntAvgNonDrvnV : 54|1@0+ (1,0) [0|1] ""  CSM_HS,HCP_B_HS,CGM_HS,BSM_HS,VICM_HS,HMIM_HS,EBCM_OBD_HS,EBCM_HS,VES_HS,EPS_HS,TCCM_HS,BCM_HS
 SG_ DstRolCntAvNDrRstOc : 53|1@0+ (1,0) [0|1] ""  CSM_HS,HCP_B_HS,CGM_HS,BSM_HS,VICM_HS,HMIM_HS,EBCM_OBD_HS,EBCM_HS,VES_HS,EPS_HS,TCCM_HS,BCM_HS
 SG_ DstRolCntAvgNonDrvn : 52|13@0+ (0.125,0) [0|1023.875] "m"  CSM_HS,HCP_B_HS,CGM_HS,BSM_HS,VICM_HS,HMIM_HS,EBCM_OBD_HS,EBCM_HS,VES_HS,EPS_HS,TCCM_HS,BCM_HS
 SG_ DistRollCntAvgDrvnV : 22|1@0+ (1,0) [0|1] ""  CSM_HS,HCP_B_HS,CGM_HS,HCP_T_HS,HCP_HS,BCP_HS,HMIM_HS,EBCM_OBD_HS,EBCM_HS,VES_HS,EPS_HS,BSM_HS,VICM_HS,TCM_HS,TCCM_HS,FICM_HS,ICCM_B_HS,ICCM_OBD_HS,ICCM_HS,BCM_HS
 SG_ DstRolCntAvgDrnRstOc : 21|1@0+ (1,0) [0|1] ""  CSM_HS,HCP_B_HS,CGM_HS,HCP_T_HS,HCP_HS,BCP_HS,HMIM_HS,EBCM_OBD_HS,EBCM_HS,VES_HS,EPS_HS,BSM_HS,VICM_HS,TCM_HS,TCCM_HS,FICM_HS,ICCM_B_HS,ICCM_OBD_HS,ICCM_HS,BCM_HS
 SG_ DistRollCntAvgDrvn : 20|13@0+ (0.125,0) [0|1023.875] "m"  CSM_HS,HCP_B_HS,CGM_HS,HCP_T_HS,HCP_HS,BCP_HS,HMIM_HS,EBCM_OBD_HS,EBCM_HS,VES_HS,EPS_HS,BSM_HS,VICM_HS,TCM_HS,TCCM_HS,FICM_HS,ICCM_B_HS,ICCM_OBD_HS,ICCM_HS,BCM_HS
 SG_ VehSpdAvgNDrvnV : 39|1@0+ (1,0) [0|1] ""  TTPM_HS,CSM_HS,HCP_B_HS,CGM_HS,VLBS_HS,HMIM_HS,TCP_HS,ONSTAR_HS,VES_HS,EPS_HS,BSM_HS,VICM_HS,ICCM_B_HS,ICCM_OBD_HS,ICCM_HS,EBCM_OBD_HS,EBCM_HS,APPS_HS,TCCM_HS,BCP_HS,EPB_HS,AHL_AFL_HS,BCM_HS,ACC_HS,PTO_HS
 SG_ VehSpdAvgNDrvn : 38|15@0+ (0.015625,0) [0|511.984375] "km / h"  TTPM_HS,CSM_HS,HCP_B_HS,CGM_HS,VLBS_HS,HMIM_HS,TCP_HS,ONSTAR_HS,VES_HS,EPS_HS,BSM_HS,VICM_HS,ICCM_B_HS,ICCM_OBD_HS,ICCM_HS,EBCM_OBD_HS,EBCM_HS,APPS_HS,BCP_HS,TCCM_HS,EPB_HS,AHL_AFL_HS,BCM_HS,ACC_HS,PTO_HS
 SG_ VehSpdAvgDrvnV : 7|1@0+ (1,0) [0|1] ""  EOCM2B_IMX6_HS,EOCM2A_IMX6_HS,EOCM2B_K2_HS,EOCM2A_K2_HS,EOCM2B_K1_HS,EOCM2A_K1_HS,CSM_HS,HCP_B_HS,CGM_HS,PFAF_HS,LVMPC_HS,EDI_HS,VLBS_HS,FICM_HS,EBCM_OBD_HS,EBCM_HS,HMIM_HS,TCM_HS,BCP_HS,TCP_HS,ONSTAR_HS,VES_HS,EPS_HS,BSM_HS,VICM_HS,APPS_HS,TCCM_HS,EPB_HS,ICCM_B_HS,ICCM_OBD_HS,ICCM_HS,ALC_HS,SADS_HS,ACC_HS,BCM_HS,PTO_HS
 SG_ VehSpdAvgDrvn : 6|15@0+ (0.015625,0) [0|511.984375] "km / h"  EOCM2B_IMX6_HS,EOCM2A_IMX6_HS,EOCM2B_K2_HS,EOCM2A_K2_HS,EOCM2B_K1_HS,EOCM2A_K1_HS,CSM_HS,HCP_B_HS,ESCM_SP_HS,CGM_HS,PFAF_HS,LVMPC_HS,EDI_HS,VLBS_HS,FICM_HS,EBCM_OBD_HS,EBCM_HS,HMIM_HS,TCM_HS,BCP_HS,TCP_HS,ONSTAR_HS,VES_HS,EPS_HS,BSM_HS,VICM_HS,APPS_HS,TCCM_HS,EPB_HS,ICCM_B_HS,ICCM_OBD_HS,ICCM_HS,ALC_HS,SADS_HS,ACC_HS,BCM_HS,PTO_HS

BO_ 961 PPEI_Powertrain_Immobilizer_Data: 8 ECM_HS
 SG_ PTImmblzerInfo : 7|64@0+ (1,0) [0|1.8446744074e+19] ""  V2V_HS,CGM_HS,ECM_HS,VLBS_HS,TCP_HS,ONSTAR_HS,BCM_HS

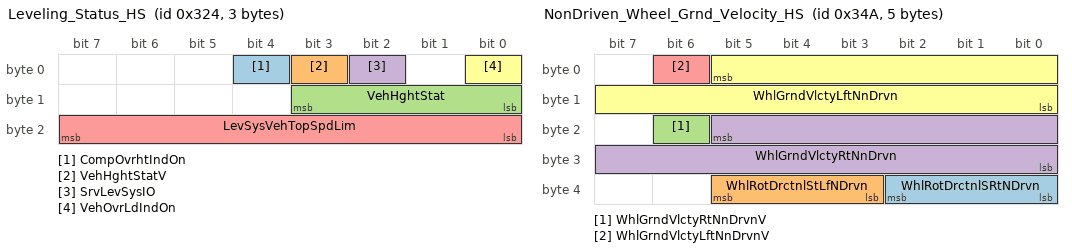
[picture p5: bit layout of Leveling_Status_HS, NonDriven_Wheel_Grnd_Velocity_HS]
BO_ 804 Leveling_Status_HS: 3 SADS_HS
 SG_ CompOvrhtIndOn : 4|1@0+ (1,0) [0|1] ""  CGM_HS,BCM_HS
 SG_ VehHghtStatV : 3|1@0+ (1,0) [0|1] ""  CGM_HS,BCM_HS,EBCM_OBD_HS,EBCM_HS
 SG_ VehHghtStat : 11|4@0+ (1,0) [0|15] ""  CGM_HS,BCM_HS,EBCM_OBD_HS,EBCM_HS
 SG_ SrvLevSysIO : 2|1@0+ (1,0) [0|1] ""  CGM_HS,BCM_HS,TCP_HS,ONSTAR_HS
 SG_ LevSysVehTopSpdLim : 23|8@0+ (2,0) [0|510] "km/h"  CGM_HS,BCM_HS
 SG_ VehOvrLdIndOn : 0|1@0+ (1,0) [0|1] ""  CGM_HS,TCP_HS,ONSTAR_HS,BCM_HS

BO_ 842 NonDriven_Wheel_Grnd_Velocity_HS: 5 EBCM_HS
 SG_ WhlRotDrctnlSRtNDrvn : 34|3@0+ (1,0) [0|7] ""  LVMPC_HS,V2V_HS,CSM_HS,EOCM2B_K1_HS,CGM_HS,EOCM2A_K1_HS,EDI_HS,EOCM_F_HS,HMIM_HS,EPS_HS
 SG_ WhlRotDrctnlStLfNDrvn : 37|3@0+ (1,0) [0|7] ""  LVMPC_HS,V2V_HS,CSM_HS,EOCM2B_K1_HS,CGM_HS,EOCM2A_K1_HS,EDI_HS,EOCM_F_HS,HMIM_HS,EPS_HS
 SG_ WhlGrndVlctyRtNnDrvnV : 22|1@0+ (1,0) [0|1] ""  LVMPC_HS,V2V_HS,CSM_HS,EOCM2B_K1_HS,CGM_HS,EOCM2A_K1_HS,EDI_HS,HMIM_HS,TCCM_HS,FCM_HS,APPS_HS,EOCM_F_HS,EPB_HS,RDCM_HS,ACC_HS,BCM_HS,VES_HS,EPS_HS,SADS_HS
 SG_ WhlGrndVlctyRtNnDrvn : 21|14@0+ (0.03125,0) [0|511.96875] "km / h"  LVMPC_HS,V2V_HS,CSM_HS,EOCM2B_K1_HS,CGM_HS,EOCM2A_K1_HS,EDI_HS,HMIM_HS,TCCM_HS,FCM_HS,APPS_HS,EOCM_F_HS,RDCM_HS,ACC_HS,BCM_HS,EPB_HS,VES_HS,EPS_HS,SADS_HS
 SG_ WhlGrndVlctyLftNnDrvnV : 6|1@0+ (1,0) [0|1] ""  LVMPC_HS,V2V_HS,CSM_HS,EOCM2B_K1_HS,CGM_HS,EOCM2A_K1_HS,EDI_HS,HMIM_HS,TCCM_HS,FCM_HS,APPS_HS,EOCM_F_HS,EPB_HS,BCM_HS,RDCM_HS,ACC_HS,VES_HS,EPS_HS,SADS_HS
 SG_ WhlGrndVlctyLftNnDrvn : 5|14@0+ (0.03125,0) [0|511.96875] "km / h"  LVMPC_HS,V2V_HS,CSM_HS,EOCM2B_K1_HS,CGM_HS,EOCM2A_K1_HS,EDI_HS,HMIM_HS,TCCM_HS,FCM_HS,APPS_HS,EOCM_F_HS,BCM_HS,RDCM_HS,ACC_HS,EPB_HS,VES_HS,EPS_HS,SADS_HS

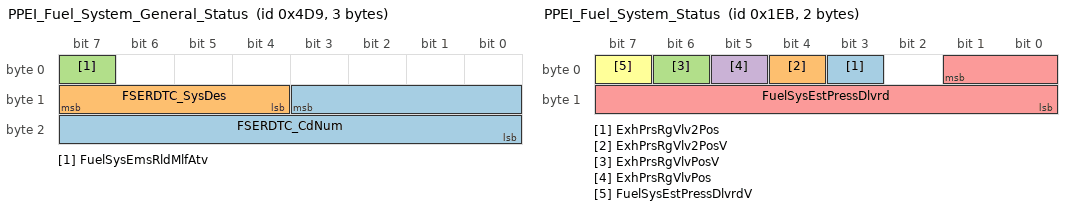
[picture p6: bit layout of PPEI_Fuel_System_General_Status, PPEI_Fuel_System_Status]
BO_ 1241 PPEI_Fuel_System_General_Status: 3 FICM_HS
 SG_ FSERDTC_CdNum : 11|12@0+ (1,0) [0|4095] ""  CGM_HS,ECM_HS
 SG_ FSERDTC_SysDes : 15|4@0+ (1,0) [0|15] ""  CGM_HS,ECM_HS
 SG_ FuelSysEmsRldMlfAtv : 7|1@0+ (1,0) [0|1] ""  CGM_HS,ECM_HS

BO_ 491 PPEI_Fuel_System_Status: 2 ICCM_HS
 SG_ ExhPrsRgVlv2Pos : 3|1@0+ (1,0) [0|1] ""  CGM_HS,ECM_HS
 SG_ ExhPrsRgVlv2PosV : 4|1@0+ (1,0) [0|1] ""  CGM_HS,ECM_HS
 SG_ ExhPrsRgVlvPosV : 6|1@0+ (1,0) [0|1] ""  CGM_HS,ECM_HS
 SG_ ExhPrsRgVlvPos : 5|1@0+ (1,0) [0|1] ""  CGM_HS,ECM_HS
 SG_ FuelSysEstPressDlvrd : 1|10@0+ (1,0) [0|1023] "kPa"  CGM_HS,VCM_HS,ECM_HS
 SG_ FuelSysEstPressDlvrdV : 7|1@0+ (1,0) [0|1] ""  CGM_HS,VCM_HS,ECM_HS

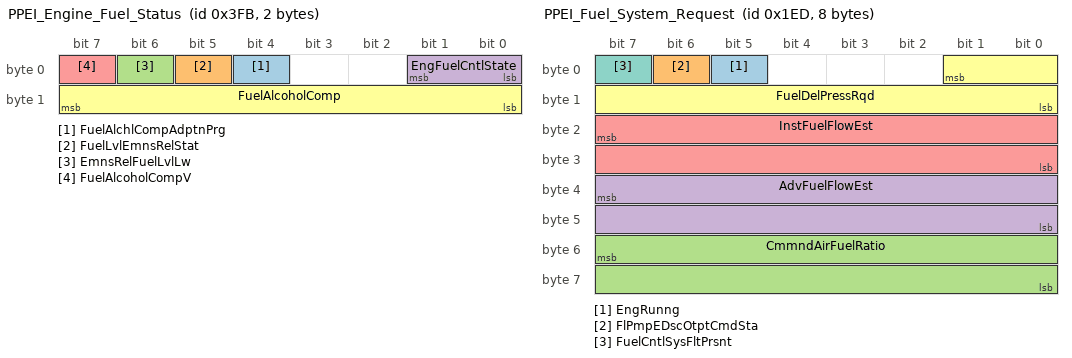
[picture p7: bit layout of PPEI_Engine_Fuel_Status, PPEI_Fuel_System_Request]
BO_ 1019 PPEI_Engine_Fuel_Status: 2 ECM_HS
 SG_ FuelAlchlCompAdptnPrg : 4|1@0+ (1,0) [0|1] ""  CGM_HS,BCM_HS
 SG_ FuelLvlEmnsRelStat : 5|1@0+ (1,0) [0|1] ""  HCP_B_HS,CGM_HS,HCP_T_HS,FICM_HS,HCP_HS,BCP_HS
 SG_ EmnsRelFuelLvlLw : 6|1@0+ (1,0) [0|1] ""  HCP_B_HS,CGM_HS,HCP_T_HS,HCP_HS,FICM_HS,BCP_HS,ICCM_B_HS,ICCM_OBD_HS,ICCM_HS
 SG_ EngFuelCntlState : 1|2@0+ (1,0) [0|3] ""  CGM_HS,FICM_HS,ICCM_B_HS,ICCM_OBD_HS,ICCM_HS
 SG_ FuelAlcoholCompV : 7|1@0+ (1,0) [0|1] ""  CGM_HS,FICM_HS,BSM_HS,VICM_HS,TCP_HS,ONSTAR_HS,BCM_HS,ICCM_B_HS,ICCM_OBD_HS,ICCM_HS
 SG_ FuelAlcoholComp : 15|8@0+ (0.392157,0) [0|100.000035] "%"  CGM_HS,FICM_HS,BSM_HS,VICM_HS,TCP_HS,ONSTAR_HS,BCM_HS,ICCM_B_HS,ICCM_OBD_HS,ICCM_HS

BO_ 493 PPEI_Fuel_System_Request: 8 ECM_HS
 SG_ EngRunng : 5|1@0+ (1,0) [0|1] ""  V2V_HS,CGM_HS,PTO_HS,ICCM_B_HS,ICCM_OBD_HS,ICCM_HS
 SG_ FlPmpEDscOtptCmdSta : 6|1@0+ (1,0) [0|1] ""  CGM_HS,FICM_HS,ICCM_B_HS,ICCM_OBD_HS,ICCM_HS
 SG_ CmmndAirFuelRatio : 55|16@0+ (0.000488281,0) [0|31.999495335] ""  CGM_HS,FICM_HS,ICCM_B_HS,ICCM_OBD_HS,ICCM_HS
 SG_ AdvFuelFlowEst : 39|16@0+ (0.000976562,0) [0|63.99899067] "grams/s"  CGM_HS,FICM_HS,ICCM_B_HS,ICCM_OBD_HS,ICCM_HS
 SG_ InstFuelFlowEst : 23|16@0+ (0.000976562,0) [0|63.99899067] "grams/s"  CGM_HS,BSM_HS,VICM_HS,FICM_HS,ICCM_B_HS,ICCM_OBD_HS,ICCM_HS
 SG_ FuelDelPressRqd : 1|10@0+ (1,0) [0|1023] "kPa"  FICM_HS,CGM_HS,ICCM_B_HS,ICCM_OBD_HS,ICCM_HS
 SG_ FuelCntlSysFltPrsnt : 7|1@0+ (1,0) [0|1] ""  CGM_HS,FICM_HS,ICCM_B_HS,ICCM_OBD_HS,ICCM_HS

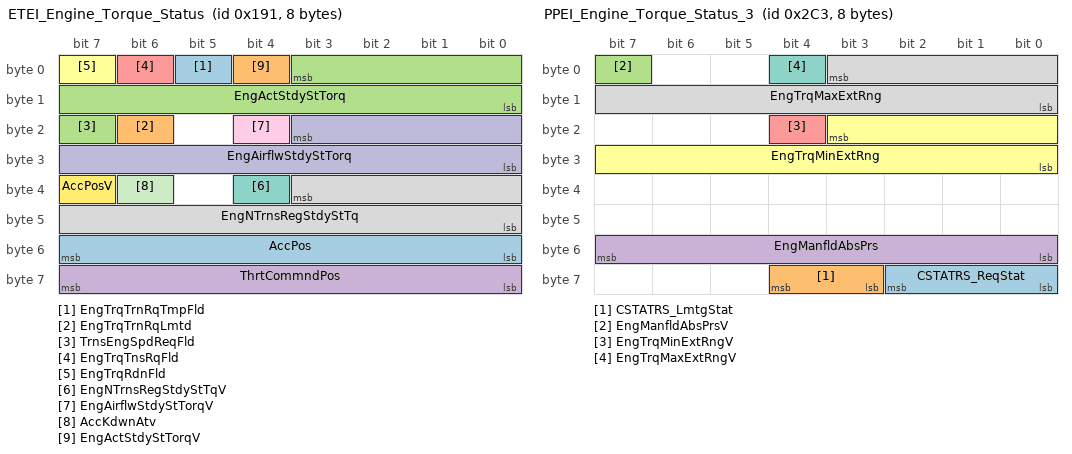
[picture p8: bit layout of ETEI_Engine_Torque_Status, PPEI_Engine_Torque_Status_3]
BO_ 401 ETEI_Engine_Torque_Status: 8 ECM_HS
 SG_ EngTrqTrnRqTmpFld : 5|1@0+ (1,0) [0|1] ""  CGM_HS,TCCM_HS,TCM_HS
 SG_ EngTrqTrnRqLmtd : 22|1@0+ (1,0) [0|1] ""  CGM_HS,TCCM_HS,TCM_HS
 SG_ TrnsEngSpdReqFld : 23|1@0+ (1,0) [0|1] ""  CGM_HS,TCCM_HS,TCM_HS
 SG_ ThrtCommndPos : 63|8@0+ (0.392157,0) [0|100.000035] "%"  CGM_HS,TCCM_HS
 SG_ EngTrqTnsRqFld : 6|1@0+ (1,0) [0|1] ""  CGM_HS,TCCM_HS,TCM_HS
 SG_ EngTrqRdnFld : 7|1@0+ (1,0) [0|1] ""  CGM_HS,TCCM_HS,TCM_HS
 SG_ EngNTrnsRegStdyStTqV : 36|1@0+ (1,0) [0|1] ""  CGM_HS,TCCM_HS,TCM_HS
 SG_ EngNTrnsRegStdyStTq : 35|12@0+ (0.5,-848) [-848|1199.5] "Nm"  CGM_HS,TCCM_HS,TCM_HS
 SG_ EngAirflwStdyStTorqV : 20|1@0+ (1,0) [0|1] ""  CGM_HS,TCCM_HS,TCM_HS
 SG_ EngAirflwStdyStTorq : 19|12@0+ (0.5,-848) [-848|1199.5] "Nm"  CGM_HS,TCCM_HS,TCM_HS
 SG_ AccKdwnAtv : 38|1@0+ (1,0) [0|1] ""  CGM_HS,TCCM_HS,TCM_HS
 SG_ AccPosV : 39|1@0+ (1,0) [0|1] ""  CGM_HS,BCP_HS,FICM_HS,TCM_HS
 SG_ AccPos : 55|8@0+ (0.392157,0) [0|100.000035] "%"  BCP_HS,FICM_HS,TCM_HS
 SG_ EngActStdyStTorqV : 4|1@0+ (1,0) [0|1] ""  CGM_HS,TCCM_HS,TCM_HS
 SG_ EngActStdyStTorq : 3|12@0+ (0.5,-848) [-848|1199.5] "Nm"  CGM_HS,TCCM_HS,TCM_HS

BO_ 707 PPEI_Engine_Torque_Status_3: 8 ECM_HS
 SG_ CSTATRS_ReqStat : 58|3@0+ (1,0) [0|7] ""  CGM_HS,EBCM_OBD_HS,EBCM_HS
 SG_ CSTATRS_LmtgStat : 60|2@0+ (1,0) [0|3] ""  CGM_HS,EBCM_OBD_HS,EBCM_HS
 SG_ EngManfldAbsPrsV : 7|1@0+ (1,0) [0|1] ""  CGM_HS,EDI_HS,FICM_HS,BCP_HS,EBCM_OBD_HS,EBCM_HS
 SG_ EngManfldAbsPrs : 55|8@0+ (0.5,0) [0|127.5] "kPa"  CGM_HS,EDI_HS,FICM_HS,BCP_HS,EBCM_OBD_HS,EBCM_HS
 SG_ EngTrqMinExtRngV : 20|1@0+ (1,0) [0|1] ""  CGM_HS,ACC_HS,EBCM_OBD_HS,EBCM_HS
 SG_ EngTrqMinExtRng : 19|12@0+ (0.5,-848) [-848|1199.5] "Nm"  CGM_HS,ACC_HS,EBCM_OBD_HS,EBCM_HS
 SG_ EngTrqMaxExtRngV : 4|1@0+ (1,0) [0|1] ""  CGM_HS,TCCM_HS,ACC_HS,EBCM_OBD_HS,EBCM_HS,RDCM_HS
 SG_ EngTrqMaxExtRng : 3|12@0+ (0.5,-848) [-848|1199.5] "Nm"  CGM_HS,TCCM_HS,ACC_HS,RDCM_HS,EBCM_OBD_HS,EBCM_HS

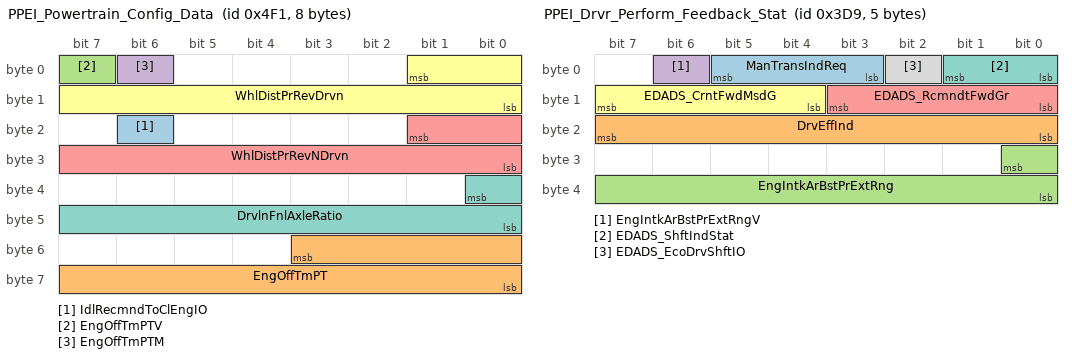
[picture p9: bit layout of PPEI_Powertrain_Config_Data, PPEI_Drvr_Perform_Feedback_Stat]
BO_ 1265 PPEI_Powertrain_Config_Data: 8 ECM_HS
 SG_ IdlRecmndToClEngIO : 22|1@0+ (1,0) [0|1] ""  CGM_HS,BCM_HS
 SG_ EngOffTmPT : 51|12@0+ (0.5,0) [0|2047.5] "min"  EOCM2B_K2_HS,EOCM2A_K2_HS,EOCM2B_K1_HS,EOCM2A_K1_HS,CGM_HS,EBCM_OBD_HS,EBCM_HS,HCP_T_HS,MCP_HS,HCP_B_HS,TCM_HS
 SG_ EngOffTmPTV : 7|1@0+ (1,0) [0|1] ""  EOCM2B_K2_HS,EOCM2A_K2_HS,EOCM2B_K1_HS,EOCM2A_K1_HS,CGM_HS,EBCM_OBD_HS,EBCM_HS,HCP_T_HS,MCP_HS,HCP_B_HS,TCM_HS
 SG_ EngOffTmPTM : 6|1@0+ (1,0) [0|1] ""  EOCM2B_K2_HS,EOCM2A_K2_HS,EOCM2B_K1_HS,EOCM2A_K1_HS,CGM_HS,EBCM_OBD_HS,EBCM_HS,HCP_T_HS,MCP_HS,HCP_B_HS,TCM_HS
 SG_ WhlDistPrRevNDrvn : 17|10@0+ (3,800) [800|3869] "mm"  EOCM2B_K2_HS,EOCM2A_K2_HS,V2V_HS,CSM_HS,FCM_HS,EOCM2B_K1_HS,EOCM2A_K1_HS,CGM_HS,HCP_T_HS,ICCM_B_HS,ICCM_OBD_HS,ICCM_HS,HMIM_HS,VES_HS,EPS_HS,TCCM_HS,EPB_HS,EOCM_F_HS,TCM_HS,EBCM_OBD_HS,EBCM_HS,RDCM_HS
 SG_ WhlDistPrRevDrvn : 1|10@0+ (3,800) [800|3869] "mm"  EOCM2B_K2_HS,EOCM2A_K2_HS,V2V_HS,CSM_HS,FCM_HS,TRCM_HS,EOCM2B_K1_HS,EOCM2A_K1_HS,CGM_HS,HCP_T_HS,ICCM_B_HS,ICCM_OBD_HS,ICCM_HS,HMIM_HS,VES_HS,EPS_HS,EOCM_F_HS,ACC_HS,TCCM_HS,EPB_HS,TCM_HS,EBCM_OBD_HS,EBCM_HS,BCM_HS,RDCM_HS
 SG_ DrvlnFnlAxleRatio : 32|9@0+ (0.01,2) [2|7.11] ""  EOCM2B_K2_HS,EOCM2A_K2_HS,EOCM2B_K1_HS,EOCM2A_K1_HS,CGM_HS,HCP_T_HS,TCM_HS,TCCM_HS,BCM_HS,EBCM_OBD_HS,EBCM_HS

BO_ 417 ETEI_Engine_General_Status: 7 ECM_HS
 SG_ EngRunng : 30|1@0+ (1,0) [0|1] ""  TCM_HS
 SG_ EngCrsCntrlMode : 29|3@0+ (1,0) [0|7] ""  CGM_HS,TCM_HS
 SG_ EngPstOxgSnsDgAstRq : 31|1@0+ (1,0) [0|1] ""  CGM_HS,TCM_HS
 SG_ CrsCtrlCnstSpdAct : 26|1@0+ (1,0) [0|1] ""  CGM_HS,TCM_HS
 SG_ WrmUpShftPtrnRq : 25|1@0+ (1,0) [0|1] ""  CGM_HS,TCM_HS
 SG_ EngIdlSpdRdcdRng : 39|8@0+ (8,0) [0|2040] "rpm"  CGM_HS,HCP_B_HS,BCP_HS,TCM_HS
 SG_ EngAlwCltAdp : 24|1@0+ (1,0) [0|1] ""  CGM_HS,TCM_HS
 SG_ BsTrgtEngIdlSpd : 47|8@0+ (8,0) [0|2040] "rpm"  CGM_HS,TCM_HS
 SG_ AccPdlPosPcntFullRngV : 17|1@0+ (1,0) [0|1] ""  CGM_HS,TCM_HS
 SG_ AccPdlPosPcntFullRng : 55|8@0+ (0.392157,0) [0|100.000035] "%"  CGM_HS,TCM_HS
 SG_ DslPrtFltrIdlRgtnMdReq : 20|1@0+ (1,0) [0|1] ""  CGM_HS,TCM_HS
 SG_ DslPartFltrClngAlgActM : 18|1@0+ (1,0) [0|1] ""  CGM_HS,TCM_HS
 SG_ DslPartFltrClngAlgAct : 19|1@0+ (1,0) [0|1] ""  CGM_HS,TCM_HS
 SG_ EngCylDeactMd : 9|2@0+ (1,0) [0|3] ""  CGM_HS,TCM_HS,BCP_HS
 SG_ ACCmCltEngd : 13|1@0+ (1,0) [0|1] ""  CGM_HS,BCM_HS,HCP_B_HS,TCM_HS
 SG_ ParkNeutralSwStatV : 21|1@0+ (1,0) [0|1] ""  CGM_HS,ICCM_HS,TCM_HS
 SG_ ParkNeutralSwStat : 22|1@0+ (1,0) [0|1] ""  CGM_HS,ICCM_HS,TCM_HS
 SG_ EngColdHiIdleActive : 23|1@0+ (1,0) [0|1] ""  CGM_HS,TCM_HS
 SG_ EngCyDactTqSmtAct : 6|1@0+ (1,0) [0|1] ""  CGM_HS,TCM_HS
 SG_ EngBrkStat : 15|2@0+ (1,0) [0|3] ""  CGM_HS,TCM_HS
 SG_ TracCntlSysPwrtrnInhbt : 12|1@0+ (1,0) [0|1] ""  CGM_HS,TCM_HS
 SG_ EngMtlProtAtv : 11|1@0+ (1,0) [0|1] ""  CGM_HS,TCM_HS
 SG_ EngDgTrqCnvClUnlkRqd : 7|1@0+ (1,0) [0|1] ""  CGM_HS,TCM_HS
 SG_ EngCyldrDeactReqd : 10|1@0+ (1,0) [0|1] ""  CGM_HS,TCM_HS
 SG_ ETGRReqdGear : 3|4@0+ (1,0) [0|15] ""  CGM_HS,TCM_HS
 SG_ ETGRReqType : 5|2@0+ (1,0) [0|3] ""  CGM_HS,TCM_HS

BO_ 1233 PPEI_Engine_General_Status_5: 8 ECM_HS
 SG_ PTExPrtclFltWrng3IO : 63|1@0+ (1,0) [0|1] ""  PTO_HS,CGM_HS,BCM_HS
 SG_ PTExPartFltManRegStat : 62|3@0+ (1,0) [0|7] ""  CGM_HS,BCM_HS
 SG_ a_12VBatSysUnstab : 30|1@0+ (1,0) [0|1] ""  BCM_HS,CGM_HS
 SG_ EngShtdwnAct : 48|1@0+ (1,0) [0|1] ""  V2V_HS,BCM_HS,CGM_HS
 SG_ EngShtdwnPndgIO : 49|1@0+ (1,0) [0|1] ""  CGM_HS,TCP_HS,ONSTAR_HS,BCM_HS
 SG_ FuelFltChgNwIO : 51|1@0+ (1,0) [0|1] ""  CGM_HS,TCP_HS,ONSTAR_HS,BCM_HS
 SG_ PTExPrtclFltrWrn2IO : 50|1@0+ (1,0) [0|1] ""  CGM_HS,PTO_HS,TCP_HS,ONSTAR_HS,BCM_HS
 SG_ PTHiElecLdReqd : 52|1@0+ (1,0) [0|1] ""  CGM_HS,BCM_HS
 SG_ PTExPrtclFltrWrnIO : 53|1@0+ (1,0) [0|1] ""  CGM_HS,PTO_HS,TCP_HS,ONSTAR_HS,BCM_HS
 SG_ AirCndOffIO : 0|1@0+ (1,0) [0|1] ""  CGM_HS,BCM_HS
 SG_ DslGlwPlgIO : 55|1@0+ (1,0) [0|1] ""  CGM_HS,BCM_HS
 SG_ RdcdPwrIO : 31|1@0+ (1,0) [0|1] ""  CGM_HS,TCP_HS,ONSTAR_HS,BCM_HS
 SG_ FuelTotCap : 27|12@0+ (0.125,0) [0|511.875] "liters"  CGM_HS,LVMPC_HS,EDI_HS,BCM_HS
 SG_ FlLvlPctV : 28|1@0+ (1,0) [0|1] ""  CGM_HS,LVMPC_HS,AHL_AFL_HS,PTO_HS,FICM_HS,EDI_HS,BCM_HS
 SG_ FlLvlPct : 47|8@0+ (0.392157,0) [0|100.000035] "%"  CGM_HS,LVMPC_HS,PTO_HS,AHL_AFL_HS,FICM_HS,EDI_HS,BCM_HS
 SG_ EngWtrInFlIO : 54|1@0+ (1,0) [0|1] ""  CGM_HS,TCP_HS,ONSTAR_HS,BCM_HS
 SG_ EngOilTmpV : 7|1@0+ (1,0) [0|1] ""  CGM_HS,LVMPC_HS,EPS_HS,FICM_HS,EDI_HS,BCM_HS
 SG_ EngOilTmp : 15|8@0+ (1,-40) [-40|215] "deg C"  CGM_HS,LVMPC_HS,EPS_HS,FICM_HS,EDI_HS,BCM_HS
 SG_ EngOilPrsV : 6|1@0+ (1,0) [0|1] ""  CGM_HS,LVMPC_HS,PTO_HS,EDI_HS,BCM_HS
 SG_ EngOilPrsLwIO : 5|1@0+ (1,0) [0|1] ""  CGM_HS,PTO_HS,TCP_HS,ONSTAR_HS,BCM_HS
 SG_ EngOilPrs : 23|8@0+ (4,0) [0|1020] "kPa"  CGM_HS,LVMPC_HS,PTO_HS,EDI_HS,BCM_HS
 SG_ EngOilLvlLwIO : 4|1@0+ (1,0) [0|1] ""  CGM_HS,PTO_HS,TCP_HS,ONSTAR_HS,BCM_HS
 SG_ EngOilChngIO : 3|1@0+ (1,0) [0|1] ""  CGM_HS,BCM_HS
 SG_ EngHt_StpEngIO : 1|1@0+ (1,0) [0|1] ""  CGM_HS,PTO_HS,TCP_HS,ONSTAR_HS,BCM_HS
 SG_ EngHotFuelEnrchmntIO : 2|1@0+ (1,0) [0|1] ""  CGM_HS,TCP_HS,ONSTAR_HS,BCM_HS
 SG_ CkFlFilrCapIO : 29|1@0+ (1,0) [0|1] ""  CGM_HS,BCM_HS

BO_ 1217 PPEI_Engine_General_Status_4: 8 ECM_HS
 SG_ CdClrInhbt : 42|1@0+ (1,0) [0|1] ""  CGM_HS,BSM_HS,VITM_OBD_HS,EBOOST_OBD_HS,GPCM_HS,EBCM_OBD_HS,EBCM_HS,VICM_HS,ICCM_B_HS,ICCM_OBD_HS,ICCM_HS,FICM_HS,HCP_T_HS,HCP_B_HS,HCP_HS,TCM_HS
 SG_ LDMaxEngCltTmpRchd : 55|1@0+ (1,0) [0|1] ""  CGM_HS,VICM_HS,TCCM_HS,FICM_HS,HCP_B_HS,HCP_T_HS,HCP_HS,TCM_HS
 SG_ LDMinEngCltTmpRchd : 43|1@0+ (1,0) [0|1] ""  VICM_HS,ICCM_HS,TRCM_HS,CGM_HS,TCM_HS,HCP_T_HS,HCP_HS,HCP_B_HS,TCCM_HS
 SG_ LegPstDTCClrDrvCyCm : 40|1@0+ (1,0) [0|1] ""  EBOOST_OBD_HS,CGM_HS,HCP_T_HS,EBCM_OBD_HS,EBCM_HS,BSM_HS,VICM_HS,VITM_OBD_HS,BCP_HS,ICCM_B_HS,ICCM_OBD_HS,ICCM_HS,TCM_HS,FICM_HS
 SG_ EngIntAirTmpM : 44|1@0+ (1,0) [0|1] ""  TCCM_HS,BSM_HS,VICM_HS,BCP_HS,FICM_HS,HCP_T_HS,HCP_HS,HCP_B_HS,GPCM_HS,TCM_HS,CGM_HS
 SG_ LegDiagColdStCndMet : 47|1@0+ (1,0) [0|1] ""  TRCM_HS,CGM_HS,HCP_T_HS,FICM_HS,ICCM_B_HS,ICCM_OBD_HS,ICCM_HS,MCP_HS,EBCM_OBD_HS,EBCM_HS,BCP_HS,TCCM_HS,VITM_OBD_HS,BSM_HS,VICM_HS,TCM_HS
 SG_ LegDiagColdStCndFltPr : 46|1@0+ (1,0) [0|1] ""  TRCM_HS,CGM_HS,HCP_T_HS,FICM_HS,ICCM_B_HS,ICCM_OBD_HS,ICCM_HS,MCP_HS,EBCM_OBD_HS,EBCM_HS,TCCM_HS,VITM_OBD_HS,BSM_HS,VICM_HS,TCM_HS,BCP_HS
 SG_ DslExhFldRmngDstHRsV : 41|1@0+ (1,0) [0|1] ""  CGM_HS,BCM_HS,TCP_HS,ONSTAR_HS
 SG_ DslExhFldRmngDstHRs : 54|15@0+ (2,0) [0|65534] "km"  CGM_HS,BCM_HS,TCP_HS,ONSTAR_HS
 SG_ EngOilHotIO : 45|1@0+ (1,0) [0|1] ""  CGM_HS,BCM_HS
 SG_ OAT_PT_EstV : 3|1@0+ (1,0) [0|1] ""  BSM_HS,CGM_HS,HCP_T_HS,FICM_HS,TCM_HS,TCCM_HS,HCP_B_HS,AHL_AFL_HS,HCP_HS,BCP_HS,RDCM_HS,BCM_HS,EBCM_OBD_HS,EBCM_HS
 SG_ LegDiagStndCndMet : 2|1@0+ (1,0) [0|1] ""  TRCM_HS,CGM_HS,HCP_T_HS,FICM_HS,MCP_HS,EBCM_OBD_HS,EBCM_HS,VITM_OBD_HS,BSM_HS,VICM_HS,BCP_HS,TCP_HS,ONSTAR_HS,ICCM_B_HS,ICCM_OBD_HS,ICCM_HS,TCM_HS,TCCM_HS
 SG_ LegDiagStndCndFltPr : 1|1@0+ (1,0) [0|1] ""  TRCM_HS,CGM_HS,HCP_T_HS,FICM_HS,MCP_HS,EBCM_OBD_HS,EBCM_HS,VITM_OBD_HS,BSM_HS,VICM_HS,BCP_HS,ICCM_B_HS,ICCM_OBD_HS,ICCM_HS,TCM_HS,TCCM_HS
 SG_ OAT_PT_EstM : 4|1@0+ (1,0) [0|1] ""  BSM_HS,CGM_HS,FICM_HS,HCP_T_HS,HCP_HS,TCM_HS,TCCM_HS,AHL_AFL_HS,BCP_HS,RDCM_HS,BCM_HS,EBCM_OBD_HS,EBCM_HS
 SG_ OAT_PT_Est : 39|8@0+ (0.5,-40) [-40|87.5] "deg C"  BSM_HS,CGM_HS,HCP_T_HS,FICM_HS,TCM_HS,TCCM_HS,HCP_B_HS,AHL_AFL_HS,HCP_HS,BCP_HS,RDCM_HS,BCM_HS,EBCM_OBD_HS,EBCM_HS
 SG_ EngWrmUpAch : 0|1@0+ (1,0) [0|1] ""  EBOOST_OBD_HS,CGM_HS,HCP_T_HS,FICM_HS,MCP_HS,VITM_OBD_HS,EBCM_OBD_HS,EBCM_HS,BSM_HS,VICM_HS,BCP_HS,ICCM_B_HS,ICCM_OBD_HS,ICCM_HS,TCM_HS,TCCM_HS
 SG_ EngIntAirTmpV : 5|1@0+ (1,0) [0|1] ""  LVMPC_HS,TCM_HS,CGM_HS,HCP_T_HS,ICCM_B_HS,ICCM_OBD_HS,ICCM_HS,RDCM_HS,FICM_HS,BSM_HS,VICM_HS,EBCM_OBD_HS,EBCM_HS,HCP_B_HS,GPCM_HS,TCP_HS,ONSTAR_HS,SADS_HS,BCP_HS,TCCM_HS,HCP_HS,EDI_HS,BCM_HS
 SG_ EngIntAirTmp : 31|8@0+ (1,-40) [-40|215] "deg C"  LVMPC_HS,TCM_HS,CGM_HS,HCP_T_HS,ICCM_B_HS,ICCM_OBD_HS,ICCM_HS,RDCM_HS,FICM_HS,BSM_HS,VICM_HS,EBCM_OBD_HS,EBCM_HS,HCP_B_HS,GPCM_HS,TCP_HS,ONSTAR_HS,SADS_HS,BCP_HS,TCCM_HS,HCP_HS,EDI_HS,BCM_HS
 SG_ EngCltTmpV : 6|1@0+ (1,0) [0|1] ""  TCM_HS,V2V_HS,CGM_HS,HCP_T_HS,LVMPC_HS,EPS_HS,VCM_HS,FICM_HS,ICCM_B_HS,ICCM_OBD_HS,ICCM_HS,HCP_B_HS,BSM_HS,VICM_HS,GPCM_HS,TCP_HS,ONSTAR_HS,SADS_HS,HCP_HS,EDI_HS,BCP_HS,BCM_HS,EBCM_OBD_HS,EBCM_HS
 SG_ EngCltTmp : 23|8@0+ (1,-40) [-40|215] "deg C"  TCM_HS,V2V_HS,CGM_HS,HCP_T_HS,LVMPC_HS,EPS_HS,VCM_HS,FICM_HS,ICCM_B_HS,ICCM_OBD_HS,ICCM_HS,HCP_B_HS,BSM_HS,VICM_HS,GPCM_HS,TCP_HS,ONSTAR_HS,SADS_HS,HCP_HS,EDI_HS,BCP_HS,BCM_HS,EBCM_OBD_HS,EBCM_HS
 SG_ BarPrsAbsV : 7|1@0+ (1,0) [0|1] ""  TTPM_HS,TCM_HS,CGM_HS,HCP_T_HS,GPCM_HS,EDI_HS,BSM_HS,VICM_HS,FICM_HS,EBCM_OBD_HS,EBCM_HS,BCP_HS,HCP_HS,ICCM_B_HS,ICCM_OBD_HS,ICCM_HS,BCM_HS
 SG_ BarPrsAbs : 15|8@0+ (0.5,0) [0|127.5] "kPa"  TTPM_HS,TCM_HS,CGM_HS,HCP_T_HS,GPCM_HS,EDI_HS,BSM_HS,VICM_HS,FICM_HS,EBCM_OBD_HS,EBCM_HS,BCP_HS,HCP_HS,ICCM_B_HS,ICCM_OBD_HS,ICCM_HS,BCM_HS

BO_ 665 PTEI_Bkup_Alt_Fuel_Syst_Cmd_HS: 6 ECM_HS
 SG_ BiFuelRflGaslinIndReq : 45|3@0+ (1,0) [0|7] ""  CGM_HS,BCM_HS
 SG_ EngFuelCntlState_299 : 47|2@0+ (1,0) [0|3] ""  CGM_HS,FICM_HS
 SG_ TotAltFClsLpCBn2LwRes : 39|8@0- (0.0078125,0) [-1|0.9921875] ""  CGM_HS,FICM_HS
 SG_ TotAltFClsLpCBn1LwRes : 15|8@0- (0.0078125,0) [-1|0.9921875] ""  CGM_HS,FICM_HS
 SG_ RelBsAltFuelMassLwRes : 31|8@0+ (0.00390625,0) [0|0.99609375] ""  CGM_HS,FICM_HS
 SG_ RdGasFuelDsblAct : 7|1@0+ (1,0) [0|1] ""  CGM_HS,FICM_HS
 SG_ RdDistFuelMdCmd : 2|3@0+ (1,0) [0|7] ""  CGM_HS,FICM_HS
 SG_ PetrolFuelSysReqAval : 4|2@0+ (1,0) [0|3] ""  CGM_HS,FICM_HS
 SG_ AltFuelSysReqAlwd : 5|1@0+ (1,0) [0|1] ""  CGM_HS,FICM_HS
 SG_ AltFuelInjHCmdLwRes : 16|1@0+ (1,0) [0|1] ""  CGM_HS,FICM_HS
 SG_ AltFuelInjGCmdLwRes : 17|1@0+ (1,0) [0|1] ""  CGM_HS,FICM_HS
 SG_ AltFuelInjFCmdLwRes : 18|1@0+ (1,0) [0|1] ""  CGM_HS,FICM_HS
 SG_ AltFuelInjECmdLwRes : 19|1@0+ (1,0) [0|1] ""  CGM_HS,FICM_HS
 SG_ AltFuelInjDCmdLwRes : 20|1@0+ (1,0) [0|1] ""  CGM_HS,FICM_HS
 SG_ AltFuelInjCCmdLwRes : 21|1@0+ (1,0) [0|1] ""  CGM_HS,FICM_HS
 SG_ AltFuelInjBCmdLwRes : 22|1@0+ (1,0) [0|1] ""  CGM_HS,FICM_HS
 SG_ AltFuelInjACmdLwRes : 23|1@0+ (1,0) [0|1] ""  CGM_HS,FICM_HS

BO_ 985 PPEI_Drvr_Perform_Feedback_Stat: 5 ECM_HS
 SG_ ManTransIndReq : 5|3@0+ (1,0) [0|7] ""  CGM_HS,BCM_HS
 SG_ DrvEffInd : 23|8@0- (0.78125,0) [-100|99.21875] "%"  CGM_HS,BCM_HS
 SG_ EngIntkArBstPrExtRng : 24|9@0+ (1,-110) [-110|401] "kPa"  CGM_HS,BCM_HS
 SG_ EngIntkArBstPrExtRngV : 6|1@0+ (1,0) [0|1] ""  CGM_HS,BCM_HS
 SG_ EDADS_RcmndtFwdGr : 11|4@0+ (1,0) [0|15] ""  CGM_HS,BCM_HS
 SG_ EDADS_CrntFwdMsdG : 15|4@0+ (1,0) [0|15] ""  CGM_HS,BCM_HS
 SG_ EDADS_ShftIndStat : 1|2@0+ (1,0) [0|3] ""  CGM_HS,BCM_HS
 SG_ EDADS_EcoDrvShftIO : 2|1@0+ (1,0) [0|1] ""  CGM_HS,BCM_HS

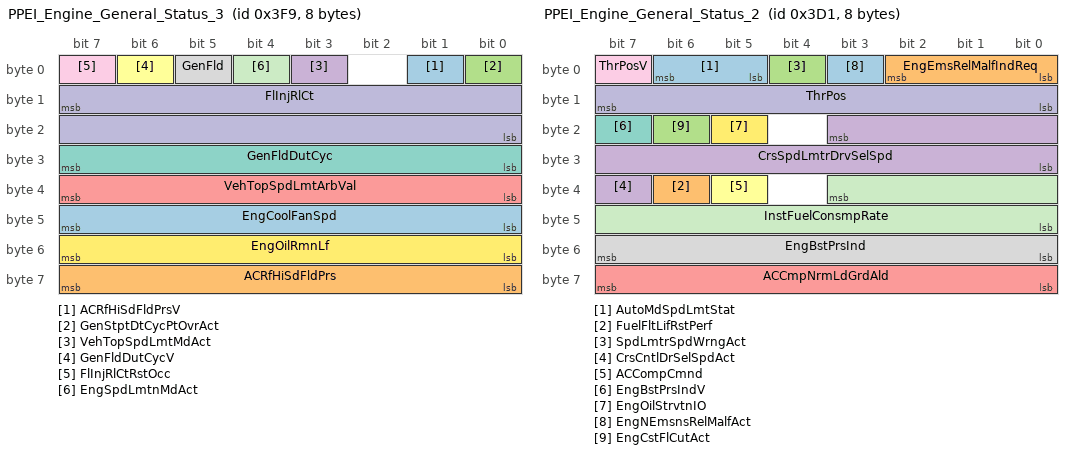
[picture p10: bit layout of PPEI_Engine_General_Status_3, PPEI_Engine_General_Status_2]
BO_ 1017 PPEI_Engine_General_Status_3: 8 ECM_HS
 SG_ ACRfHiSdFldPrsV : 1|1@0+ (1,0) [0|1] ""  CGM_HS,ICCM_B_HS,ICCM_OBD_HS,ICCM_HS,BSM_HS,VICM_HS,TCP_HS,ONSTAR_HS,BCM_HS
 SG_ ACRfHiSdFldPrs : 63|8@0+ (14,0) [0|3570] "kPaG"  CGM_HS,ICCM_B_HS,ICCM_OBD_HS,ICCM_HS,BSM_HS,VICM_HS,TCP_HS,ONSTAR_HS,BCM_HS
 SG_ GenStptDtCycPtOvrAct : 0|1@0+ (1,0) [0|1] ""  CGM_HS,BCM_HS
 SG_ VehTopSpdLmtMdAct : 3|1@0+ (1,0) [0|1] ""  EOCM2B_IMX6_HS,EOCM2A_IMX6_HS,EOCM2B_K1_HS,EOCM2A_K1_HS,EOCM_F_HS,FCM_HS,CGM_HS,PTO_HS,BCM_HS
 SG_ VehTopSpdLmtArbVal : 39|8@0+ (2,0) [0|510] "km / h"  EOCM2B_IMX6_HS,EOCM2A_IMX6_HS,EOCM_F_HS,FCM_HS,EOCM2B_K1_HS,EOCM2A_K1_HS,CGM_HS,PTO_HS,BCM_HS
 SG_ GenFldDutCycV : 6|1@0+ (1,0) [0|1] ""  CGM_HS,BCM_HS
 SG_ GenFldDutCyc : 31|8@0+ (0.392157,0) [0|100.000035] "%"  CGM_HS,BCM_HS
 SG_ GenFld : 5|1@0+ (1,0) [0|1] ""  CGM_HS,TCP_HS,ONSTAR_HS,BCM_HS
 SG_ FlInjRlCtRstOcc : 7|1@0+ (1,0) [0|1] ""  CGM_HS,BSM_HS,VICM_HS,TCP_HS,ONSTAR_HS,BCM_HS
 SG_ FlInjRlCt : 15|16@0+ (3.05176e-05,0) [0|1.999970916] "liters"  CGM_HS,BSM_HS,VICM_HS,TCP_HS,ONSTAR_HS,BCM_HS
 SG_ EngSpdLmtnMdAct : 4|1@0+ (1,0) [0|1] ""  CGM_HS,BCM_HS
 SG_ EngOilRmnLf : 55|8@0+ (0.392157,0) [0|100.000035] "%"  CGM_HS,BCM_HS
 SG_ EngCoolFanSpd : 47|8@0+ (0.392157,0) [0|100.000035] "%"  CGM_HS,BSM_HS,VICM_HS,ICCM_B_HS,ICCM_OBD_HS,ICCM_HS,BCM_HS

BO_ 977 PPEI_Engine_General_Status_2: 8 ECM_HS
 SG_ AutoMdSpdLmtStat : 6|2@0+ (1,0) [0|3] ""  EOCM2B_K1_HS,CGM_HS,EOCM2A_K1_HS,BCM_HS
 SG_ FuelFltLifRstPerf : 38|1@0+ (1,0) [0|1] ""  EOCM2B_K1_HS,CGM_HS,EOCM2A_K1_HS,TCP_HS,ONSTAR_HS,BCM_HS
 SG_ SpdLmtrSpdWrngAct : 4|1@0+ (1,0) [0|1] ""  EOCM2B_K1_HS,CGM_HS,EOCM2A_K1_HS,BCM_HS
 SG_ CrsCntlDrSelSpdAct : 39|1@0+ (1,0) [0|1] ""  EOCM2B_K1_HS,CGM_HS,EOCM2A_K1_HS,BCM_HS
 SG_ ACCmpNrmLdGrdAld : 63|8@0+ (0.1,0) [0|25.5] "dm3/m/s"  EOCM2B_K1_HS,CGM_HS,EOCM2A_K1_HS,BCM_HS
 SG_ ACCompCmnd : 37|1@0+ (1,0) [0|1] ""  EOCM2B_K1_HS,CGM_HS,EOCM2A_K1_HS,ICCM_B_HS,ICCM_OBD_HS,ICCM_HS,TCM_HS,BCM_HS
 SG_ EngBstPrsIndV : 23|1@0+ (1,0) [0|1] ""  EOCM2B_K1_HS,CGM_HS,EOCM2A_K1_HS,LVMPC_HS,BCM_HS
 SG_ EngBstPrsInd : 55|8@0+ (0.392157,0) [0|100.000035] "%"  EOCM2B_K1_HS,CGM_HS,EOCM2A_K1_HS,LVMPC_HS,BCM_HS
 SG_ ThrPosV : 7|1@0+ (1,0) [0|1] ""  EOCM2B_K1_HS,CGM_HS,EOCM2A_K1_HS,EDI_HS,ACC_HS,EOCM_F_HS,SADS_HS,BCM_HS
 SG_ ThrPos : 15|8@0+ (0.392157,0) [0|100.000035] "%"  EOCM2B_K1_HS,CGM_HS,EOCM2A_K1_HS,EDI_HS,ACC_HS,EOCM_F_HS,SADS_HS,BCM_HS
 SG_ InstFuelConsmpRate : 35|12@0+ (0.025,0) [0|102.375] "ltrs/hr"  EOCM2B_K1_HS,CGM_HS,EOCM2A_K1_HS,EDI_HS,BCM_HS
 SG_ EngOilStrvtnIO : 21|1@0+ (1,0) [0|1] ""  EOCM2B_K1_HS,CGM_HS,EOCM2A_K1_HS,BCM_HS
 SG_ EngNEmsnsRelMalfAct : 3|1@0+ (1,0) [0|1] ""  EOCM2B_K1_HS,CGM_HS,EOCM2A_K1_HS,BCM_HS
 SG_ EngEmsRelMalfIndReq : 2|3@0+ (1,0) [0|7] ""  EOCM2B_K1_HS,CGM_HS,EOCM2A_K1_HS,BCM_HS
 SG_ EngCstFlCutAct : 22|1@0+ (1,0) [0|1] ""  EOCM2B_K1_HS,ESCM_SP_HS,CGM_HS,EOCM2A_K1_HS,TCM_HS,BSM_HS,VICM_HS,BCP_HS,BCM_HS
 SG_ CrsSpdLmtrDrvSelSpd : 19|12@0+ (0.0625,0) [0|255.9375] "km / h"  EOCM2B_K1_HS,CGM_HS,EOCM2A_K1_HS,TCM_HS,BCM_HS

BO_ 201 PPEI_Engine_General_Status_1: 8 ECM_HS
 SG_ Eng12vStrtrMtrCmmdOn : 53|1@0+ (1,0) [0|1] ""  EOCM2B_IMX6_HS,EOCM2A_IMX6_HS,EOCM2B_K2_HS,EOCM2A_K2_HS,ICCM_B_HS,ICCM_OBD_HS,ICCM_HS,EOCM2B_K1_HS,HCP_T_HS,EOCM2A_K1_HS,BCM_HS,DCDC_HS,RDCM_HS,MCP_C_HS,CGM_HS,FICM_HS,TCM_HS,HCP_HS,BCP_HS,MCP_B_HS,MCP_A_HS,EPB_HS,EBCM_OBD_HS,EBCM_HS,TCCM_HS,VES_HS,EPS_HS
 SG_ EngCntrlRunCrnkTrmSt : 52|1@0+ (1,0) [0|1] ""  EOCM2B_IMX6_HS,EOCM2A_IMX6_HS,EOCM2B_K2_HS,EOCM2A_K2_HS,EOCM2B_K1_HS,BCM_HS,EBOOST_OBD_HS,HCP_T_HS,EOCM2A_K1_HS,TRCM_HS,MCP_C_HS,CGM_HS,TCM_HS,EBCM_OBD_HS,EBCM_HS,MCP_B_HS,MCP_A_HS,HCP_HS,BCP_HS,VITM_OBD_HS,BSM_HS,VICM_HS,ICCM_B_HS,ICCM_OBD_HS,ICCM_HS,FICM_HS
 SG_ EngAirIntBstPrV : 51|1@0+ (1,0) [0|1] ""  EOCM2B_IMX6_HS,EOCM2A_IMX6_HS,EOCM2B_K2_HS,EOCM2A_K2_HS,EOCM2B_K1_HS,EOCM2A_K1_HS,LVMPC_HS,CGM_HS,FICM_HS,EBCM_OBD_HS,EBCM_HS,EDI_HS,BCM_HS
 SG_ EngAirIntBstPr : 63|8@0- (1,0) [-128|127] "kPaG"  EOCM2B_IMX6_HS,EOCM2A_IMX6_HS,EOCM2B_K2_HS,EOCM2A_K2_HS,EOCM2B_K1_HS,EOCM2A_K1_HS,LVMPC_HS,CGM_HS,FICM_HS,EBCM_OBD_HS,EBCM_HS,EDI_HS,BCM_HS
 SG_ SpdLmtrSpdWrngEnbld : 47|1@0+ (1,0) [0|1] ""  EOCM2B_IMX6_HS,EOCM2A_IMX6_HS,EOCM2B_K2_HS,EOCM2A_K2_HS,EOCM2B_K1_HS,EOCM2A_K1_HS,PTO_HS,CGM_HS,BCM_HS
 SG_ EngCylDactEvntPndg : 54|1@0+ (1,0) [0|1] ""  EOCM2B_IMX6_HS,EOCM2A_IMX6_HS,EOCM2B_K2_HS,EOCM2A_K2_HS,EOCM2B_K1_HS,EOCM2A_K1_HS,ICCM_B_HS,ICCM_OBD_HS,ICCM_HS,CGM_HS,AMP_HS
 SG_ EngCylDeactMd : 43|2@0+ (1,0) [0|3] ""  EOCM2B_IMX6_HS,EOCM2A_IMX6_HS,EOCM2B_K2_HS,EOCM2A_K2_HS,RDCM_HS,TCCM_HS,EOCM2B_K1_HS,FICM_HS,HCP_HS,HCP_T_HS,EOCM2A_K1_HS,CGM_HS,ICCM_B_HS,ICCM_OBD_HS,ICCM_HS,AMP_HS,BCM_HS
 SG_ RmVhStrtEngRng : 55|1@0+ (1,0) [0|1] ""  EOCM2B_IMX6_HS,EOCM2A_IMX6_HS,EOCM2B_K2_HS,EOCM2A_K2_HS,EOCM2B_K1_HS,EOCM2A_K1_HS,EBCM_OBD_HS,EBCM_HS,CGM_HS,TCCM_HS,EPB_HS,BCM_HS
 SG_ PFEngSpdCmndSpcd : 45|1@0+ (1,0) [0|1] ""  EOCM2B_IMX6_HS,EOCM2A_IMX6_HS,EOCM2B_K2_HS,EOCM2A_K2_HS,EOCM2B_K1_HS,EOCM2A_K1_HS,CGM_HS,BCM_HS,PTO_HS
 SG_ DrThrtlOvrrdDetProtVal : 25|2@0+ (1,0) [0|3] ""  EOCM2B_IMX6_HS,EOCM2A_IMX6_HS,EOCM2B_K2_HS,EOCM2A_K2_HS,V2V_HS,EOCM2B_K1_HS,PTO_HS,EOCM2A_K1_HS,CGM_HS,ACC_HS,EBCM_OBD_HS,EBCM_HS
 SG_ DrThrtlOvrdDetAlvRlCnt : 27|2@0+ (1,0) [0|3] ""  EOCM2B_IMX6_HS,EOCM2A_IMX6_HS,EOCM2B_K2_HS,EOCM2A_K2_HS,V2V_HS,EOCM2B_K1_HS,PTO_HS,EOCM2A_K1_HS,CGM_HS,EBCM_OBD_HS,EBCM_HS,ACC_HS
 SG_ PltfrmEngSpdCmdInhtRq : 44|1@0+ (1,0) [0|1] ""  EOCM2B_IMX6_HS,EOCM2A_IMX6_HS,EOCM2B_K2_HS,EOCM2A_K2_HS,EOCM2B_K1_HS,EOCM2A_K1_HS,CGM_HS,BCM_HS,PTO_HS
 SG_ PT_BrkPedDscrtInpStatV : 41|1@0+ (1,0) [0|1] ""  EOCM2B_IMX6_HS,EOCM2A_IMX6_HS,EOCM2B_K2_HS,EOCM2A_K2_HS,FCM_HS,EOCM2B_K1_HS,HCP_HS,HCP_T_HS,TCM_HS,EOCM2A_K1_HS,CGM_HS,TCCM_HS,BCP_HS,PTO_HS,ACC_HS,EBCM_OBD_HS,EBCM_HS
 SG_ PT_BrkPedDscrtInpStat : 40|1@0+ (1,0) [0|1] ""  EOCM2B_IMX6_HS,EOCM2A_IMX6_HS,EOCM2B_K2_HS,EOCM2A_K2_HS,FCM_HS,EOCM2B_K1_HS,HCP_HS,HCP_T_HS,TCM_HS,EOCM2A_K1_HS,CGM_HS,TCCM_HS,BCP_HS,PTO_HS,ACC_HS,EBCM_OBD_HS,EBCM_HS
 SG_ AccActPos : 39|8@0+ (0.392157,0) [0|100.000035] "%"  EOCM2B_IMX6_HS,EOCM2A_IMX6_HS,EOCM2B_K2_HS,EOCM2A_K2_HS,TCP_HS,ONSTAR_HS,VPM_HS,EOCM2B_K1_HS,V2V_HS,HCP_T_HS,EOCM2A_K1_HS,AVM_HS,LVMPC_HS,EDI_HS,ICCM_B_HS,ICCM_OBD_HS,ICCM_HS,CGM_HS,HCP_B_HS,BSM_HS,VICM_HS,HCP_HS,EBCM_OBD_HS,EBCM_HS,BCP_HS,AHL_AFL_HS,EPB_HS,SADS_HS,RDCM_HS,BCM_HS,TCM_HS,TCCM_HS
 SG_ CrsCntEnbld : 29|1@0+ (1,0) [0|1] ""  EOCM2B_IMX6_HS,EOCM2A_IMX6_HS,EOCM2B_K2_HS,EOCM2A_K2_HS,EBCM_OBD_HS,EBCM_HS,FCM_HS,EOCM2B_K1_HS,V2V_HS,EOCM2A_K1_HS,CGM_HS,PTO_HS,ACC_HS,EOCM_F_HS,BCM_HS
 SG_ CrsCntAtv : 30|1@0+ (1,0) [0|1] ""  EOCM2B_IMX6_HS,EOCM2A_IMX6_HS,EOCM2B_K2_HS,EOCM2A_K2_HS,EOCM2B_K1_HS,V2V_HS,HCP_T_HS,EOCM2A_K1_HS,CGM_HS,EBCM_OBD_HS,EBCM_HS,RDCM_HS,PTO_HS,BCP_HS,EPB_HS,BCM_HS,TCM_HS
 SG_ DrvThrottlOvrrdDet : 28|1@0+ (1,0) [0|1] ""  EOCM2B_IMX6_HS,EOCM2A_IMX6_HS,EOCM2B_K2_HS,EOCM2A_K2_HS,V2V_HS,EOCM2B_K1_HS,EOCM2A_K1_HS,CGM_HS,PTO_HS,ACC_HS,EBCM_OBD_HS,EBCM_HS,BCM_HS
 SG_ PT_CrnkAct : 6|1@0+ (1,0) [0|1] ""  EOCM2B_IMX6_HS,EOCM2A_IMX6_HS,EOCM2B_K2_HS,EOCM2A_K2_HS,TRCM_HS,EOCM2B_K1_HS,HCP_T_HS,EOCM2A_K1_HS,BSM_HS,VICM_HS,VCM_HS,CGM_HS,FICM_HS,VES_HS,EPS_HS,EBCM_OBD_HS,EBCM_HS,HCP_HS,PTO_HS,BCP_HS,ICCM_B_HS,ICCM_OBD_HS,ICCM_HS
 SG_ PTRunAbrt : 4|1@0+ (1,0) [0|1] ""  EOCM2B_IMX6_HS,EOCM2A_IMX6_HS,EOCM2B_K2_HS,EOCM2A_K2_HS,EOCM2B_K1_HS,HCP_T_HS,EOCM2A_K1_HS,CGM_HS,HCP_HS,BCP_HS,BCM_HS
 SG_ PTO_PT_RunAbrtd : 3|1@0+ (1,0) [0|1] ""  EOCM2B_IMX6_HS,EOCM2A_IMX6_HS,EOCM2B_K2_HS,EOCM2A_K2_HS,EOCM2B_K1_HS,EOCM2A_K1_HS,PTO_HS,CGM_HS,BCM_HS
 SG_ PTCrnkAbrted : 5|1@0+ (1,0) [0|1] ""  EOCM2B_IMX6_HS,EOCM2A_IMX6_HS,EOCM2B_K2_HS,EOCM2A_K2_HS,EOCM2B_K1_HS,HCP_T_HS,EOCM2A_K1_HS,CGM_HS,HCP_B_HS,HCP_HS,BCP_HS,PTO_HS,BCM_HS
 SG_ EngSpdStat : 1|2@0+ (1,0) [0|3] ""  EOCM2B_IMX6_HS,EOCM2A_IMX6_HS,EOCM2B_K2_HS,EOCM2A_K2_HS,EOCM2B_K1_HS,V2V_HS,HCP_T_HS,TCM_HS,EOCM2A_K1_HS,AVM_HS,PTO_HS,AHL_AFL_HS,CGM_HS,FICM_HS,PFAF_HS,HCP_HS,GPCM_HS,AMP_HS,BSM_HS,VICM_HS,VES_HS,EPS_HS,TCCM_HS,BCP_HS,ICCM_B_HS,ICCM_OBD_HS,ICCM_HS,RDCM_HS,EBCM_OBD_HS,EBCM_HS,EPB_HS,ACC_HS,BCM_HS,SADS_HS
 SG_ EngSpd : 15|16@0+ (0.25,0) [0|16383.75] "rpm"  EOCM2B_IMX6_HS,EOCM2A_IMX6_HS,EOCM2B_K2_HS,EOCM2A_K2_HS,FCM_HS,TCM_HS,EOCM2B_K1_HS,V2V_HS,HCP_T_HS,EOCM2A_K1_HS,AVM_HS,LVMPC_HS,DCDC_HS,PTO_HS,AHL_AFL_HS,CGM_HS,EOCM_F_HS,FICM_HS,HCP_B_HS,PFAF_HS,GPCM_HS,AMP_HS,TCP_HS,ONSTAR_HS,BSM_HS,VICM_HS,VES_HS,EPS_HS,TCCM_HS,HCP_HS,BCP_HS,EDI_HS,ICCM_B_HS,ICCM_OBD_HS,ICCM_HS,EPB_HS,RDCM_HS,EBCM_OBD_HS,EBCM_HS,ACC_HS,BCM_HS,SADS_HS
 SG_ EngRunAtv : 7|1@0+ (1,0) [0|1] ""  EOCM2B_IMX6_HS,EOCM2A_IMX6_HS,EOCM2B_K2_HS,EOCM2A_K2_HS,FCM_HS,EOCM2B_K1_HS,ESCM_SP_HS,EOCM2A_K1_HS,DCDC_HS,VCM_HS,RDCM_HS,CGM_HS,HCP_B_HS,ACC_HS,BSM_HS,VICM_HS,APPS_HS,EOCM_F_HS,BCP_HS,TCP_HS,ONSTAR_HS,ICCM_B_HS,ICCM_OBD_HS,ICCM_HS,ALC_HS,VES_HS,EPS_HS,EBCM_OBD_HS,EBCM_HS,AHL_AFL_HS,EPB_HS,SADS_HS,BCM_HS,TCCM_HS
 SG_ EngIdlAtv : 2|1@0+ (1,0) [0|1] ""  EOCM2B_IMX6_HS,EOCM2A_IMX6_HS,EOCM2B_K2_HS,EOCM2A_K2_HS,EOCM2B_K1_HS,EOCM2A_K1_HS,PTO_HS,CGM_HS,FICM_HS,EPB_HS,BCM_HS
 SG_ AccActPosV : 31|1@0+ (1,0) [0|1] ""  EOCM2B_IMX6_HS,EOCM2A_IMX6_HS,EOCM2B_K2_HS,EOCM2A_K2_HS,VPM_HS,EOCM2B_K1_HS,V2V_HS,HCP_T_HS,EOCM2A_K1_HS,AVM_HS,LVMPC_HS,EDI_HS,ICCM_B_HS,ICCM_OBD_HS,ICCM_HS,CGM_HS,HCP_B_HS,BSM_HS,VICM_HS,HCP_HS,EBCM_OBD_HS,EBCM_HS,BCP_HS,AHL_AFL_HS,EPB_HS,SADS_HS,BCM_HS,RDCM_HS,TCM_HS,TCCM_HS

BO_ 501 PPEI_Trans_General_Status_2: 8 ECM_HS
 SG_ ElcRngSelDrvAct : 39|1@0+ (1,0) [0|1] ""  BCM_HS,CGM_HS
 SG_ TmpDrvrShftCtlAct : 45|1@0+ (1,0) [0|1] ""  EOCM2B_IMX6_HS,EOCM2A_IMX6_HS,EOCM2B_K2_HS,EOCM2A_K2_HS,EOCM2B_K1_HS,EOCM2A_K1_HS,CGM_HS,BCM_HS
 SG_ EngRecDwnshftIO : 54|1@0+ (1,0) [0|1] ""  EOCM2B_IMX6_HS,EOCM2A_IMX6_HS,EOCM2B_K2_HS,EOCM2A_K2_HS,EOCM2B_K1_HS,EOCM2A_K1_HS,CGM_HS,BCM_HS
 SG_ TrnsPattSelEcnMdOCm : 52|1@0+ (1,0) [0|1] ""  EOCM2B_IMX6_HS,EOCM2A_IMX6_HS,EOCM2B_K2_HS,EOCM2A_K2_HS,EOCM2B_K1_HS,EOCM2A_K1_HS,CGM_HS,ICCM_B_HS,ICCM_OBD_HS,ICCM_HS,ECM_HS
 SG_ CltStartSwAtvV : 38|1@0+ (1,0) [0|1] ""  EOCM2B_IMX6_HS,EOCM2A_IMX6_HS,EOCM2B_K2_HS,EOCM2A_K2_HS,EOCM2B_K1_HS,EOCM2A_K1_HS,V2V_HS,CGM_HS,TCCM_HS,RDCM_HS,BCM_HS
 SG_ CltStartSwAtv : 37|1@0+ (1,0) [0|1] ""  EOCM2B_IMX6_HS,EOCM2A_IMX6_HS,EOCM2B_K2_HS,EOCM2A_K2_HS,EOCM2B_K1_HS,EOCM2A_K1_HS,V2V_HS,CGM_HS,TCCM_HS,BCM_HS,RDCM_HS
 SG_ CltchPdlActPosV : 55|1@0+ (1,0) [0|1] ""  EOCM2B_IMX6_HS,EOCM2A_IMX6_HS,EOCM2B_K2_HS,EOCM2A_K2_HS,EOCM2B_K1_HS,EOCM2A_K1_HS,CGM_HS,TCCM_HS,LVMPC_HS,EDI_HS,EBCM_OBD_HS,EBCM_HS,ICCM_B_HS,ICCM_OBD_HS,ICCM_HS,ECM_HS,EPB_HS,RDCM_HS
 SG_ CltchPdlActPos : 63|8@0+ (0.392157,0) [0|100.000035] "%"  EOCM2B_IMX6_HS,EOCM2A_IMX6_HS,EOCM2B_K2_HS,EOCM2A_K2_HS,EOCM2B_K1_HS,EOCM2A_K1_HS,CGM_HS,TCCM_HS,LVMPC_HS,EDI_HS,EBCM_OBD_HS,EBCM_HS,ICCM_B_HS,ICCM_OBD_HS,ICCM_HS,ECM_HS,EPB_HS,RDCM_HS
 SG_ TrnsEngdStateV : 50|1@0+ (1,0) [0|1] ""  EOCM2B_IMX6_HS,EOCM2A_IMX6_HS,EOCM2B_K2_HS,EOCM2A_K2_HS,EOCM2B_K1_HS,EOCM2A_K1_HS,FCM_HS,CGM_HS,EOCM_F_HS,ICCM_B_HS,ICCM_OBD_HS,ICCM_HS,BCP_HS,ACC_HS,EBCM_OBD_HS,EBCM_HS,EPB_HS,SADS_HS,RDCM_HS,AHL_AFL_HS,BCM_HS
 SG_ TrnsEngdState : 49|2@0+ (1,0) [0|3] ""  EOCM2B_IMX6_HS,EOCM2A_IMX6_HS,EOCM2B_K2_HS,EOCM2A_K2_HS,EOCM2B_K1_HS,EOCM2A_K1_HS,FCM_HS,CGM_HS,EOCM_F_HS,ICCM_B_HS,ICCM_OBD_HS,ICCM_HS,BCP_HS,ACC_HS,EBCM_OBD_HS,EBCM_HS,EPB_HS,SADS_HS,RDCM_HS,AHL_AFL_HS,BCM_HS
 SG_ TrnsShftLvrLckRqd : 47|1@0+ (1,0) [0|1] ""  EOCM2B_IMX6_HS,EOCM2A_IMX6_HS,EOCM2B_K2_HS,EOCM2A_K2_HS,EOCM2B_K1_HS,EOCM2A_K1_HS,CGM_HS,ICCM_B_HS,ICCM_OBD_HS,ICCM_HS,BCM_HS
 SG_ TransTUDMdStat : 41|2@0+ (1,0) [0|3] ""  EOCM2B_IMX6_HS,EOCM2A_IMX6_HS,EOCM2B_K2_HS,EOCM2A_K2_HS,EOCM2B_K1_HS,EOCM2A_K1_HS,CGM_HS,ICCM_B_HS,ICCM_OBD_HS,ICCM_HS,EBCM_OBD_HS,EBCM_HS,HCP_B_HS,BCP_HS,ACC_HS,EOCM_F_HS,BCM_HS,ECM_HS
 SG_ TrnCrpMdAtv : 46|1@0+ (1,0) [0|1] ""  EOCM2B_IMX6_HS,EOCM2A_IMX6_HS,EOCM2B_K2_HS,EOCM2A_K2_HS,EOCM2B_K1_HS,EOCM2A_K1_HS,CGM_HS,ICCM_B_HS,ICCM_OBD_HS,ICCM_HS,ECM_HS,BCM_HS
 SG_ TrnsSkpShftIO : 23|1@0+ (1,0) [0|1] ""  EOCM2B_IMX6_HS,EOCM2A_IMX6_HS,EOCM2B_K2_HS,EOCM2A_K2_HS,EOCM2B_K1_HS,EOCM2A_K1_HS,CGM_HS,ICCM_B_HS,ICCM_OBD_HS,ICCM_HS,BCM_HS
 SG_ TrnsSftMdStat : 34|3@0+ (1,0) [0|7] ""  EOCM2B_IMX6_HS,EOCM2A_IMX6_HS,EOCM2B_K2_HS,EOCM2A_K2_HS,EOCM2B_K1_HS,EOCM2A_K1_HS,CGM_HS,ICCM_B_HS,ICCM_OBD_HS,ICCM_HS,EBCM_OBD_HS,EBCM_HS,BCM_HS
 SG_ TrnsRngInhbtStat : 31|3@0+ (1,0) [0|7] ""  EOCM2B_IMX6_HS,EOCM2A_IMX6_HS,EOCM2B_K2_HS,EOCM2A_K2_HS,EOCM2B_K1_HS,EOCM2A_K1_HS,CGM_HS,ICCM_B_HS,ICCM_OBD_HS,ICCM_HS,BCM_HS
 SG_ TopTrvlCltchSwActV : 15|1@0+ (1,0) [0|1] ""  EOCM2B_IMX6_HS,EOCM2A_IMX6_HS,EOCM2B_K2_HS,EOCM2A_K2_HS,FCM_HS,EOCM2B_K1_HS,EOCM2A_K1_HS,EOCM_F_HS,CGM_HS,PTO_HS,RDCM_HS,BCM_HS,ACC_HS,EBCM_OBD_HS,EBCM_HS,EPB_HS
 SG_ TopTrvlCltchSwAct : 14|1@0+ (1,0) [0|1] ""  EOCM2B_IMX6_HS,EOCM2A_IMX6_HS,EOCM2B_K2_HS,EOCM2A_K2_HS,FCM_HS,EOCM2B_K1_HS,EOCM2A_K1_HS,EOCM_F_HS,CGM_HS,PTO_HS,RDCM_HS,BCM_HS,EPB_HS,ACC_HS,EBCM_OBD_HS,EBCM_HS
 SG_ EngRecmndUpshftIO : 22|1@0+ (1,0) [0|1] ""  EOCM2B_IMX6_HS,EOCM2A_IMX6_HS,EOCM2B_K2_HS,EOCM2A_K2_HS,EOCM2B_K1_HS,EOCM2A_K1_HS,CGM_HS,BCM_HS
 SG_ DrvtShftCntrlTrgtGear : 19|4@0+ (1,0) [0|15] ""  EOCM2B_IMX6_HS,EOCM2A_IMX6_HS,EOCM2B_K2_HS,EOCM2A_K2_HS,EOCM2B_K1_HS,EOCM2A_K1_HS,CGM_HS,ICCM_B_HS,ICCM_OBD_HS,ICCM_HS,BCM_HS
 SG_ DrShftCntrlReqDndIO : 21|1@0+ (1,0) [0|1] ""  EOCM2B_IMX6_HS,EOCM2A_IMX6_HS,EOCM2B_K2_HS,EOCM2A_K2_HS,EOCM2B_K1_HS,EOCM2A_K1_HS,CGM_HS,ICCM_B_HS,ICCM_OBD_HS,ICCM_HS,BCM_HS
 SG_ TrnShftPtrnActStat : 44|3@0+ (1,0) [0|7] ""  EOCM2B_IMX6_HS,EOCM2A_IMX6_HS,EOCM2B_K2_HS,EOCM2A_K2_HS,EOCM2B_K1_HS,EOCM2A_K1_HS,CGM_HS,ICCM_B_HS,ICCM_OBD_HS,ICCM_HS,ALC_HS,AHL_AFL_HS,VES_HS,EPS_HS,SADS_HS,BCM_HS,EBCM_OBD_HS,EBCM_HS
 SG_ TrnsFldPrsPrsnt : 51|1@0+ (1,0) [0|1] ""  EOCM2B_IMX6_HS,EOCM2A_IMX6_HS,EOCM2B_K2_HS,EOCM2A_K2_HS,EOCM2B_K1_HS,EOCM2A_K1_HS,CGM_HS,ECM_HS
 SG_ TrnsShftLvrPos : 27|4@0+ (1,0) [0|15] ""  EOCM2B_IMX6_HS,EOCM2A_IMX6_HS,EOCM2B_K2_HS,EOCM2A_K2_HS,TCCM_HS,LVMPC_HS,CSM_HS,FCM_HS,RDCM_HS,EOCM2B_K1_HS,EOCM2A_K1_HS,V2V_HS,CGM_HS,HCP_T_HS,PTO_HS,EPS_HS,ICCM_B_HS,ICCM_OBD_HS,ICCM_HS,HMIM_HS,HCP_B_HS,EOCM_F_HS,BSM_HS,VICM_HS,HCP_HS,BCP_HS,EPB_HS,BCM_HS,EBCM_OBD_HS,EBCM_HS,ECM_HS
 SG_ TrnsShftLvrPosV : 28|1@0+ (1,0) [0|1] ""  EOCM2B_IMX6_HS,EOCM2A_IMX6_HS,EOCM2B_K2_HS,EOCM2A_K2_HS,TCCM_HS,LVMPC_HS,CSM_HS,FCM_HS,RDCM_HS,EOCM2B_K1_HS,EOCM2A_K1_HS,V2V_HS,CGM_HS,HCP_T_HS,PTO_HS,ICCM_B_HS,ICCM_OBD_HS,ICCM_HS,HMIM_HS,HCP_B_HS,EPS_HS,EOCM_F_HS,BSM_HS,VICM_HS,HCP_HS,BCP_HS,EPB_HS,BCM_HS,EBCM_OBD_HS,EBCM_HS,ECM_HS
 SG_ TrnsTrqCnvCltCmndMd : 7|3@0+ (1,0) [0|7] ""  EOCM2B_IMX6_HS,EOCM2A_IMX6_HS,EOCM2B_K2_HS,EOCM2A_K2_HS,EOCM2B_K1_HS,EOCM2A_K1_HS,CGM_HS,PTO_HS,BCP_HS,ECM_HS
 SG_ AutoTransComndGear : 11|4@0+ (1,0) [0|15] ""  EOCM2B_IMX6_HS,EOCM2A_IMX6_HS,EOCM2B_K2_HS,EOCM2A_K2_HS,LVMPC_HS,EOCM2B_K1_HS,EOCM2A_K1_HS,FCM_HS,CGM_HS,AVM_HS,ICCM_B_HS,ICCM_OBD_HS,ICCM_HS,TCCM_HS,EOCM_F_HS,RDCM_HS,BCP_HS,EBCM_OBD_HS,EBCM_HS,ACC_HS,BCM_HS,SADS_HS,ECM_HS
 SG_ AutoTransGrSftDirect : 13|2@0+ (1,0) [0|3] ""  EOCM2B_IMX6_HS,EOCM2A_IMX6_HS,EOCM2B_K2_HS,EOCM2A_K2_HS,FCM_HS,EOCM2B_K1_HS,EOCM2A_K1_HS,CGM_HS,AVM_HS,ICCM_B_HS,ICCM_OBD_HS,ICCM_HS,EOCM_F_HS,ACC_HS,BCP_HS,RDCM_HS,EBCM_OBD_HS,EBCM_HS,SADS_HS,ECM_HS
 SG_ TransEstGear : 3|4@0+ (1,0) [0|15] ""  EOCM2B_IMX6_HS,EOCM2A_IMX6_HS,EOCM2B_K2_HS,EOCM2A_K2_HS,AMP_HS,CSM_HS,EOCM2B_K1_HS,EOCM2A_K1_HS,V2V_HS,FCM_HS,CGM_HS,AVM_HS,PTO_HS,LVMPC_HS,EDI_HS,PFAF_HS,HMIM_HS,BCP_HS,EOCM_F_HS,VES_HS,ICCM_B_HS,ICCM_OBD_HS,ICCM_HS,ALC_HS,SADS_HS,TCP_HS,ONSTAR_HS,RDCM_HS,EBCM_OBD_HS,EBCM_HS,EPB_HS,EPS_HS,ACC_HS,BCM_HS,TCCM_HS,ECM_HS
 SG_ TransEstGearV : 4|1@0+ (1,0) [0|1] ""  EOCM2B_IMX6_HS,EOCM2A_IMX6_HS,EOCM2B_K2_HS,EOCM2A_K2_HS,AMP_HS,CSM_HS,EOCM2B_K1_HS,EOCM2A_K1_HS,V2V_HS,FCM_HS,CGM_HS,PFAF_HS,AVM_HS,PTO_HS,LVMPC_HS,EDI_HS,HMIM_HS,BCP_HS,EOCM_F_HS,ICCM_B_HS,ICCM_OBD_HS,ICCM_HS,ALC_HS,VES_HS,EPS_HS,SADS_HS,RDCM_HS,TCP_HS,ONSTAR_HS,EBCM_OBD_HS,EBCM_HS,EPB_HS,ACC_HS,BCM_HS,TCCM_HS,ECM_HS

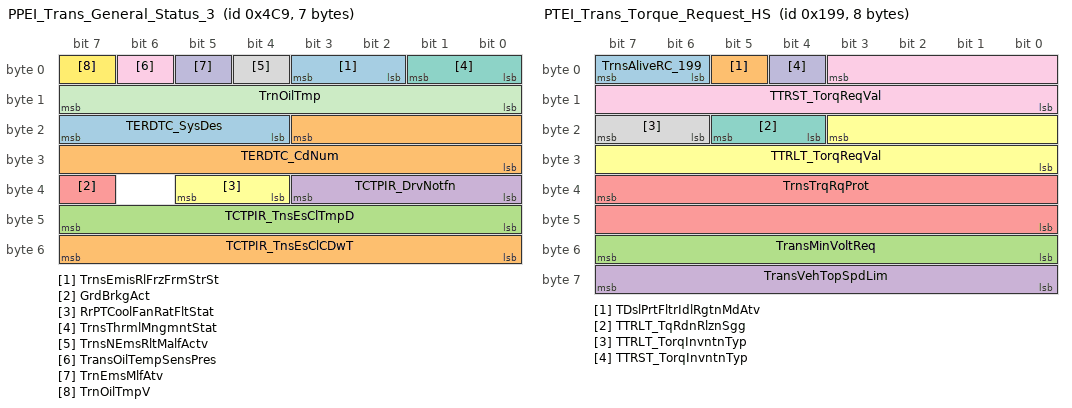
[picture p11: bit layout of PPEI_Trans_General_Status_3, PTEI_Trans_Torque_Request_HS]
BO_ 1225 PPEI_Trans_General_Status_3: 7 ECM_HS
 SG_ TrnsEmisRlFrzFrmStrSt : 3|2@0+ (1,0) [0|3] ""  ECM_HS,CGM_HS
 SG_ TCTPIR_TnsEsClCDwT : 55|8@0+ (0.392157,0) [0|100.000035] "%"  CGM_HS,BCM_HS
 SG_ TCTPIR_TnsEsClTmpD : 47|8@0+ (0.392157,0) [0|100.000035] "%"  CGM_HS,BCM_HS
 SG_ TCTPIR_DrvNotfn : 35|4@0+ (1,0) [0|15] ""  CGM_HS,BCM_HS
 SG_ GrdBrkgAct : 39|1@0+ (1,0) [0|1] ""  CGM_HS,BCM_HS
 SG_ RrPTCoolFanRatFltStat : 37|2@0+ (1,0) [0|3] ""  CGM_HS,ICCM_B_HS,ICCM_OBD_HS,ICCM_HS
 SG_ TrnsThrmlMngmntStat : 1|2@0+ (1,0) [0|3] ""  CGM_HS,PTO_HS,BCM_HS
 SG_ TrnsNEmsRltMalfActv : 4|1@0+ (1,0) [0|1] ""  CGM_HS,TCP_HS,ONSTAR_HS,BCM_HS
 SG_ TransOilTempSensPres : 6|1@0+ (1,0) [0|1] ""  CGM_HS,BSM_HS,VICM_HS,TCP_HS,ONSTAR_HS,TCCM_HS,BCM_HS
 SG_ TrnEmsMlfAtv : 5|1@0+ (1,0) [0|1] ""  CGM_HS,BCM_HS,ECM_HS
 SG_ TrnOilTmp : 15|8@0+ (1,-40) [-40|215] "deg C"  CGM_HS,HCP_T_HS,LVMPC_HS,EDI_HS,VCM_HS,HCP_B_HS,BSM_HS,VICM_HS,TCP_HS,ONSTAR_HS,TCCM_HS,HCP_HS,BCP_HS,BCM_HS,ECM_HS
 SG_ TrnOilTmpV : 7|1@0+ (1,0) [0|1] ""  CGM_HS,HCP_T_HS,LVMPC_HS,EDI_HS,VCM_HS,HCP_B_HS,BSM_HS,VICM_HS,TCP_HS,ONSTAR_HS,TCCM_HS,HCP_HS,BCP_HS,BCM_HS,ECM_HS
 SG_ TERDTC_SysDes : 23|4@0+ (1,0) [0|15] ""  CGM_HS,ECM_HS
 SG_ TERDTC_CdNum : 19|12@0+ (1,0) [0|4095] ""  CGM_HS,ECM_HS

BO_ 409 PTEI_Trans_Torque_Request_HS: 8 TCM_HS
 SG_ TrnsAliveRC_199 : 7|2@0+ (1,0) [0|3] ""  CGM_HS,ECM_HS
 SG_ TDslPrtFltrIdlRgtnMdAtv : 5|1@0+ (1,0) [0|1] ""  CGM_HS,ECM_HS
 SG_ TransMinVoltReq : 55|8@0+ (0.07843,0) [0|19.99965] "volts"  CGM_HS,ECM_HS
 SG_ TransVehTopSpdLim : 63|8@0+ (2,0) [0|510] "km / h"  CGM_HS,ECM_HS
 SG_ TrnsTrqRqProt : 39|16@0+ (1,0) [0|65535] ""  CGM_HS,ECM_HS
 SG_ TTRLT_TorqReqVal : 19|12@0+ (0.5,-848) [-848|1199.5] "Nm"  CGM_HS,ECM_HS
 SG_ TTRLT_TqRdnRlznSgg : 21|2@0+ (1,0) [0|3] ""  CGM_HS,ECM_HS
 SG_ TTRLT_TorqInvntnTyp : 23|2@0+ (1,0) [0|3] ""  CGM_HS,ECM_HS
 SG_ TTRST_TorqReqVal : 3|12@0+ (0.5,-848) [-848|1199.5] "Nm"  CGM_HS,ECM_HS
 SG_ TTRST_TorqInvntnTyp : 4|1@0+ (1,0) [0|1] ""  CGM_HS,ECM_HS

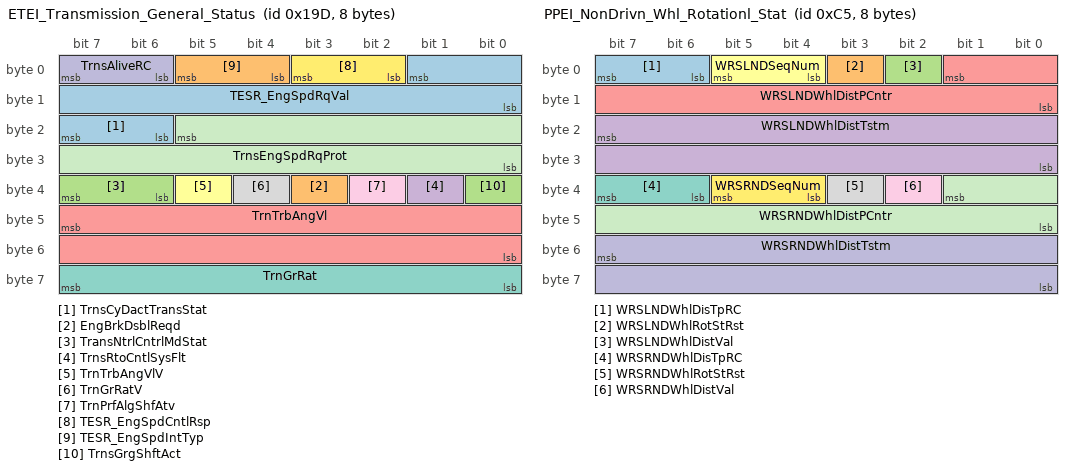
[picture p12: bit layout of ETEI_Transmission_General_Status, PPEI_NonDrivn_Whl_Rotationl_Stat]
BO_ 413 ETEI_Transmission_General_Status: 8 TCM_HS
 SG_ TrnsCyDactTransStat : 23|2@0+ (1,0) [0|3] ""  EOCM2B_K1_HS,CGM_HS,EOCM2A_K1_HS,ECM_HS
 SG_ EngBrkDsblReqd : 35|1@0+ (1,0) [0|1] ""  EOCM2B_K1_HS,EOCM2A_K1_HS,CGM_HS,ECM_HS
 SG_ TransNtrlCntrlMdStat : 39|2@0+ (1,0) [0|3] ""  EOCM2B_K1_HS,CGM_HS,EOCM2A_K1_HS,EBCM_OBD_HS,EBCM_HS,BCM_HS,ECM_HS
 SG_ TrnsRtoCntlSysFlt : 33|1@0+ (1,0) [0|1] ""  EOCM2B_K1_HS,CGM_HS,EOCM2A_K1_HS,ECM_HS
 SG_ TrnTrbAngVl : 47|16@0+ (0.25,0) [0|16383.75] "rpm"  EOCM2B_K1_HS,HCP_B_HS,CGM_HS,TCCM_HS,EOCM2A_K1_HS,BCP_HS,ECM_HS
 SG_ TrnTrbAngVlV : 37|1@0+ (1,0) [0|1] ""  EOCM2B_K1_HS,HCP_B_HS,CGM_HS,TCCM_HS,EOCM2A_K1_HS,BCP_HS,ECM_HS
 SG_ TrnGrRat : 63|8@0+ (0.03125,0) [0|7.96875] ""  EOCM2B_K1_HS,HCP_B_HS,CGM_HS,EOCM2A_K1_HS,EOCM_F_HS,BCP_HS,ECM_HS
 SG_ TrnGrRatV : 36|1@0+ (1,0) [0|1] ""  EOCM2B_K1_HS,HCP_B_HS,CGM_HS,EOCM2A_K1_HS,EOCM_F_HS,BCP_HS,ECM_HS
 SG_ TrnPrfAlgShfAtv : 34|1@0+ (1,0) [0|1] ""  EOCM2B_K1_HS,CGM_HS,EOCM2A_K1_HS,ECM_HS
 SG_ TrnsAliveRC : 7|2@0+ (1,0) [0|3] ""  EOCM2B_K1_HS,CGM_HS,EOCM2A_K1_HS,ECM_HS
 SG_ TrnsEngSpdRqProt : 21|14@0+ (1,0) [0|16383] ""  EOCM2B_K1_HS,CGM_HS,EOCM2A_K1_HS,ECM_HS
 SG_ TESR_EngSpdCntlRsp : 3|2@0+ (1,0) [0|3] ""  EOCM2B_K1_HS,CGM_HS,EOCM2A_K1_HS,ECM_HS
 SG_ TESR_EngSpdRqVal : 1|10@0+ (8,0) [0|8184] "rpm"  EOCM2B_K1_HS,CGM_HS,EOCM2A_K1_HS,ECM_HS
 SG_ TESR_EngSpdIntTyp : 5|2@0+ (1,0) [0|3] ""  EOCM2B_K1_HS,CGM_HS,EOCM2A_K1_HS,ECM_HS
 SG_ TrnsGrgShftAct : 32|1@0+ (1,0) [0|1] ""  EOCM2B_K1_HS,CGM_HS,EOCM2A_K1_HS,ECM_HS

BO_ 257 USDT_Req_to_All_HS_ECUs: 8 TestTool_HS
 SG_ DgnInf : 7|64@0+ (1,0) [0|1.8446744074e+19] ""  EBOOST_OBD_HS,FICM_HS,PFAF_HS,EOCM2B_K1_HS,IPC_HS,VCM_HS,ESCM_SP_HS,ARS_HS,MCP_B_HS,CGM_HS,EBCM_OBD_HS,VITM_OBD_HS,GPCM_HS,DCDC_HS,TTPM_HS,MCP_A_HS,MCP_HS,TCCM_HS,SAS_HS,AVM_HS,PLCM_HS,AMM_HS,CSM_HS,HMIM_HS,AMP_HS,AHL_AFL_HS,EPB_HS,TRCM_HS,ICCM_B_HS,HCP_B_HS,HCP_T_HS,HCP_HS,BCP_HS,ACCM_HS,SADS_HS,ICCM_OBD_HS,ICCM_HS,BSM_HS,VICM_HS,APPS_HS,MCP_C_HS,TCP_HS,VLBS_HS,ONSTAR_HS,EOCM2A_K1_HS,EOCM_F_HS,FCM_HS,RDCM_HS,V2V_HS,PTO_HS,EBCM_HS,VPM_HS,ACC_HS,DEFC_HS,ALC_HS,Dummy_HS,BCM_HS,TCM_HS,VES_HS,EPS_HS,ECM_HS

BO_ 2015 USDT_OBD_Functional_Request: 8 TestTool_HS
 SG_ DgnInf : 7|64@0+ (1,0) [0|1.8446744074e+19] ""  TCP_HS,ONSTAR_HS,CGM_HS,HMIM_HS,FICM_HS,BSM_HS,VICM_HS,ICCM_OBD_HS,ICCM_HS,EBCM_OBD_HS,VITM_OBD_HS,GPCM_HS,HCP_B_HS,HCP_T_HS,HCP_HS,BCP_HS,TCM_HS,ECM_HS

BO_ 2016 USDT_Req_to_ECM_HS: 8 TestTool_HS
 SG_ DgnInf : 7|64@0+ (1,0) [0|1.8446744074e+19] ""  TCP_HS,ONSTAR_HS,CGM_HS,HMIM_HS,ECM_HS

BO_ 197 PPEI_NonDrivn_Whl_Rotationl_Stat: 8 EBCM_HS
 SG_ WRSLNDWhlDisTpRC : 7|2@0+ (1,0) [0|3] "counts"  V2V_HS,CSM_HS,EOCM2B_K1_HS,HCP_B_HS,FCM_HS,HCP_T_HS,EOCM2A_K1_HS,FICM_HS,CGM_HS,HCP_HS,ICCM_B_HS,ICCM_OBD_HS,ICCM_HS,HMIM_HS,AHL_AFL_HS,BCP_HS,VES_HS,EPB_HS,EPS_HS,TCP_HS,ONSTAR_HS,RDCM_HS,ACC_HS,PTO_HS,BCM_HS,SADS_HS,TCM_HS,TCCM_HS,ECM_HS
 SG_ WRSLNDWhlRotStRst : 3|1@0+ (1,0) [0|1] ""  V2V_HS,CSM_HS,EOCM2B_K1_HS,HCP_B_HS,FCM_HS,HCP_T_HS,EOCM2A_K1_HS,FICM_HS,CGM_HS,HCP_HS,ICCM_B_HS,ICCM_OBD_HS,ICCM_HS,HMIM_HS,AHL_AFL_HS,BCP_HS,VES_HS,EPB_HS,EPS_HS,TCP_HS,ONSTAR_HS,RDCM_HS,ACC_HS,PTO_HS,BCM_HS,SADS_HS,TCM_HS,TCCM_HS,ECM_HS
 SG_ WRSLNDWhlDistVal : 2|1@0+ (1,0) [0|1] ""  V2V_HS,CSM_HS,EOCM2B_K1_HS,HCP_B_HS,FCM_HS,HCP_T_HS,EOCM2A_K1_HS,FICM_HS,CGM_HS,HCP_HS,ICCM_B_HS,ICCM_OBD_HS,ICCM_HS,HMIM_HS,AHL_AFL_HS,BCP_HS,VES_HS,EPB_HS,EPS_HS,TCP_HS,ONSTAR_HS,RDCM_HS,ACC_HS,PTO_HS,BCM_HS,SADS_HS,TCM_HS,TCCM_HS,ECM_HS
 SG_ WRSLNDWhlDistTstm : 23|16@0+ (1,0) [0|65535] "counts"  V2V_HS,CSM_HS,EOCM2B_K1_HS,HCP_B_HS,FCM_HS,HCP_T_HS,EOCM2A_K1_HS,FICM_HS,CGM_HS,HCP_HS,ICCM_B_HS,ICCM_OBD_HS,ICCM_HS,HMIM_HS,AHL_AFL_HS,BCP_HS,VES_HS,EPB_HS,EPS_HS,TCP_HS,ONSTAR_HS,RDCM_HS,ACC_HS,PTO_HS,BCM_HS,SADS_HS,TCM_HS,TCCM_HS,ECM_HS
 SG_ WRSLNDWhlDistPCntr : 1|10@0+ (1,0) [0|1023] "counts"  V2V_HS,CSM_HS,EOCM2B_K1_HS,HCP_B_HS,FCM_HS,HCP_T_HS,EOCM2A_K1_HS,FICM_HS,CGM_HS,HCP_HS,ICCM_B_HS,ICCM_OBD_HS,ICCM_HS,HMIM_HS,AHL_AFL_HS,BCP_HS,VES_HS,EPB_HS,EPS_HS,TCP_HS,ONSTAR_HS,RDCM_HS,ACC_HS,PTO_HS,BCM_HS,SADS_HS,TCM_HS,TCCM_HS,ECM_HS
 SG_ WRSLNDSeqNum : 5|2@0+ (1,0) [0|3] "counts"  V2V_HS,CSM_HS,EOCM2B_K1_HS,HCP_B_HS,FCM_HS,HCP_T_HS,EOCM2A_K1_HS,FICM_HS,CGM_HS,HCP_HS,ICCM_B_HS,ICCM_OBD_HS,ICCM_HS,HMIM_HS,AHL_AFL_HS,BCP_HS,VES_HS,EPB_HS,EPS_HS,TCP_HS,ONSTAR_HS,RDCM_HS,ACC_HS,PTO_HS,BCM_HS,SADS_HS,TCM_HS,TCCM_HS,ECM_HS
 SG_ WRSRNDWhlDisTpRC : 39|2@0+ (1,0) [0|3] "counts"  V2V_HS,CSM_HS,EOCM2B_K1_HS,HCP_B_HS,FCM_HS,HCP_T_HS,EOCM2A_K1_HS,FICM_HS,CGM_HS,HCP_HS,ICCM_B_HS,ICCM_OBD_HS,ICCM_HS,HMIM_HS,AHL_AFL_HS,BCP_HS,VES_HS,EPS_HS,TCP_HS,ONSTAR_HS,RDCM_HS,ACC_HS,PTO_HS,EPB_HS,SADS_HS,BCM_HS,TCM_HS,TCCM_HS,ECM_HS
 SG_ WRSRNDWhlRotStRst : 35|1@0+ (1,0) [0|1] ""  V2V_HS,CSM_HS,EOCM2B_K1_HS,HCP_B_HS,FCM_HS,HCP_T_HS,EOCM2A_K1_HS,FICM_HS,CGM_HS,HCP_HS,ICCM_B_HS,ICCM_OBD_HS,ICCM_HS,HMIM_HS,AHL_AFL_HS,BCP_HS,VES_HS,EPS_HS,TCP_HS,ONSTAR_HS,RDCM_HS,ACC_HS,PTO_HS,EPB_HS,SADS_HS,BCM_HS,TCM_HS,TCCM_HS,ECM_HS
 SG_ WRSRNDWhlDistVal : 34|1@0+ (1,0) [0|1] ""  V2V_HS,CSM_HS,EOCM2B_K1_HS,HCP_B_HS,FCM_HS,HCP_T_HS,EOCM2A_K1_HS,FICM_HS,CGM_HS,HCP_HS,ICCM_B_HS,ICCM_OBD_HS,ICCM_HS,HMIM_HS,AHL_AFL_HS,BCP_HS,VES_HS,EPS_HS,TCP_HS,ONSTAR_HS,RDCM_HS,ACC_HS,PTO_HS,EPB_HS,SADS_HS,BCM_HS,TCM_HS,TCCM_HS,ECM_HS
 SG_ WRSRNDWhlDistTstm : 55|16@0+ (1,0) [0|65535] "counts"  V2V_HS,CSM_HS,EOCM2B_K1_HS,HCP_B_HS,FCM_HS,HCP_T_HS,EOCM2A_K1_HS,FICM_HS,CGM_HS,HCP_HS,ICCM_B_HS,ICCM_OBD_HS,ICCM_HS,HMIM_HS,AHL_AFL_HS,BCP_HS,VES_HS,EPS_HS,TCP_HS,ONSTAR_HS,RDCM_HS,ACC_HS,PTO_HS,EPB_HS,SADS_HS,BCM_HS,TCM_HS,TCCM_HS,ECM_HS
 SG_ WRSRNDWhlDistPCntr : 33|10@0+ (1,0) [0|1023] "counts"  V2V_HS,CSM_HS,EOCM2B_K1_HS,HCP_B_HS,FCM_HS,HCP_T_HS,EOCM2A_K1_HS,FICM_HS,CGM_HS,HCP_HS,ICCM_B_HS,ICCM_OBD_HS,ICCM_HS,HMIM_HS,AHL_AFL_HS,BCP_HS,VES_HS,EPS_HS,TCP_HS,ONSTAR_HS,RDCM_HS,ACC_HS,PTO_HS,EPB_HS,SADS_HS,BCM_HS,TCM_HS,TCCM_HS,ECM_HS
 SG_ WRSRNDSeqNum : 37|2@0+ (1,0) [0|3] "counts"  V2V_HS,CSM_HS,EOCM2B_K1_HS,HCP_B_HS,FCM_HS,HCP_T_HS,EOCM2A_K1_HS,FICM_HS,CGM_HS,HCP_HS,ICCM_B_HS,ICCM_OBD_HS,ICCM_HS,HMIM_HS,AHL_AFL_HS,BCP_HS,VES_HS,EPS_HS,TCP_HS,ONSTAR_HS,RDCM_HS,ACC_HS,PTO_HS,EPB_HS,SADS_HS,BCM_HS,TCM_HS,TCCM_HS,ECM_HS

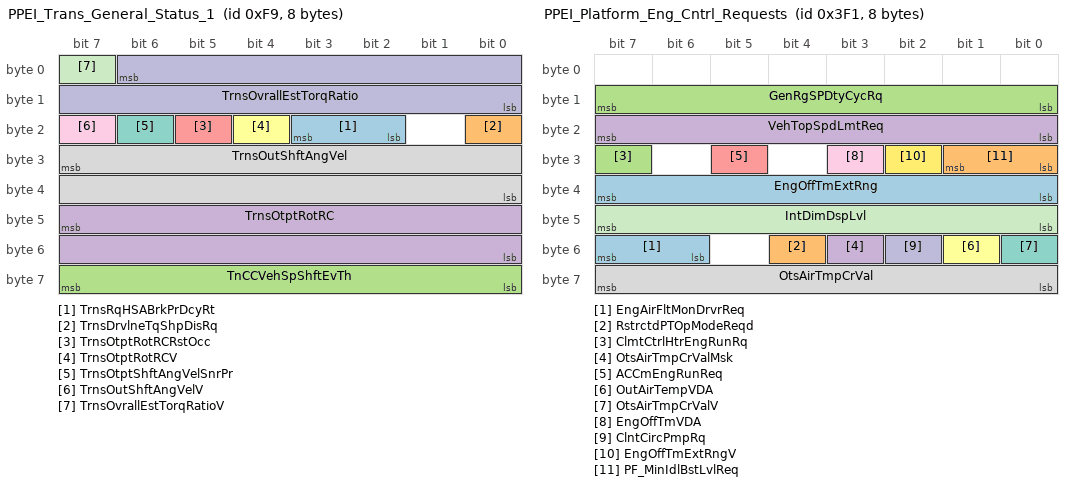
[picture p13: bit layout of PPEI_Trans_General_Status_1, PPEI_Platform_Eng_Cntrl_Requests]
BO_ 249 PPEI_Trans_General_Status_1: 8 ECM_HS
 SG_ TrnsRqHSABrkPrDcyRt : 19|2@0+ (1,0) [0|3] ""  CGM_HS,EBCM_OBD_HS,EBCM_HS
 SG_ TrnsDrvlneTqShpDisRq : 16|1@0+ (1,0) [0|1] ""  CGM_HS,HCP_B_HS,ECM_HS
 SG_ TnCCVehSpShftEvTh : 63|8@0+ (2,0) [0|510] "km / h"  CGM_HS,ECM_HS
 SG_ TrnsOtptRotRC : 47|16@0+ (0.0078125,0) [0|511.9921875] "rot"  CGM_HS,EBCM_OBD_HS,EBCM_HS,ECM_HS
 SG_ TrnsOtptRotRCRstOcc : 21|1@0+ (1,0) [0|1] ""  CGM_HS,EBCM_OBD_HS,EBCM_HS,ECM_HS
 SG_ TrnsOtptRotRCV : 20|1@0+ (1,0) [0|1] ""  CGM_HS,EBCM_OBD_HS,EBCM_HS,ECM_HS
 SG_ TrnsOtptShftAngVelSnrPr : 22|1@0+ (1,0) [0|1] ""  ICCM_HS,CGM_HS,TCCM_HS,ECM_HS
 SG_ TrnsOutShftAngVel : 31|16@0+ (0.25,0) [0|16383.75] "rpm"  ICCM_HS,CGM_HS,AMP_HS,EBCM_OBD_HS,EBCM_HS,TCCM_HS,ECM_HS
 SG_ TrnsOutShftAngVelV : 23|1@0+ (1,0) [0|1] ""  ICCM_HS,CGM_HS,AMP_HS,EBCM_OBD_HS,EBCM_HS,TCCM_HS,ECM_HS
 SG_ TrnsOvrallEstTorqRatio : 6|15@0- (0.00390625,0) [-64|63.99609375] ""  CGM_HS,TCCM_HS,SADS_HS,RDCM_HS,EBCM_OBD_HS,EBCM_HS,ECM_HS
 SG_ TrnsOvrallEstTorqRatioV : 7|1@0+ (1,0) [0|1] ""  CGM_HS,TCCM_HS,SADS_HS,RDCM_HS,EBCM_OBD_HS,EBCM_HS,ECM_HS

BO_ 1009 PPEI_Platform_Eng_Cntrl_Requests: 8 BCM_HS
 SG_ EngAirFltMonDrvrReq : 55|2@0+ (1,0) [0|3] ""  CGM_HS,ECM_HS
 SG_ RstrctdPTOpModeReqd : 52|1@0+ (1,0) [0|1] ""  CGM_HS,ECM_HS
 SG_ ClmtCtrlHtrEngRunRq : 31|1@0+ (1,0) [0|1] ""  CGM_HS,ECM_HS
 SG_ OtsAirTmpCrValMsk : 51|1@0+ (1,0) [0|1] ""  TCCM_HS,CGM_HS,ALC_HS,EPS_HS,ICCM_B_HS,ICCM_OBD_HS,ICCM_HS,RDCM_HS,ECM_HS,SADS_HS
 SG_ ACCmEngRunReq : 29|1@0+ (1,0) [0|1] ""  CGM_HS,HCP_B_HS,BSM_HS,ECM_HS,BCP_HS
 SG_ OutAirTempVDA : 49|1@0+ (1,0) [0|1] ""  TCM_HS,CGM_HS,SADS_HS,ICCM_B_HS,ICCM_OBD_HS,ICCM_HS,RDCM_HS,ECM_HS
 SG_ OtsAirTmpCrValV : 48|1@0+ (1,0) [0|1] ""  TCM_HS,TCCM_HS,CGM_HS,EBCM_OBD_HS,EBCM_HS,ALC_HS,EPS_HS,VCM_HS,ICCM_B_HS,ICCM_OBD_HS,ICCM_HS,RDCM_HS,SADS_HS,ECM_HS
 SG_ OtsAirTmpCrVal : 63|8@0+ (0.5,-40) [-40|87.5] "deg C"  TCM_HS,TCCM_HS,CGM_HS,EBCM_OBD_HS,EBCM_HS,ALC_HS,EPS_HS,VCM_HS,ICCM_B_HS,ICCM_OBD_HS,ICCM_HS,RDCM_HS,ECM_HS,SADS_HS
 SG_ EngOffTmVDA : 27|1@0+ (1,0) [0|1] ""  CGM_HS,EBCM_OBD_HS,EBCM_HS,ICCM_B_HS,ICCM_OBD_HS,ICCM_HS,ALC_HS,SADS_HS,VES_HS,EPS_HS,EPB_HS,TCCM_HS
 SG_ ClntCircPmpRq : 50|1@0+ (1,0) [0|1] ""  CGM_HS,BSM_HS,VICM_HS,ECM_HS
 SG_ IntDimDspLvl : 47|8@0+ (0.392157,0) [0|100.000035] "%"  ICCM_B_HS,EBCM_OBD_HS,EBCM_HS,CGM_HS,ECM_HS,ICCM_HS,FICM_HS,TCCM_HS
 SG_ EngOffTmExtRngV : 26|1@0+ (1,0) [0|1] ""  CGM_HS,ICCM_B_HS,ICCM_OBD_HS,ICCM_HS,ALC_HS,VES_HS,EPS_HS,EPB_HS,EBCM_OBD_HS,EBCM_HS,RDCM_HS,SADS_HS,TCCM_HS
 SG_ EngOffTmExtRng : 39|8@0+ (4,0) [0|1020] "min"  CGM_HS,ICCM_B_HS,ICCM_OBD_HS,ICCM_HS,ALC_HS,VES_HS,EPS_HS,EPB_HS,SADS_HS,EBCM_OBD_HS,EBCM_HS,RDCM_HS,TCCM_HS
 SG_ PF_MinIdlBstLvlReq : 25|2@0+ (1,0) [0|3] ""  CGM_HS,ECM_HS
 SG_ GenRgSPDtyCycRq : 15|8@0+ (0.392157,0) [0|100.000035] "%"  CGM_HS,ECM_HS
 SG_ VehTopSpdLmtReq : 23|8@0+ (2,0) [0|510] "km / h"  CGM_HS,PTO_HS,ECM_HS

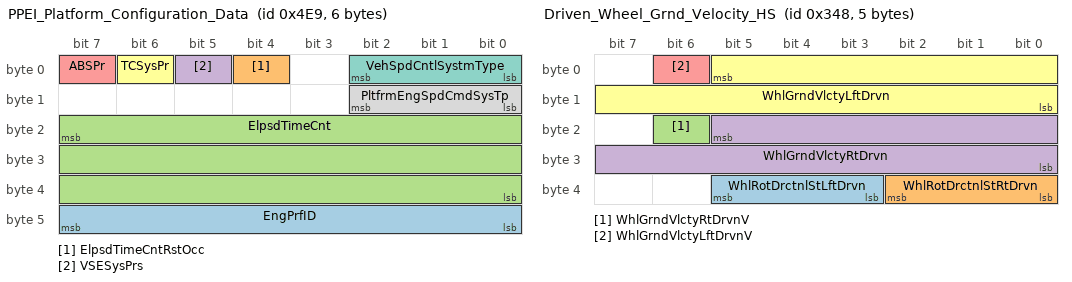
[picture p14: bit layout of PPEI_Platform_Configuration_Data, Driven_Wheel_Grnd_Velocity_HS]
BO_ 1257 PPEI_Platform_Configuration_Data: 6 BCM_HS
 SG_ EngPrfID : 47|8@0+ (2,0) [0|510] "kW"  CGM_HS,ECM_HS
 SG_ ElpsdTimeCntRstOcc : 4|1@0+ (1,0) [0|1] ""  CGM_HS,RDCM_HS
 SG_ ElpsdTimeCnt : 23|24@0+ (1,0) [0|16777200] "min"  CGM_HS,RDCM_HS,ECM_HS
 SG_ VSESysPrs : 5|1@0+ (1,0) [0|1] ""  CGM_HS,TCM_HS,TCCM_HS,ECM_HS
 SG_ ABSPr : 7|1@0+ (1,0) [0|1] ""  CGM_HS,HCP_B_HS,HCP_T_HS,TCM_HS,TCCM_HS,ECM_HS
 SG_ TCSysPr : 6|1@0+ (1,0) [0|1] ""  CGM_HS,TCM_HS,TCCM_HS,ECM_HS
 SG_ VehSpdCntlSystmType : 2|3@0+ (1,0) [0|7] ""  CGM_HS,ECM_HS
 SG_ PltfrmEngSpdCmdSysTp : 10|3@0+ (1,0) [0|7] ""  CGM_HS,PTO_HS,TCM_HS,ECM_HS

BO_ 505 PPEI_PTO_Command_Data: 8 PTO_HS
 SG_ AllNodesVNA_1F9 : 43|1@0+ (1,0) [0|1] ""  CGM_HS,BCM_HS
 SG_ PTOVehTopSpdLimVal : 63|8@0+ (2,0) [0|510] "km / h"  CGM_HS,BCM_HS
 SG_ AccPdlPwrTkOffOvrAct : 4|1@0+ (1,0) [0|1] ""  CGM_HS,ECM_HS
 SG_ PTOTGRReqdGear : 35|4@0+ (1,0) [0|15] ""  CGM_HS,TCM_HS
 SG_ PTOTGRReqType : 37|2@0+ (1,0) [0|3] ""  CGM_HS,TCM_HS
 SG_ PTORmtEngStrtReq : 44|1@0+ (1,0) [0|1] ""  CGM_HS,BCM_HS
 SG_ TrnsPTOCltchRelRqd : 38|1@0+ (1,0) [0|1] ""  CGM_HS,TCM_HS
 SG_ FstIdlMdAct : 47|1@0+ (1,0) [0|1] ""  BCM_HS,CGM_HS,ECM_HS
 SG_ PTOMdAct : 46|1@0+ (1,0) [0|1] ""  EOCM2B_K1_HS,EOCM2A_K1_HS,FCM_HS,CGM_HS,EBCM_OBD_HS,EBCM_HS,ECM_HS
 SG_ PTOEngTrqLmtRchd : 45|1@0+ (1,0) [0|1] ""  CGM_HS,ECM_HS
 SG_ PTOEngTrqLmtValER : 55|8@0+ (8,0) [0|2040] "Nm"  CGM_HS,ECM_HS
 SG_ PltfrmEngSpdCmdMdAct : 3|1@0+ (1,0) [0|1] ""  CGM_HS,ACC_HS,EBCM_OBD_HS,EBCM_HS,TCM_HS,ECM_HS
 SG_ PltfrmEngSpdReq : 2|11@0+ (4,0) [0|8188] "rpm"  CGM_HS,ACC_HS,EBCM_OBD_HS,EBCM_HS,TCM_HS,ECM_HS
 SG_ PFESpdCmdOnSwAct : 7|1@0+ (1,0) [0|1] ""  CGM_HS,ECM_HS
 SG_ PFESpdCmdDeSwAct : 5|1@0+ (1,0) [0|1] ""  CGM_HS,ECM_HS
 SG_ PFESpdCmdInSwAct : 6|1@0+ (1,0) [0|1] ""  CGM_HS,ECM_HS
 SG_ PFESpdCmdSwDIntg : 21|2@0+ (1,0) [0|3] ""  CGM_HS,ECM_HS
 SG_ PFEngSpdCmdAlvRlgCnt : 23|2@0+ (1,0) [0|3] ""  CGM_HS,TCM_HS,EBCM_OBD_HS,EBCM_HS,ECM_HS
 SG_ PltfrmEngSpdCmdProtVal : 19|12@0+ (1,0) [0|4095] ""  CGM_HS,EBCM_OBD_HS,EBCM_HS,ECM_HS
 SG_ PTORmtEngShtdwnReqd : 39|1@0+ (1,0) [0|1] ""  CGM_HS,BCM_HS,ECM_HS

BO_ 497 PPEI_Platform_General_Status: 8 BCM_HS
 SG_ ElvtdIdlCstStReq : 33|2@0+ (1,0) [0|3] ""  EOCM2B_IMX6_HS,EOCM2A_IMX6_HS,EOCM2B_K2_HS,EOCM2A_K2_HS,EOCM2B_K1_HS,CGM_HS,EOCM2A_K1_HS,ECM_HS
 SG_ FuelFltLfRstRqd : 56|1@0+ (1,0) [0|1] ""  EOCM2B_IMX6_HS,EOCM2A_IMX6_HS,EOCM2B_K2_HS,EOCM2A_K2_HS,EOCM2B_K1_HS,CGM_HS,EOCM2A_K1_HS,TCCM_HS,ECM_HS
 SG_ ACCompSysVDA : 9|1@0+ (1,0) [0|1] ""  EOCM2B_IMX6_HS,EOCM2A_IMX6_HS,EOCM2B_K2_HS,EOCM2A_K2_HS,EOCM2B_K1_HS,CGM_HS,HCP_HS,HCP_T_HS,EOCM2A_K1_HS,VCM_HS,BCP_HS,ECM_HS
 SG_ BkupPwrModeMstrVDA : 7|1@0+ (1,0) [0|1] ""  EOCM2B_IMX6_HS,EOCM2A_IMX6_HS,EOCM2B_K2_HS,EOCM2A_K2_HS,EOCM2B_K1_HS,CGM_HS,HCP_T_HS,HCP_HS,EOCM2A_K1_HS,HMIM_HS,APPS_HS,EBCM_OBD_HS,EBCM_HS,TCCM_HS,FICM_HS
 SG_ PrkBrkVDA : 35|1@0+ (1,0) [0|1] ""  EOCM2B_IMX6_HS,EOCM2A_IMX6_HS,EOCM2B_K2_HS,EOCM2A_K2_HS,EOCM2B_K1_HS,EOCM2A_K1_HS,CGM_HS,RDCM_HS,TCCM_HS
 SG_ PrkBrkVDM : 62|1@0+ (1,0) [0|1] ""  EOCM2B_IMX6_HS,EOCM2A_IMX6_HS,EOCM2B_K2_HS,EOCM2A_K2_HS,EOCM2B_K1_HS,EOCM2A_K1_HS,CGM_HS
 SG_ BkupPwrModeMstrVDM : 61|1@0+ (1,0) [0|1] ""  EOCM2B_IMX6_HS,EOCM2A_IMX6_HS,EOCM2B_K2_HS,EOCM2A_K2_HS,EOCM2B_K1_HS,CGM_HS,EOCM2A_K1_HS
 SG_ ACCompSysVDM : 60|1@0+ (1,0) [0|1] ""  EOCM2B_IMX6_HS,EOCM2A_IMX6_HS,EOCM2B_K2_HS,EOCM2A_K2_HS,EOCM2B_K1_HS,CGM_HS,EOCM2A_K1_HS,VCM_HS
 SG_ AirbgVDA : 57|1@0+ (1,0) [0|1] ""  EOCM2B_IMX6_HS,EOCM2A_IMX6_HS,EOCM2B_K2_HS,EOCM2A_K2_HS,FCM_HS,EOCM2B_K1_HS,HCP_B_HS,CGM_HS,HCP_T_HS,HCP_HS,EOCM2A_K1_HS,HMIM_HS,ECM_HS,ACC_HS,TCCM_HS,ICCM_B_HS,ICCM_OBD_HS,ICCM_HS,BCP_HS
 SG_ SysBkupPwrMdEn : 6|1@0+ (1,0) [0|1] ""  EOCM2B_IMX6_HS,EOCM2A_IMX6_HS,EOCM2B_K2_HS,EOCM2A_K2_HS,CGM_HS,TTPM_HS,AMM_HS,EBOOST_OBD_HS,HCP_B_HS,AVM_HS,PFAF_HS,DCDC_HS,VPM_HS,TCP_HS,EOCM2B_K1_HS,EOCM2A_K1_HS,TRCM_HS,ESCM_SP_HS,ICCM_B_HS,FICM_HS,ARS_HS,ICCM_OBD_HS,SAS_HS,VLBS_HS,HCP_T_HS,HCP_HS,ICCM_HS,EOCM_F_HS,VCM_HS,HMIM_HS,VES_HS,MCP_C_HS,EPS_HS,BCP_HS,ALC_HS,AHL_AFL_HS,SADS_HS,FCM_HS,TCCM_HS,RDCM_HS,PTO_HS,ACC_HS,TCM_HS,ECM_HS,EBCM_OBD_HS,APPS_HS,EPB_HS,EBCM_HS
 SG_ SysBkUpPwrMd : 5|2@0+ (1,0) [0|3] ""  EOCM2B_IMX6_HS,EOCM2A_IMX6_HS,EOCM2B_K2_HS,EOCM2A_K2_HS,CGM_HS,TTPM_HS,AMM_HS,EBOOST_OBD_HS,HCP_B_HS,AVM_HS,PFAF_HS,DCDC_HS,VPM_HS,TCP_HS,EOCM2B_K1_HS,EOCM2A_K1_HS,TRCM_HS,ESCM_SP_HS,ICCM_B_HS,FICM_HS,ARS_HS,ICCM_OBD_HS,SAS_HS,VLBS_HS,HCP_T_HS,HCP_HS,ICCM_HS,EOCM_F_HS,VCM_HS,HMIM_HS,VES_HS,MCP_C_HS,EPS_HS,BCP_HS,ALC_HS,AHL_AFL_HS,SADS_HS,FCM_HS,TCCM_HS,RDCM_HS,PTO_HS,ACC_HS,TCM_HS,ECM_HS,EBCM_OBD_HS,APPS_HS,EPB_HS,EBCM_HS
 SG_ SysPwrMd : 1|2@0+ (1,0) [0|3] ""  EOCM2B_IMX6_HS,EOCM2A_IMX6_HS,EOCM2B_K2_HS,EOCM2A_K2_HS,CGM_HS,BSM_HS,VICM_HS,TTPM_HS,AMM_HS,EBOOST_OBD_HS,HCP_B_HS,AVM_HS,PFAF_HS,DCDC_HS,VPM_HS,TCP_HS,EOCM2B_K1_HS,EOCM2A_K1_HS,TRCM_HS,ESCM_SP_HS,ICCM_B_HS,FICM_HS,ARS_HS,ICCM_OBD_HS,SAS_HS,VLBS_HS,HCP_T_HS,HCP_HS,ICCM_HS,EOCM_F_HS,VCM_HS,HMIM_HS,VES_HS,MCP_C_HS,EPS_HS,BCP_HS,ALC_HS,AHL_AFL_HS,SADS_HS,FCM_HS,TCCM_HS,RDCM_HS,PTO_HS,ACC_HS,TCM_HS,ECM_HS,EBCM_OBD_HS,APPS_HS,EPB_HS,EBCM_HS
 SG_ TrStLgMdAtv : 34|1@0+ (1,0) [0|1] ""  EOCM2B_IMX6_HS,EOCM2A_IMX6_HS,EOCM2B_K2_HS,EOCM2A_K2_HS,TTPM_HS,AMM_HS,EBOOST_OBD_HS,BSM_HS,HCP_B_HS,AVM_HS,PFAF_HS,DCDC_HS,VPM_HS,V2V_HS,TCP_HS,EOCM2B_K1_HS,EOCM2A_K1_HS,TRCM_HS,ESCM_SP_HS,ICCM_B_HS,MCP_B_HS,MCP_A_HS,ICCM_OBD_HS,SAS_HS,ACCM_HS,VLBS_HS,VITM_OBD_HS,VICM_HS,ICCM_HS,EOCM_F_HS,VCM_HS,HMIM_HS,VES_HS,MCP_C_HS,EPS_HS,MCP_HS,ALC_HS,AHL_AFL_HS,SADS_HS,EPB_HS,FCM_HS,TCCM_HS,RDCM_HS,PTO_HS,ACC_HS,TCM_HS,ECM_HS,CGM_HS,EBCM_OBD_HS,EBCM_HS
 SG_ DispMeasSys : 59|1@0+ (1,0) [0|1] ""  EOCM2B_IMX6_HS,EOCM2A_IMX6_HS,EOCM2B_K2_HS,EOCM2A_K2_HS,EBCM_OBD_HS,EBCM_HS,EOCM2B_K1_HS,CGM_HS,EOCM2A_K1_HS,TCCM_HS,ACC_HS,ECM_HS
 SG_ ACCmpsrFldOn : 63|1@0+ (1,0) [0|1] ""  EOCM2B_IMX6_HS,EOCM2A_IMX6_HS,EOCM2B_K2_HS,EOCM2A_K2_HS,EOCM2B_K1_HS,CGM_HS,EOCM2A_K1_HS,TCCM_HS,ECM_HS
 SG_ ACCompModReq : 12|2@0+ (1,0) [0|3] ""  EOCM2B_IMX6_HS,EOCM2A_IMX6_HS,EOCM2B_K2_HS,EOCM2A_K2_HS,EOCM2B_K1_HS,CGM_HS,HCP_T_HS,EOCM2A_K1_HS,HCP_HS,TCCM_HS,ECM_HS
 SG_ ACCompNormLd : 55|8@0+ (0.1,0) [0|25.5] "l/min"  EOCM2B_IMX6_HS,EOCM2A_IMX6_HS,EOCM2B_K2_HS,EOCM2A_K2_HS,EOCM2B_K1_HS,CGM_HS,EOCM2A_K1_HS,TCCM_HS,BCP_HS,ECM_HS
 SG_ ACCompNormLdV : 10|1@0+ (1,0) [0|1] ""  EOCM2B_IMX6_HS,EOCM2A_IMX6_HS,EOCM2B_K2_HS,EOCM2A_K2_HS,EOCM2B_K1_HS,CGM_HS,EOCM2A_K1_HS,TCCM_HS,BCP_HS,ECM_HS
 SG_ PTORSMstrEngShtReq : 13|1@0+ (1,0) [0|1] ""  EOCM2B_IMX6_HS,EOCM2A_IMX6_HS,EOCM2B_K2_HS,EOCM2A_K2_HS,EOCM2B_K1_HS,EOCM2A_K1_HS,CGM_HS,TCCM_HS,PTO_HS,ECM_HS
 SG_ EngOilLfRstRq : 37|1@0+ (1,0) [0|1] ""  EOCM2B_IMX6_HS,EOCM2A_IMX6_HS,EOCM2B_K2_HS,EOCM2A_K2_HS,EOCM2B_K1_HS,CGM_HS,EOCM2A_K1_HS,TCCM_HS,ECM_HS
 SG_ SIRDpl : 58|1@0+ (1,0) [0|1] ""  EOCM2B_IMX6_HS,EOCM2A_IMX6_HS,EOCM2B_K2_HS,EOCM2A_K2_HS,EOCM2B_K1_HS,EOCM2A_K1_HS,CGM_HS,HCP_T_HS,ICCM_B_HS,ICCM_OBD_HS,ICCM_HS,HCP_B_HS,HMIM_HS,HCP_HS,TCCM_HS,BCP_HS,ACC_HS,ECM_HS
 SG_ PTORmStMsEngStRq : 14|1@0+ (1,0) [0|1] ""  EOCM2B_IMX6_HS,EOCM2A_IMX6_HS,EOCM2B_K2_HS,EOCM2A_K2_HS,EOCM2B_K1_HS,EOCM2A_K1_HS,CGM_HS,PTO_HS,TCM_HS,TCCM_HS,ECM_HS
 SG_ RmVehStrRq : 15|1@0+ (1,0) [0|1] ""  EOCM2B_IMX6_HS,EOCM2A_IMX6_HS,EOCM2B_K2_HS,EOCM2A_K2_HS,EOCM2B_K1_HS,EOCM2A_K1_HS,CGM_HS,HCP_T_HS,BCP_HS,BSM_HS,VICM_HS,HCP_HS,APPS_HS,EPB_HS,TCCM_HS,ECM_HS
 SG_ ThrtlPrgrsnReq : 39|2@0+ (1,0) [0|3] ""  EOCM2B_IMX6_HS,EOCM2A_IMX6_HS,EOCM2B_K2_HS,EOCM2A_K2_HS,EOCM2B_K1_HS,EOCM2A_K1_HS,CGM_HS,TCCM_HS,ECM_HS
 SG_ PrkBrkSwAtv : 36|1@0+ (1,0) [0|1] ""  EOCM2B_IMX6_HS,EOCM2A_IMX6_HS,EOCM2B_K2_HS,EOCM2A_K2_HS,TCM_HS,FCM_HS,EOCM2B_K1_HS,EOCM2A_K1_HS,CGM_HS,PTO_HS,ICCM_B_HS,ICCM_OBD_HS,ICCM_HS,EOCM_F_HS,RDCM_HS,ACC_HS,EBCM_OBD_HS,EBCM_HS,TCCM_HS,ECM_HS
 SG_ PMMAccTrmSt : 2|1@0+ (1,0) [0|1] ""  EOCM2B_IMX6_HS,EOCM2A_IMX6_HS,EOCM2B_K2_HS,EOCM2A_K2_HS,EOCM2B_K1_HS,CGM_HS,EOCM2A_K1_HS,TCM_HS,TCCM_HS,ECM_HS
 SG_ PMMRunCrkTrmSt : 3|1@0+ (1,0) [0|1] ""  EOCM2B_IMX6_HS,EOCM2A_IMX6_HS,EOCM2B_K2_HS,EOCM2A_K2_HS,EOCM2B_K1_HS,EOCM2A_K1_HS,CGM_HS,TCM_HS,TCCM_HS,ECM_HS
 SG_ ImmblzrPreRelPswdStat : 8|1@0+ (1,0) [0|1] ""  EOCM2B_IMX6_HS,EOCM2A_IMX6_HS,EOCM2B_K2_HS,EOCM2A_K2_HS,EOCM2B_K1_HS,CGM_HS,EOCM2A_K1_HS,HCP_T_HS,HCP_HS,TCCM_HS,ECM_HS
 SG_ ImmblzrPreRelPswrd : 23|16@0+ (1,0) [0|65535] "passwrd"  EOCM2B_IMX6_HS,EOCM2A_IMX6_HS,EOCM2B_K2_HS,EOCM2A_K2_HS,EOCM2B_K1_HS,CGM_HS,EOCM2A_K1_HS,HCP_T_HS,HCP_HS,TCCM_HS,ECM_HS

BO_ 969 PPEI_Platform_Immobilizer_Data: 8 BCM_HS
 SG_ ImoInf : 7|64@0+ (1,0) [0|1.8446744074e+19] ""  CGM_HS,HCP_T_HS,HCP_HS,ECM_HS

BO_ 1249 PPEI_VIN_Digits_10_to_17: 8 BCM_HS
 SG_ VehIdNmDig10_17 : 7|64@0+ (1,0) [0|1] ""  EOCM2B_IMX6_HS,EOCM2A_IMX6_HS,V2V_HS,HCP_B_HS,CGM_HS,HCP_T_HS,EBCM_OBD_HS,EBCM_HS,VES_HS,EPS_HS,VLBS_HS,BCP_HS,ACC_HS,FICM_HS,EPB_HS,RDCM_HS,TCCM_HS,TCM_HS,ECM_HS

BO_ 2024 USDT_Resp_From_ECM_HS: 8 ECM_HS
 SG_ DgnInf : 7|64@0+ (1,0) [0|1.8446744074e+19] ""  HMIM_HS,CSM_HS,CGM_HS,TCP_HS,ONSTAR_HS,TestTool_HS

BO_ 1512 UUDT_Resp_From_ECM: 8 ECM_HS
 SG_ DgnInf : 7|64@0+ (1,0) [0|1.8446744074e+19] ""  HMIM_HS,CSM_HS,CGM_HS,TCP_HS,ONSTAR_HS,TestTool_HS

BO_ 840 Driven_Wheel_Grnd_Velocity_HS: 5 EBCM_HS
 SG_ WhlRotDrctnlStLftDrvn : 37|3@0+ (1,0) [0|7] ""  LVMPC_HS,V2V_HS,CSM_HS,EOCM2B_K1_HS,EOCM2A_K1_HS,CGM_HS,EDI_HS,EOCM_F_HS,HMIM_HS,EPS_HS
 SG_ WhlRotDrctnlStRtDrvn : 34|3@0+ (1,0) [0|7] ""  LVMPC_HS,V2V_HS,CSM_HS,EOCM2B_K1_HS,EOCM2A_K1_HS,CGM_HS,EDI_HS,EOCM_F_HS,HMIM_HS,EPS_HS
 SG_ WhlGrndVlctyRtDrvnV : 22|1@0+ (1,0) [0|1] ""  LVMPC_HS,V2V_HS,CSM_HS,EOCM2B_K1_HS,EOCM2A_K1_HS,CGM_HS,EDI_HS,HMIM_HS,TCCM_HS,FCM_HS,APPS_HS,EOCM_F_HS,EPB_HS,BCM_HS,RDCM_HS,ACC_HS,VES_HS,EPS_HS,SADS_HS
 SG_ WhlGrndVlctyRtDrvn : 21|14@0+ (0.03125,0) [0|511.96875] "km / h"  LVMPC_HS,V2V_HS,CSM_HS,EOCM2B_K1_HS,EOCM2A_K1_HS,CGM_HS,EDI_HS,HMIM_HS,TCCM_HS,FCM_HS,APPS_HS,EOCM_F_HS,BCM_HS,RDCM_HS,ACC_HS,EPB_HS,VES_HS,EPS_HS,SADS_HS
 SG_ WhlGrndVlctyLftDrvnV : 6|1@0+ (1,0) [0|1] ""  LVMPC_HS,V2V_HS,CSM_HS,EOCM2B_K1_HS,EOCM2A_K1_HS,CGM_HS,EDI_HS,HMIM_HS,TCCM_HS,FCM_HS,APPS_HS,EOCM_F_HS,EPB_HS,BCM_HS,RDCM_HS,ACC_HS,VES_HS,EPS_HS,SADS_HS
 SG_ WhlGrndVlctyLftDrvn : 5|14@0+ (0.03125,0) [0|511.96875] "km / h"  LVMPC_HS,V2V_HS,CSM_HS,EOCM2B_K1_HS,EOCM2A_K1_HS,CGM_HS,EDI_HS,HMIM_HS,TCCM_HS,FCM_HS,APPS_HS,EOCM_F_HS,BCM_HS,RDCM_HS,ACC_HS,EPB_HS,VES_HS,EPS_HS,SADS_HS

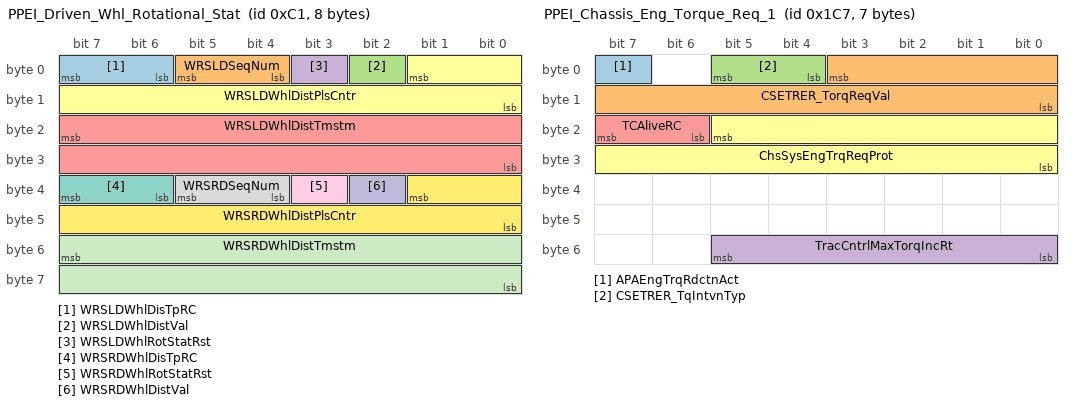
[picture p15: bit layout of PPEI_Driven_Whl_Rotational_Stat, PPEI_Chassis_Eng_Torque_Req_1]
BO_ 193 PPEI_Driven_Whl_Rotational_Stat: 8 EBCM_HS
 SG_ WRSLDWhlDisTpRC : 7|2@0+ (1,0) [0|3] "counts"  V2V_HS,CSM_HS,EOCM2B_K1_HS,HCP_B_HS,FCM_HS,HCP_T_HS,EOCM2A_K1_HS,FICM_HS,TRCM_HS,CGM_HS,HCP_HS,ICCM_B_HS,ICCM_OBD_HS,ICCM_HS,HMIM_HS,BCP_HS,VES_HS,EPB_HS,EPS_HS,TCP_HS,ONSTAR_HS,RDCM_HS,ACC_HS,PTO_HS,BCM_HS,SADS_HS,TCM_HS,TCCM_HS,ECM_HS
 SG_ WRSLDSeqNum : 5|2@0+ (1,0) [0|3] "counts"  V2V_HS,CSM_HS,EOCM2B_K1_HS,HCP_B_HS,FCM_HS,HCP_T_HS,EOCM2A_K1_HS,FICM_HS,TRCM_HS,CGM_HS,HCP_HS,ICCM_B_HS,ICCM_OBD_HS,ICCM_HS,HMIM_HS,BCP_HS,VES_HS,EPB_HS,EPS_HS,TCP_HS,ONSTAR_HS,RDCM_HS,ACC_HS,PTO_HS,BCM_HS,SADS_HS,TCM_HS,TCCM_HS,ECM_HS
 SG_ WRSLDWhlDistVal : 2|1@0+ (1,0) [0|1] ""  V2V_HS,CSM_HS,EOCM2B_K1_HS,HCP_B_HS,FCM_HS,HCP_T_HS,EOCM2A_K1_HS,FICM_HS,TRCM_HS,CGM_HS,HCP_HS,ICCM_B_HS,ICCM_OBD_HS,ICCM_HS,HMIM_HS,BCP_HS,VES_HS,EPB_HS,EPS_HS,TCP_HS,ONSTAR_HS,RDCM_HS,ACC_HS,PTO_HS,BCM_HS,SADS_HS,TCM_HS,TCCM_HS,ECM_HS
 SG_ WRSLDWhlRotStatRst : 3|1@0+ (1,0) [0|1] ""  V2V_HS,CSM_HS,EOCM2B_K1_HS,HCP_B_HS,FCM_HS,HCP_T_HS,EOCM2A_K1_HS,FICM_HS,TRCM_HS,CGM_HS,HCP_HS,ICCM_B_HS,ICCM_OBD_HS,ICCM_HS,HMIM_HS,BCP_HS,VES_HS,EPB_HS,EPS_HS,TCP_HS,ONSTAR_HS,RDCM_HS,ACC_HS,PTO_HS,BCM_HS,SADS_HS,TCM_HS,TCCM_HS,ECM_HS
 SG_ WRSLDWhlDistTmstm : 23|16@0+ (1,0) [0|65535] "counts"  V2V_HS,CSM_HS,EOCM2B_K1_HS,HCP_B_HS,FCM_HS,HCP_T_HS,EOCM2A_K1_HS,FICM_HS,TRCM_HS,CGM_HS,HCP_HS,ICCM_B_HS,ICCM_OBD_HS,ICCM_HS,HMIM_HS,BCP_HS,VES_HS,EPB_HS,EPS_HS,TCP_HS,ONSTAR_HS,RDCM_HS,ACC_HS,PTO_HS,BCM_HS,SADS_HS,TCM_HS,TCCM_HS,ECM_HS
 SG_ WRSLDWhlDistPlsCntr : 1|10@0+ (1,0) [0|1023] "counts"  V2V_HS,CSM_HS,EOCM2B_K1_HS,HCP_B_HS,FCM_HS,HCP_T_HS,EOCM2A_K1_HS,FICM_HS,TRCM_HS,CGM_HS,HCP_HS,ICCM_B_HS,ICCM_OBD_HS,ICCM_HS,HMIM_HS,BCP_HS,VES_HS,EPB_HS,EPS_HS,TCP_HS,ONSTAR_HS,RDCM_HS,ACC_HS,PTO_HS,BCM_HS,SADS_HS,TCM_HS,TCCM_HS,ECM_HS
 SG_ WRSRDWhlDisTpRC : 39|2@0+ (1,0) [0|3] "counts"  V2V_HS,CSM_HS,EOCM2B_K1_HS,HCP_B_HS,FCM_HS,HCP_T_HS,EOCM2A_K1_HS,FICM_HS,TRCM_HS,CGM_HS,HCP_HS,ICCM_B_HS,ICCM_OBD_HS,ICCM_HS,HMIM_HS,BCP_HS,VES_HS,EPS_HS,TCP_HS,ONSTAR_HS,RDCM_HS,ACC_HS,EPB_HS,PTO_HS,BCM_HS,SADS_HS,TCM_HS,TCCM_HS,ECM_HS
 SG_ WRSRDSeqNum : 37|2@0+ (1,0) [0|3] "counts"  V2V_HS,CSM_HS,EOCM2B_K1_HS,HCP_B_HS,FCM_HS,HCP_T_HS,EOCM2A_K1_HS,FICM_HS,TRCM_HS,CGM_HS,HCP_HS,ICCM_B_HS,ICCM_OBD_HS,ICCM_HS,HMIM_HS,BCP_HS,VES_HS,EPS_HS,TCP_HS,ONSTAR_HS,RDCM_HS,ACC_HS,EPB_HS,PTO_HS,BCM_HS,SADS_HS,TCM_HS,TCCM_HS,ECM_HS
 SG_ WRSRDWhlRotStatRst : 35|1@0+ (1,0) [0|1] ""  V2V_HS,CSM_HS,EOCM2B_K1_HS,HCP_B_HS,FCM_HS,HCP_T_HS,EOCM2A_K1_HS,FICM_HS,TRCM_HS,CGM_HS,HCP_HS,ICCM_B_HS,ICCM_OBD_HS,ICCM_HS,HMIM_HS,BCP_HS,VES_HS,EPS_HS,TCP_HS,ONSTAR_HS,RDCM_HS,ACC_HS,EPB_HS,PTO_HS,BCM_HS,SADS_HS,TCM_HS,TCCM_HS,ECM_HS
 SG_ WRSRDWhlDistVal : 34|1@0+ (1,0) [0|1] ""  V2V_HS,CSM_HS,EOCM2B_K1_HS,HCP_B_HS,FCM_HS,HCP_T_HS,EOCM2A_K1_HS,FICM_HS,TRCM_HS,CGM_HS,HCP_HS,ICCM_B_HS,ICCM_OBD_HS,ICCM_HS,HMIM_HS,BCP_HS,VES_HS,EPS_HS,TCP_HS,ONSTAR_HS,RDCM_HS,ACC_HS,EPB_HS,PTO_HS,BCM_HS,SADS_HS,TCM_HS,TCCM_HS,ECM_HS
 SG_ WRSRDWhlDistTmstm : 55|16@0+ (1,0) [0|65535] "counts"  V2V_HS,CSM_HS,EOCM2B_K1_HS,HCP_B_HS,FCM_HS,HCP_T_HS,EOCM2A_K1_HS,FICM_HS,TRCM_HS,CGM_HS,HCP_HS,ICCM_B_HS,ICCM_OBD_HS,ICCM_HS,HMIM_HS,BCP_HS,VES_HS,EPS_HS,TCP_HS,ONSTAR_HS,RDCM_HS,ACC_HS,EPB_HS,PTO_HS,BCM_HS,SADS_HS,TCM_HS,TCCM_HS,ECM_HS
 SG_ WRSRDWhlDistPlsCntr : 33|10@0+ (1,0) [0|1023] "counts"  V2V_HS,CSM_HS,EOCM2B_K1_HS,HCP_B_HS,FCM_HS,HCP_T_HS,EOCM2A_K1_HS,FICM_HS,TRCM_HS,CGM_HS,HCP_HS,ICCM_B_HS,ICCM_OBD_HS,ICCM_HS,HMIM_HS,BCP_HS,VES_HS,EPS_HS,TCP_HS,ONSTAR_HS,RDCM_HS,ACC_HS,EPB_HS,PTO_HS,BCM_HS,SADS_HS,TCM_HS,TCCM_HS,ECM_HS

BO_ 481 PPEI_Cruise_Control_Sw_Status: 7 BCM_HS
 SG_ CrsSecSwStatPVal : 51|4@0+ (1,0) [0|15] ""  EOCM2B_K2_HS,EOCM2A_K2_HS,FCM_HS,EOCM2B_K1_HS,CGM_HS,EOCM2A_K1_HS,ECM_HS,EOCM_F_HS,ACC_HS,PTO_HS
 SG_ CrsSecSwStatARC : 41|2@0+ (1,0) [0|3] ""  EOCM2B_K2_HS,EOCM2A_K2_HS,FCM_HS,EOCM2B_K1_HS,CGM_HS,EOCM2A_K1_HS,ECM_HS,EOCM_F_HS,ACC_HS,PTO_HS
 SG_ CrsSecSwStat : 27|4@0+ (1,0) [0|15] ""  EOCM2B_K2_HS,EOCM2A_K2_HS,FCM_HS,EOCM2B_K1_HS,CGM_HS,EOCM2A_K1_HS,ECM_HS,EOCM_F_HS,ACC_HS,PTO_HS
 SG_ DrvSelMdSw3Sta : 37|1@0+ (1,0) [0|1] ""  EOCM2B_K2_HS,EOCM2A_K2_HS,CSM_HS,HMIM_HS,EOCM2B_K1_HS,CGM_HS,EOCM2A_K1_HS,ECM_HS
 SG_ DrvSelMdSw2Sta : 38|1@0+ (1,0) [0|1] ""  EOCM2B_K2_HS,EOCM2A_K2_HS,CSM_HS,HMIM_HS,EOCM2B_K1_HS,CGM_HS,EOCM2A_K1_HS,ECM_HS
 SG_ AuxHtrRq : 31|1@0+ (1,0) [0|1] ""  EOCM2B_K2_HS,EOCM2A_K2_HS,EOCM2B_K1_HS,CGM_HS,EOCM2A_K1_HS,ECM_HS
 SG_ AuxHtrAtv : 30|1@0+ (1,0) [0|1] ""  EOCM2B_K2_HS,EOCM2A_K2_HS,EOCM2B_K1_HS,CGM_HS,EOCM2A_K1_HS,ECM_HS
 SG_ DrvSelMdSwStaARC : 33|2@0+ (1,0) [0|3] ""  EOCM2B_K2_HS,EOCM2A_K2_HS,CSM_HS,HMIM_HS,EOCM2B_K1_HS,CGM_HS,EOCM2A_K1_HS,ECM_HS
 SG_ DrvSelMdSw1Sta : 39|1@0+ (1,0) [0|1] ""  EOCM2B_K2_HS,EOCM2A_K2_HS,CSM_HS,HMIM_HS,EOCM2B_K1_HS,CGM_HS,EOCM2A_K1_HS,ECM_HS
 SG_ CrsSpdLmtrSwStatPVal : 55|4@0+ (1,0) [0|15] ""  EOCM2B_K2_HS,EOCM2A_K2_HS,EBCM_OBD_HS,EBCM_HS,FCM_HS,EOCM2B_K1_HS,HCP_B_HS,HCP_T_HS,HCP_HS,CGM_HS,EOCM2A_K1_HS,BCP_HS,PTO_HS,EOCM_F_HS,ECM_HS,ACC_HS
 SG_ CrsSpdLmtrSwStatARC : 43|2@0+ (1,0) [0|3] ""  EOCM2B_K2_HS,EOCM2A_K2_HS,EBCM_OBD_HS,EBCM_HS,FCM_HS,EOCM2B_K1_HS,HCP_B_HS,HCP_T_HS,HCP_HS,BCP_HS,CGM_HS,EOCM2A_K1_HS,PTO_HS,EOCM_F_HS,ECM_HS,ACC_HS
 SG_ FuelMdSwActV : 29|1@0+ (1,0) [0|1] ""  EOCM2B_K2_HS,EOCM2A_K2_HS,EOCM2B_K1_HS,CGM_HS,EOCM2A_K1_HS,FICM_HS,ECM_HS
 SG_ FuelMdSwAct : 28|1@0+ (1,0) [0|1] ""  EOCM2B_K2_HS,EOCM2A_K2_HS,EOCM2B_K1_HS,CGM_HS,EOCM2A_K1_HS,FICM_HS,ECM_HS
 SG_ CrsSpdLmtrSwStat : 47|4@0+ (1,0) [0|15] ""  EOCM2B_K2_HS,EOCM2A_K2_HS,EBCM_OBD_HS,EBCM_HS,FCM_HS,EOCM2B_K1_HS,HCP_B_HS,HCP_T_HS,HCP_HS,BCP_HS,CGM_HS,EOCM2A_K1_HS,PTO_HS,EOCM_F_HS,ECM_HS,ACC_HS
 SG_ AdptCrsGapSwAct : 23|2@0+ (1,0) [0|3] ""  EOCM2B_K2_HS,EOCM2A_K2_HS,FCM_HS,EOCM2B_K1_HS,CGM_HS,EOCM2A_K1_HS,EOCM_F_HS,ACC_HS
 SG_ CrsCntrlSwStCanSwAct : 7|1@0+ (1,0) [0|1] ""  EOCM2B_K2_HS,EOCM2A_K2_HS,EOCM2B_K1_HS,CGM_HS,EOCM2A_K1_HS,EOCM_F_HS,ACC_HS,ECM_HS
 SG_ CrsCntrlSwStSwDataIntgty : 1|2@0+ (1,0) [0|3] ""  EOCM2B_K2_HS,EOCM2A_K2_HS,EOCM2B_K1_HS,CGM_HS,EOCM2A_K1_HS,EOCM_F_HS,ACC_HS,ECM_HS
 SG_ CrsCntrlSwStSpdInSwAct : 3|1@0+ (1,0) [0|1] ""  EOCM2B_K2_HS,EOCM2A_K2_HS,EOCM2B_K1_HS,CGM_HS,EOCM2A_K1_HS,EOCM_F_HS,ACC_HS,ECM_HS
 SG_ CrsCntrlSwStSpDcSwAct : 2|1@0+ (1,0) [0|1] ""  EOCM2B_K2_HS,EOCM2A_K2_HS,EOCM2B_K1_HS,CGM_HS,EOCM2A_K1_HS,EOCM_F_HS,ACC_HS,ECM_HS
 SG_ CrsCntrlSwStSetSwAct : 4|1@0+ (1,0) [0|1] ""  EOCM2B_K2_HS,EOCM2A_K2_HS,EOCM2B_K1_HS,CGM_HS,EOCM2A_K1_HS,EOCM_F_HS,ACC_HS,ECM_HS
 SG_ CrsCntrlSwStResSwAct : 5|1@0+ (1,0) [0|1] ""  EOCM2B_K2_HS,EOCM2A_K2_HS,EOCM2B_K1_HS,CGM_HS,EOCM2A_K1_HS,EOCM_F_HS,ACC_HS,ECM_HS
 SG_ CrsCntrlSwStOnSwAct : 6|1@0+ (1,0) [0|1] ""  EOCM2B_K2_HS,EOCM2A_K2_HS,EOCM2B_K1_HS,CGM_HS,EOCM2A_K1_HS,EOCM_F_HS,ACC_HS,ECM_HS
 SG_ CrsCntrlSwStatProtValue : 15|8@0+ (1,0) [0|255] ""  EOCM2B_K2_HS,EOCM2A_K2_HS,EOCM2B_K1_HS,CGM_HS,EOCM2A_K1_HS,EOCM_F_HS,ACC_HS,ECM_HS
 SG_ CrsCntrlSwStAlvRollCnt : 17|2@0+ (1,0) [0|3] ""  EOCM2B_K2_HS,EOCM2A_K2_HS,EOCM2B_K1_HS,CGM_HS,EOCM2A_K1_HS,EOCM_F_HS,ACC_HS,ECM_HS
 SG_ CrsCntCncRq : 18|1@0+ (1,0) [0|1] ""  EOCM2B_K2_HS,EOCM2A_K2_HS,EOCM2B_K1_HS,CGM_HS,EOCM2A_K1_HS,ECM_HS

BO_ 455 PPEI_Chassis_Eng_Torque_Req_1: 7 EBCM_HS
 SG_ APAEngTrqRdctnAct : 7|1@0+ (1,0) [0|1] ""  CGM_HS,ECM_HS
 SG_ CSETRER_TorqReqVal : 3|12@0+ (0.5,-848) [-848|1199.5] "Nm"  EOCM2B_K2_HS,EOCM2A_K2_HS,FCM_HS,EOCM2B_K1_HS,CGM_HS,EOCM2A_K1_HS,ICCM_B_HS,ICCM_OBD_HS,ICCM_HS,EOCM_F_HS,ACC_HS,ECM_HS
 SG_ CSETRER_TqIntvnTyp : 5|2@0+ (1,0) [0|3] ""  EOCM2B_K2_HS,EOCM2A_K2_HS,FCM_HS,EOCM2B_K1_HS,CGM_HS,EOCM2A_K1_HS,ICCM_B_HS,ICCM_OBD_HS,ICCM_HS,EOCM_F_HS,ACC_HS,ECM_HS
 SG_ TracCntrlMaxTorqIncRt : 53|6@0+ (16,0) [0|1008] "Nm/s"  EOCM2B_K2_HS,EOCM2A_K2_HS,EOCM2B_K1_HS,CGM_HS,EOCM2A_K1_HS,ECM_HS
 SG_ TCAliveRC : 23|2@0+ (1,0) [0|3] ""  EOCM2B_K2_HS,EOCM2A_K2_HS,EOCM2B_K1_HS,CGM_HS,EOCM2A_K1_HS,ECM_HS
 SG_ ChsSysEngTrqReqProt : 21|14@0+ (1,0) [0|16383] ""  EOCM2B_K2_HS,EOCM2A_K2_HS,EOCM2B_K1_HS,CGM_HS,EOCM2A_K1_HS,ECM_HS

BO_ 761 PPEI_Chassis_General_Status_2: 7 EBCM_HS
 SG_ BrkSysHRBkCtrlAvail : 24|1@0+ (1,0) [0|1] ""  EOCM2B_K2_HS,EOCM2A_K2_HS,EOCM2B_K1_HS,CGM_HS,EOCM2A_K1_HS,TCM_HS
 SG_ BrkSysHRBkCtrlStat : 26|2@0+ (1,0) [0|3] ""  EOCM2B_K2_HS,EOCM2A_K2_HS,EOCM2B_K1_HS,CGM_HS,EOCM2A_K1_HS,TCM_HS
 SG_ BrkSysHSAAval : 27|1@0+ (1,0) [0|1] ""  EOCM2B_K2_HS,EOCM2A_K2_HS,EOCM2B_K1_HS,CGM_HS,EOCM2A_K1_HS,TCM_HS
 SG_ BrkSysHSAStat : 30|3@0+ (1,0) [0|7] ""  EOCM2B_K2_HS,EOCM2A_K2_HS,EOCM2B_K1_HS,CGM_HS,EOCM2A_K1_HS,TCM_HS
 SG_ HillDscntCtrlStatPVal : 17|2@0+ (1,0) [0|3] ""  EOCM2B_K2_HS,EOCM2A_K2_HS,ICCM_HS,EOCM2B_K1_HS,CGM_HS,EOCM2A_K1_HS,ECM_HS
 SG_ HillDscntCtrlStatARC : 19|2@0+ (1,0) [0|3] ""  EOCM2B_K2_HS,EOCM2A_K2_HS,ICCM_HS,EOCM2B_K1_HS,CGM_HS,EOCM2A_K1_HS,ECM_HS
 SG_ HillDscntCtrlStat : 21|2@0+ (1,0) [0|3] ""  EOCM2B_K2_HS,EOCM2A_K2_HS,ICCM_HS,EOCM2B_K1_HS,CGM_HS,EOCM2A_K1_HS,ECM_HS
 SG_ AutoBrkFeatInhbtPVal : 49|2@0+ (1,0) [0|3] ""  EOCM2B_K2_HS,EOCM2A_K2_HS,TCM_HS,EOCM2B_K1_HS,CGM_HS,EOCM2A_K1_HS,FCM_HS,ECM_HS
 SG_ AutoBrkFeatInhbtARC : 51|2@0+ (1,0) [0|3] ""  EOCM2B_K2_HS,EOCM2A_K2_HS,TCM_HS,EOCM2B_K1_HS,CGM_HS,EOCM2A_K1_HS,FCM_HS,ECM_HS
 SG_ ABFI_CollPrepSysInhbt : 52|1@0+ (1,0) [0|1] ""  EOCM2B_K2_HS,EOCM2A_K2_HS,TCM_HS,EOCM2B_K1_HS,CGM_HS,EOCM2A_K1_HS,FCM_HS,ECM_HS
 SG_ ABFI_RrVirtlBmprInh : 53|1@0+ (1,0) [0|1] ""  EOCM2B_K2_HS,EOCM2A_K2_HS,TCM_HS,EOCM2B_K1_HS,CGM_HS,EOCM2A_K1_HS,FCM_HS,ECM_HS
 SG_ ChsAVHStatPVal : 34|3@0+ (1,0) [0|7] ""  CGM_HS,ECM_HS
 SG_ ChsAVHStatARC : 36|2@0+ (1,0) [0|3] ""  CGM_HS,ECM_HS
 SG_ CAVHS_ACHActv : 37|1@0+ (1,0) [0|1] ""  CGM_HS,ECM_HS
 SG_ CAVHS_DSHEnbld : 38|1@0+ (1,0) [0|1] ""  CGM_HS,ECM_HS
 SG_ CAVHS_DSHActv : 39|1@0+ (1,0) [0|1] ""  CGM_HS,ECM_HS
 SG_ BrkPdlDrvApplPresV : 12|1@0+ (1,0) [0|1] ""  EOCM2B_K2_HS,EOCM2A_K2_HS,EOCM2B_K1_HS,CGM_HS,EOCM2A_K1_HS,ICCM_B_HS,ICCM_OBD_HS,ICCM_HS,BCP_HS,FCM_HS,ECM_HS,TCCM_HS,TCM_HS,VES_HS,EPS_HS
 SG_ BrkPdlDrvApplPres : 47|8@0+ (75,0) [0|19125] "kPa"  EOCM2B_K2_HS,EOCM2A_K2_HS,EOCM2B_K1_HS,HCP_B_HS,CGM_HS,EOCM2A_K1_HS,ICCM_B_HS,ICCM_OBD_HS,ICCM_HS,BCP_HS,FCM_HS,ECM_HS,TCCM_HS,TCM_HS,VES_HS,EPS_HS
 SG_ AutoBrkPTReqStat : 15|3@0+ (1,0) [0|7] ""  EOCM2B_K2_HS,EOCM2A_K2_HS,EOCM2B_K1_HS,CGM_HS,EOCM2A_K1_HS,FCM_HS,ECM_HS
 SG_ WhlSpdSnsgDTCIndex : 7|5@0+ (1,0) [0|31] ""  EOCM2B_K2_HS,EOCM2A_K2_HS,EOCM2B_K1_HS,CGM_HS,EOCM2A_K1_HS,ECM_HS
 SG_ WhlSpdSnsgDTCStat : 2|3@0+ (1,0) [0|7] ""  EOCM2B_K2_HS,EOCM2A_K2_HS,EOCM2B_K1_HS,CGM_HS,EOCM2A_K1_HS,ECM_HS
 SG_ SprTireSt : 10|3@0+ (1,0) [0|7] ""  EOCM2B_K2_HS,EOCM2A_K2_HS,EOCM2B_K1_HS,CGM_HS,EOCM2A_K1_HS,ICCM_B_HS,ICCM_OBD_HS,ICCM_HS,VES_HS,EPS_HS,BCM_HS,RDCM_HS,TCCM_HS

BO_ 489 PPEI_Chassis_General_Status_1: 8 EBCM_HS
 SG_ EnhDrvMdSwChUseRq : 53|1@0+ (1,0) [0|1] ""  EOCM2B_K2_HS,EOCM2A_K2_HS,EOCM2B_K1_HS,CGM_HS,EOCM2A_K1_HS,ECM_HS
 SG_ IMUDataMsk : 25|1@0+ (1,0) [0|1] ""  EOCM2B_K2_HS,EOCM2A_K2_HS,EOCM2B_K1_HS,CGM_HS,EOCM2A_K1_HS,TCP_HS,ONSTAR_HS
 SG_ DrvIndpntBrkAppAct : 55|1@0+ (1,0) [0|1] ""  EOCM2B_K2_HS,EOCM2A_K2_HS,EOCM2B_K1_HS,CGM_HS,EOCM2A_K1_HS,RDCM_HS,TCM_HS,ECM_HS
 SG_ WhlSlpSt : 52|2@0+ (1,0) [0|3] ""  EOCM2B_K2_HS,EOCM2A_K2_HS,VPM_HS,EOCM2B_K1_HS,HCP_HS,CGM_HS,HCP_T_HS,EOCM2A_K1_HS,ECM_HS,TCM_HS
 SG_ BSTGRReqdGear : 19|4@0+ (1,0) [0|15] ""  EOCM2B_K2_HS,EOCM2A_K2_HS,EOCM2B_K1_HS,CGM_HS,EOCM2A_K1_HS,TCM_HS
 SG_ BSTGRReqType : 21|2@0+ (1,0) [0|3] ""  EOCM2B_K2_HS,EOCM2A_K2_HS,EOCM2B_K1_HS,CGM_HS,EOCM2A_K1_HS,TCM_HS
 SG_ VehDynOvrUndrStr : 49|10@0- (0.5,0) [-256|255.5] "%"  EOCM2B_K2_HS,EOCM2A_K2_HS,EOCM2B_K1_HS,CGM_HS,EOCM2A_K1_HS,EPS_HS,RDCM_HS,TCCM_HS
 SG_ VSELatAccV : 4|1@0+ (1,0) [0|1] ""  EOCM2B_K2_HS,EOCM2A_K2_HS,EOCM2B_K1_HS,CGM_HS,EOCM2A_K1_HS,EDI_HS,FCM_HS,EPS_HS,ICCM_B_HS,ICCM_OBD_HS,ICCM_HS,ALC_HS,SADS_HS,RDCM_HS,BCM_HS,ACC_HS,EPB_HS,TCM_HS,TCCM_HS,ECM_HS
 SG_ VSELatAcc : 3|12@0- (0.015625,0) [-32|31.984375] "m/s^2"  EOCM2B_K2_HS,EOCM2A_K2_HS,EOCM2B_K1_HS,CGM_HS,EOCM2A_K1_HS,EDI_HS,FCM_HS,EPS_HS,ICCM_B_HS,ICCM_OBD_HS,ICCM_HS,ALC_HS,SADS_HS,BCM_HS,RDCM_HS,ACC_HS,EPB_HS,TCM_HS,TCCM_HS,ECM_HS
 SG_ VSEAct : 24|1@0+ (1,0) [0|1] ""  EOCM2B_K2_HS,EOCM2A_K2_HS,AHL_AFL_HS,V2V_HS,TCM_HS,EOCM2B_K1_HS,CGM_HS,EOCM2A_K1_HS,ICCM_B_HS,ICCM_OBD_HS,ICCM_HS,EOCM_F_HS,VES_HS,BCM_HS,EPB_HS,RDCM_HS,EPS_HS,ACC_HS,LVMPC_HS,TCCM_HS,ECM_HS
 SG_ VhDynCntlSysSt : 39|3@0+ (1,0) [0|7] ""  EOCM2B_K2_HS,EOCM2A_K2_HS,CSM_HS,EOCM2B_K1_HS,CGM_HS,EOCM_F_HS,FCM_HS,EOCM2A_K1_HS,HMIM_HS,RDCM_HS,VES_HS,ECM_HS,EPB_HS,EPS_HS,ACC_HS,TCCM_HS
 SG_ VehDynYawRateV : 36|1@0+ (1,0) [0|1] ""  EOCM2B_K2_HS,EOCM2A_K2_HS,LVMPC_HS,CSM_HS,EOCM2B_K1_HS,CGM_HS,VPM_HS,ICCM_B_HS,ICCM_OBD_HS,ICCM_HS,EOCM2A_K1_HS,EDI_HS,FCM_HS,HMIM_HS,RDCM_HS,BCM_HS,VES_HS,EPS_HS,TCP_HS,ONSTAR_HS,AHL_AFL_HS,ACC_HS,TCCM_HS
 SG_ VehDynYawRate : 35|12@0- (0.0625,0) [-128|127.9375] "deg/sec"  EOCM2B_K2_HS,EOCM2A_K2_HS,LVMPC_HS,CSM_HS,EOCM2B_K1_HS,VPM_HS,CGM_HS,ICCM_B_HS,ICCM_OBD_HS,ICCM_HS,EOCM2A_K1_HS,EDI_HS,FCM_HS,HMIM_HS,RDCM_HS,BCM_HS,VES_HS,EPS_HS,AHL_AFL_HS,TCP_HS,ONSTAR_HS,ACC_HS,TCCM_HS
 SG_ TrnsBrkSysCltchRelRqd : 5|1@0+ (1,0) [0|1] ""  EOCM2B_K2_HS,EOCM2A_K2_HS,EOCM2B_K1_HS,CGM_HS,EOCM2A_K1_HS,TCCM_HS,TCM_HS
 SG_ TracCntrlSysDrIntnt : 26|1@0+ (1,0) [0|1] ""  EOCM2B_K2_HS,EOCM2A_K2_HS,EOCM2B_K1_HS,CGM_HS,EOCM2A_K1_HS,EPS_HS,RDCM_HS,ECM_HS
 SG_ VehDynOvrUndrStrV : 50|1@0+ (1,0) [0|1] ""  EOCM2B_K2_HS,EOCM2A_K2_HS,EOCM2B_K1_HS,CGM_HS,EOCM2A_K1_HS,EPS_HS,RDCM_HS,TCCM_HS
 SG_ TCSysEnbld : 27|1@0+ (1,0) [0|1] ""  EOCM2B_K2_HS,EOCM2A_K2_HS,V2V_HS,EOCM2B_K1_HS,CGM_HS,EOCM2A_K1_HS,EOCM_F_HS,ACC_HS,BCP_HS,VES_HS,EPS_HS,RDCM_HS,TCM_HS,ECM_HS
 SG_ TCSysAtv : 28|1@0+ (1,0) [0|1] ""  EOCM2B_K2_HS,EOCM2A_K2_HS,V2V_HS,EOCM2B_K1_HS,CGM_HS,EOCM2A_K1_HS,LVMPC_HS,EDI_HS,PTO_HS,TCCM_HS,EOCM_F_HS,VES_HS,RDCM_HS,EPB_HS,EPS_HS,ACC_HS,BCM_HS,TCM_HS,ECM_HS
 SG_ BrkPdlDrvAppPrsDetcdV : 7|1@0+ (1,0) [0|1] ""  EOCM2B_K2_HS,EOCM2A_K2_HS,FCM_HS,EOCM2B_K1_HS,CGM_HS,EOCM2A_K1_HS,EOCM_F_HS,ACC_HS,VES_HS,EPS_HS,RDCM_HS,TCM_HS,TCCM_HS,ECM_HS
 SG_ BrkPdlDrvAppPrsDetcd : 6|1@0+ (1,0) [0|1] ""  EOCM2B_K2_HS,EOCM2A_K2_HS,FCM_HS,EOCM2B_K1_HS,CGM_HS,EOCM2A_K1_HS,EOCM_F_HS,ACC_HS,VES_HS,EPS_HS,RDCM_HS,TCM_HS,TCCM_HS,ECM_HS
 SG_ ACCBrkngAct : 31|1@0+ (1,0) [0|1] ""  EOCM2B_K2_HS,EOCM2A_K2_HS,V2V_HS,EOCM2B_K1_HS,CGM_HS,EOCM2A_K1_HS,EOCM_F_HS,ACC_HS,TCM_HS,ECM_HS
 SG_ ABSFld : 29|1@0+ (1,0) [0|1] ""  EOCM2B_K2_HS,EOCM2A_K2_HS,EOCM2B_K1_HS,V2V_HS,CGM_HS,FCM_HS,EOCM2A_K1_HS,EOCM_F_HS,ACC_HS,ICCM_B_HS,ICCM_OBD_HS,ICCM_HS,VES_HS,EPS_HS,EPB_HS,TCM_HS,ECM_HS
 SG_ ABSAtv : 30|1@0+ (1,0) [0|1] ""  EOCM2B_K2_HS,EOCM2A_K2_HS,AHL_AFL_HS,EOCM2B_K1_HS,V2V_HS,CGM_HS,EOCM2A_K1_HS,LVMPC_HS,EDI_HS,ICCM_B_HS,ICCM_OBD_HS,ICCM_HS,EOCM_F_HS,APPS_HS,SADS_HS,VES_HS,RDCM_HS,EPB_HS,EPS_HS,ACC_HS,BCM_HS,TCM_HS,TCCM_HS,ECM_HS

BO_ 381 Antilock_Brake_and_TC_Status_HS: 8 EBCM_HS
 SG_ BrkSysVTopSpdLimIO : 56|1@0+ (1,0) [0|1] ""  CGM_HS,BCM_HS
 SG_ ABSActIO : 57|1@0+ (1,0) [0|1] ""  BCM_HS,CGM_HS
 SG_ BrkSysStCrwlModeOvrrd : 59|2@0+ (1,0) [0|3] ""  CGM_HS,ECM_HS
 SG_ BrkPdLfStatIndRq : 62|3@0+ (1,0) [0|7] ""  CGM_HS,BCM_HS
 SG_ VehStbCmptvMdCstAvl : 48|1@0+ (1,0) [0|1] ""  BCM_HS,CGM_HS
 SG_ VehStbEnmntCstAvl : 49|1@0+ (1,0) [0|1] ""  BCM_HS,CGM_HS
 SG_ VehStbCmptvMdCurSt : 51|1@0+ (1,0) [0|1] ""  BCM_HS,CGM_HS
 SG_ VehStbEnhmntCurSt : 52|1@0+ (1,0) [0|1] ""  BCM_HS,CGM_HS
 SG_ TCSTempDsblReqIO : 63|1@0+ (1,0) [0|1] ""  BCM_HS,CGM_HS
 SG_ TCSysCstAvl : 50|1@0+ (1,0) [0|1] ""  BCM_HS,CGM_HS
 SG_ TCSysCurSt : 53|1@0+ (1,0) [0|1] ""  BCM_HS,CGM_HS
 SG_ TracAndStbScrnCnfg : 55|2@0+ (1,0) [0|3] ""  BCM_HS,CGM_HS
 SG_ HillDesCtrlRedVehSpIO : 39|1@0+ (1,0) [0|1] ""  EOCM2B_IMX6_HS,EOCM2A_IMX6_HS,EOCM2B_K1_HS,EOCM2A_K1_HS,CGM_HS,BCM_HS
 SG_ EBDFailed : 23|1@0+ (1,0) [0|1] ""  EOCM2B_IMX6_HS,EOCM2A_IMX6_HS,EOCM2B_K1_HS,EOCM2A_K1_HS,CGM_HS,BCM_HS
 SG_ StWhAnVDA : 17|1@0+ (1,0) [0|1] ""  EOCM2B_IMX6_HS,EOCM2A_IMX6_HS,CSM_HS,EOCM2B_K1_HS,EOCM2A_K1_HS,CGM_HS,HMIM_HS,RDCM_HS,TCP_HS,ONSTAR_HS,ACC_HS,AHL_AFL_HS,EPB_HS,BCM_HS
 SG_ TirePrsLowIO : 9|1@0+ (1,0) [0|1] ""  EOCM2B_IMX6_HS,EOCM2A_IMX6_HS,VPM_HS,EOCM2B_K1_HS,EOCM2A_K1_HS,CGM_HS,BCM_HS
 SG_ VaccBoostFailure : 16|1@0+ (1,0) [0|1] ""  EOCM2B_IMX6_HS,EOCM2A_IMX6_HS,EOCM2B_K1_HS,EOCM2A_K1_HS,CGM_HS,BCM_HS
 SG_ VSESysPrs : 1|1@0+ (1,0) [0|1] ""  EOCM2B_IMX6_HS,EOCM2A_IMX6_HS,V2V_HS,EOCM2B_K1_HS,EOCM2A_K1_HS,CGM_HS,EPB_HS,BCM_HS
 SG_ HalfSysFail : 18|1@0+ (1,0) [0|1] ""  EOCM2B_IMX6_HS,EOCM2A_IMX6_HS,EOCM2B_K1_HS,EOCM2A_K1_HS,CGM_HS,BCM_HS
 SG_ ActVehAccel : 35|12@0- (0.01,0) [-20.48|20.47] "m/s^2"  EOCM2B_IMX6_HS,EOCM2A_IMX6_HS,EOCM2B_K1_HS,EOCM2A_K1_HS,V2V_HS,CGM_HS,BSM_HS,VICM_HS,BCP_HS,BCM_HS,EOCM_F_HS,FCM_HS,ACC_HS,AHL_AFL_HS,EPB_HS
 SG_ ActVehAccelV : 20|1@0+ (1,0) [0|1] ""  EOCM2B_IMX6_HS,EOCM2A_IMX6_HS,EOCM2B_K1_HS,EOCM2A_K1_HS,V2V_HS,CGM_HS,BSM_HS,VICM_HS,BCP_HS,BCM_HS,EOCM_F_HS,FCM_HS,ACC_HS,AHL_AFL_HS,EPB_HS
 SG_ BksOvht : 8|1@0+ (1,0) [0|1] ""  EOCM2B_IMX6_HS,EOCM2A_IMX6_HS,FCM_HS,EOCM2B_K1_HS,EOCM2A_K1_HS,CGM_HS,EOCM_F_HS,BCM_HS,ACC_HS
 SG_ TCSysPr : 10|1@0+ (1,0) [0|1] ""  EOCM2B_IMX6_HS,EOCM2A_IMX6_HS,EOCM2B_K1_HS,EOCM2A_K1_HS,CGM_HS,EPB_HS,BCM_HS
 SG_ ABSPr : 22|1@0+ (1,0) [0|1] ""  EOCM2B_IMX6_HS,EOCM2A_IMX6_HS,EOCM2B_K1_HS,EOCM2A_K1_HS,CGM_HS,BCP_HS,APPS_HS,BCM_HS,EPB_HS
 SG_ TreInfMonSysRstPrfmd : 11|1@0+ (1,0) [0|1] ""  EOCM2B_IMX6_HS,EOCM2A_IMX6_HS,EOCM2B_K1_HS,EOCM2A_K1_HS,CGM_HS,BCM_HS
 SG_ ABSIO : 12|1@0+ (1,0) [0|1] ""  EOCM2B_IMX6_HS,EOCM2A_IMX6_HS,EOCM2B_K1_HS,EOCM2A_K1_HS,CGM_HS,FCM_HS,EOCM_F_HS,BCM_HS
 SG_ BrkPadWrnIO : 0|1@0+ (1,0) [0|1] ""  EOCM2B_IMX6_HS,EOCM2A_IMX6_HS,EOCM2B_K1_HS,EOCM2A_K1_HS,CGM_HS,BCM_HS
 SG_ VehStabEnhmntMd : 15|3@0+ (1,0) [0|7] ""  EOCM2B_IMX6_HS,EOCM2A_IMX6_HS,FCM_HS,V2V_HS,ECM_HS,EOCM2B_K1_HS,EOCM2A_K1_HS,CGM_HS,EDI_HS,ICCM_B_HS,ICCM_OBD_HS,ICCM_HS,SADS_HS,ACC_HS,EOCM_F_HS,TCCM_HS,RDCM_HS,BCM_HS
 SG_ VehStabEnhmntStat : 4|3@0+ (1,0) [0|7] ""  EOCM2B_IMX6_HS,EOCM2A_IMX6_HS,ECM_HS,EOCM2B_K1_HS,EOCM2A_K1_HS,V2V_HS,CGM_HS,EPS_HS,EDI_HS,FCM_HS,TCP_HS,ONSTAR_HS,ACC_HS,EOCM_F_HS,BCM_HS,EPB_HS
 SG_ TCSysOpMd : 7|3@0+ (1,0) [0|7] ""  EOCM2B_IMX6_HS,EOCM2A_IMX6_HS,V2V_HS,FCM_HS,ECM_HS,EOCM2B_K1_HS,EOCM2A_K1_HS,CGM_HS,EDI_HS,SADS_HS,EPS_HS,ACC_HS,EOCM_F_HS,TCCM_HS,RDCM_HS,BCM_HS
 SG_ TCSysOpStat : 38|3@0+ (1,0) [0|7] ""  EOCM2B_IMX6_HS,EOCM2A_IMX6_HS,FCM_HS,ECM_HS,EOCM2B_K1_HS,EOCM2A_K1_HS,CGM_HS,EDI_HS,SADS_HS,TCP_HS,ONSTAR_HS,ACC_HS,EOCM_F_HS,EPB_HS,BCM_HS
 SG_ BrkSysVTopSpdLimVal : 31|8@0+ (2,0) [0|510] "km / h"  ECM_HS,EOCM2B_IMX6_HS,EOCM2A_IMX6_HS,EOCM2B_K1_HS,EOCM2A_K1_HS,CGM_HS,BCM_HS
 SG_ BrkSysRedBrkTlltlReq : 19|1@0+ (1,0) [0|1] ""  EOCM2B_IMX6_HS,EOCM2A_IMX6_HS,EOCM2B_K1_HS,EOCM2A_K1_HS,CGM_HS,TCP_HS,ONSTAR_HS,BCM_HS
 SG_ BrkSysBrkLtsReqd : 21|1@0+ (1,0) [0|1] ""  EOCM2B_IMX6_HS,EOCM2A_IMX6_HS,EOCM2B_K1_HS,EOCM2A_K1_HS,CGM_HS,AHL_AFL_HS,BCM_HS

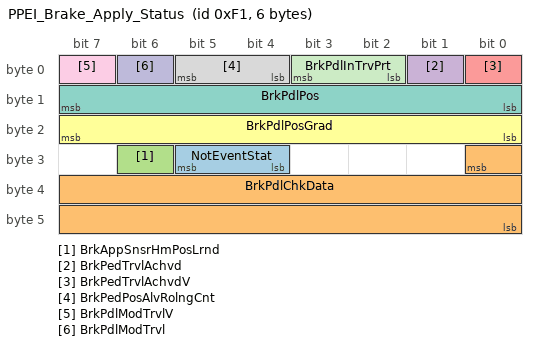
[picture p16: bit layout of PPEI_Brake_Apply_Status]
BO_ 241 PPEI_Brake_Apply_Status: 6 BCM_HS
 SG_ NotEventStat : 29|2@0+ (1,0) [0|3] ""  EOCM2B_K2_HS,EOCM2A_K2_HS,EOCM2B_K1_HS,CGM_HS,EOCM2A_K1_HS,EBCM_OBD_HS,EBCM_HS,ECM_HS,VES_HS,EPS_HS
 SG_ BrkPdlChkData : 24|17@0+ (1,0) [0|131071] ""  EOCM2B_K2_HS,EOCM2A_K2_HS,EOCM2B_K1_HS,FCM_HS,CGM_HS,EOCM2A_K1_HS,EOCM_F_HS,ACC_HS
 SG_ BrkAppSnsrHmPosLrnd : 30|1@0+ (1,0) [0|1] ""  EOCM2B_K2_HS,EOCM2A_K2_HS,V2V_HS,VPM_HS,EOCM2B_K1_HS,CGM_HS,EOCM2A_K1_HS,EOCM_F_HS,FCM_HS,ACC_HS,ECM_HS,VES_HS,EPS_HS,EBCM_OBD_HS,EBCM_HS
 SG_ BrkPedTrvlAchvd : 1|1@0+ (1,0) [0|1] ""  EOCM2B_K2_HS,EOCM2A_K2_HS,FCM_HS,EOCM2B_K1_HS,HCP_B_HS,CGM_HS,HCP_T_HS,EOCM2A_K1_HS,PTO_HS,BSM_HS,VICM_HS,BCP_HS,APPS_HS,VES_HS,EPS_HS,EOCM_F_HS,ICCM_B_HS,ICCM_OBD_HS,ICCM_HS,ALC_HS,EPB_HS,ACC_HS,RDCM_HS,SADS_HS,EBCM_OBD_HS,EBCM_HS,TCM_HS,TCCM_HS,ECM_HS
 SG_ BrkPedTrvlAchvdV : 0|1@0+ (1,0) [0|1] ""  EOCM2B_K2_HS,EOCM2A_K2_HS,FCM_HS,EOCM2B_K1_HS,HCP_B_HS,CGM_HS,HCP_T_HS,EOCM2A_K1_HS,PTO_HS,BSM_HS,VICM_HS,BCP_HS,APPS_HS,VES_HS,EPS_HS,EOCM_F_HS,ICCM_B_HS,ICCM_OBD_HS,ICCM_HS,ALC_HS,EPB_HS,ACC_HS,RDCM_HS,SADS_HS,EBCM_OBD_HS,EBCM_HS,TCM_HS,TCCM_HS,ECM_HS
 SG_ BrkPdlPosGrad : 23|8@0- (40,0) [-5120|5080] "%/s"  EOCM2B_K2_HS,EOCM2A_K2_HS,V2V_HS,EOCM2B_K1_HS,FCM_HS,CGM_HS,EOCM2A_K1_HS,ACC_HS,VES_HS,EPS_HS,EOCM_F_HS,SADS_HS,EBCM_OBD_HS,EBCM_HS
 SG_ BrkPdlPos : 15|8@0+ (0.392157,0) [0|100.000035] "% full"  EOCM2B_K2_HS,EOCM2A_K2_HS,TCP_HS,ONSTAR_HS,VPM_HS,EOCM2B_K1_HS,V2V_HS,FCM_HS,ECM_HS,CGM_HS,EOCM2A_K1_HS,LVMPC_HS,TCCM_HS,ACC_HS,EOCM_F_HS,TCM_HS,EDI_HS,SADS_HS,VES_HS,EPS_HS,EPB_HS,EBCM_OBD_HS,EBCM_HS
 SG_ BrkPedPosAlvRolngCnt : 5|2@0+ (1,0) [0|3] ""  EOCM2B_K2_HS,EOCM2A_K2_HS,V2V_HS,EOCM2B_K1_HS,FCM_HS,CGM_HS,EOCM2A_K1_HS,PTO_HS,TCCM_HS,RDCM_HS,VES_HS,EPS_HS,EOCM_F_HS,ICCM_B_HS,ICCM_OBD_HS,ICCM_HS,EPB_HS,ACC_HS,EBCM_OBD_HS,EBCM_HS,TCM_HS,ECM_HS
 SG_ BrkPdlModTrvlV : 7|1@0+ (1,0) [0|1] ""  EOCM2B_K2_HS,EOCM2A_K2_HS,VPM_HS,FCM_HS,EOCM2B_K1_HS,CGM_HS,EOCM2A_K1_HS,SADS_HS,EBCM_OBD_HS,EBCM_HS,ACC_HS,EOCM_F_HS,EPB_HS,TCCM_HS,VES_HS,EPS_HS,TCM_HS,ECM_HS
 SG_ BrkPdlModTrvl : 6|1@0+ (1,0) [0|1] ""  EOCM2B_K2_HS,EOCM2A_K2_HS,VPM_HS,FCM_HS,EOCM2B_K1_HS,CGM_HS,EOCM2A_K1_HS,EBCM_OBD_HS,EBCM_HS,SADS_HS,ACC_HS,EOCM_F_HS,EPB_HS,TCCM_HS,VES_HS,EPS_HS,TCM_HS,ECM_HS
 SG_ BrkPdlInTrvPrt : 3|2@0+ (1,0) [0|3] ""  EOCM2B_K2_HS,EOCM2A_K2_HS,FCM_HS,EOCM2B_K1_HS,CGM_HS,EOCM2A_K1_HS,PTO_HS,EOCM_F_HS,ICCM_B_HS,ICCM_OBD_HS,ICCM_HS,ALC_HS,RDCM_HS,ACC_HS,VES_HS,EPS_HS,SADS_HS,EBCM_OBD_HS,EBCM_HS,EPB_HS,TCM_HS,TCCM_HS,ECM_HS

BO_ 2025 USDT_Resp_From_BCP_HS: 8 BCP_HS
 SG_ DgnInf : 7|64@0+ (1,0) [0|1.8446744074e+19] ""  HMIM_HS,CSM_HS,CGM_HS,TCP_HS,ONSTAR_HS,TestTool_HS

BO_ 2029 USDT_Resp_From_OBD_Device5: 8 EBCM_OBD_HS
 SG_ DgnInf : 7|64@0+ (1,0) [0|1.8446744074e+19] ""  HMIM_HS,CSM_HS,CGM_HS,TCP_HS,ONSTAR_HS,TestTool_HS

BO_ 2031 USDT_Resp_From_VITM_HS: 8 VITM_OBD_HS
 SG_ DgnInf : 7|64@0+ (1,0) [0|1.8446744074e+19] ""  HMIM_HS,CSM_HS,CGM_HS,TCP_HS,ONSTAR_HS,TestTool_HS

BO_ 1513 UUDT_Resp_From_BCP_HS: 8 BCP_HS
 SG_ DgnInf : 7|64@0+ (1,0) [0|1.8446744074e+19] ""  HMIM_HS,CSM_HS,CGM_HS,TCP_HS,ONSTAR_HS,TestTool_HS

BO_ 1517 UUDT_Resp_From_OBD_Device5: 8 EBCM_OBD_HS
 SG_ DgnInf : 7|64@0+ (1,0) [0|1.8446744074e+19] ""  HMIM_HS,CSM_HS,CGM_HS,TCP_HS,ONSTAR_HS,TestTool_HS

BO_ 1519 UUDT_Resp_From_VITM_HS: 8 VITM_OBD_HS
 SG_ DgnInf : 7|64@0+ (1,0) [0|1.8446744074e+19] ""  HMIM_HS,CSM_HS,CGM_HS,TCP_HS,ONSTAR_HS,TestTool_HS

BO_ 2030 USDT_Resp_From_OBD_Device6: 8 GPCM_HS
 SG_ DgnInf : 7|64@0+ (1,0) [0|1.8446744074e+19] ""  HMIM_HS,CSM_HS,CGM_HS,TCP_HS,ONSTAR_HS,TestTool_HS

BO_ 1518 UUDT_Resp_From_OBD_Device6: 8 GPCM_HS
 SG_ DgnInf : 7|64@0+ (1,0) [0|1.8446744074e+19] ""  HMIM_HS,CSM_HS,CGM_HS,TCP_HS,ONSTAR_HS,TestTool_HS

BO_ 1346 UUDT_Resp_From_EHPS_EPS_HS: 8 EPS_HS
 SG_ DgnInf_HS542 : 7|64@0+ (1,0) [0|1.8446744074e+19] ""  HMIM_HS,CSM_HS,CGM_HS,TCP_HS,ONSTAR_HS,TestTool_HS

BO_ 1353 UUDT_Resp_From_AHL_AFL_HS: 8 CGM_HS
 SG_ DgnInf_HS549 : 7|64@0+ (1,0) [0|1.8446744074e+19] ""  HMIM_HS,CSM_HS,CGM_HS,TCP_HS,ONSTAR_HS,TestTool_HS

BO_ 1609 USDT_Resp_From_AHL_AFL_HS: 8 AHL_AFL_HS
 SG_ DgnInf : 7|64@0+ (1,0) [0|1.8446744074e+19] ""  HMIM_HS,CSM_HS,CGM_HS,TCP_HS,ONSTAR_HS,TestTool_HS

BO_ 1602 USDT_Resp_From_EHPS_EPS_HS: 8 EPS_HS
 SG_ DgnInf : 7|64@0+ (1,0) [0|1.8446744074e+19] ""  HMIM_HS,CSM_HS,CGM_HS,TCP_HS,ONSTAR_HS,TestTool_HS

BO_ 2027 USDT_Resp_From_ICCM_OBD_HS: 8 ICCM_HS
 SG_ DgnInf : 7|64@0+ (1,0) [0|1.8446744074e+19] ""  HMIM_HS,CSM_HS,CGM_HS,TCP_HS,ONSTAR_HS,TestTool_HS

BO_ 1515 UUDT_Resp_From_ICCM_OBD_HS: 8 ICCM_HS
 SG_ DgnInf : 7|64@0+ (1,0) [0|1.8446744074e+19] ""  HMIM_HS,CSM_HS,CGM_HS,TCP_HS,ONSTAR_HS,TestTool_HS

BO_ 1614 USDT_Resp_From_SADS_HS: 8 SADS_HS
 SG_ DgnInf : 7|64@0+ (1,0) [0|1.8446744074e+19] ""  HMIM_HS,CSM_HS,CGM_HS,TCP_HS,ONSTAR_HS,TestTool_HS

BO_ 1348 UUDT_Resp_From_OBCM_HS: 8 DCDC_HS
 SG_ DgnInf_HS544 : 7|64@0+ (1,0) [0|1.8446744074e+19] ""  HMIM_HS,CSM_HS,CGM_HS,TCP_HS,ONSTAR_HS,TestTool_HS

BO_ 1349 UUDT_Resp_From_ALC_HS: 8 ALC_HS
 SG_ DgnInf_HS545 : 7|64@0+ (1,0) [0|1.8446744074e+19] ""  HMIM_HS,CSM_HS,CGM_HS,TCP_HS,ONSTAR_HS,TestTool_HS

BO_ 1352 UUDT_Resp_From_Free_48_HS: 8 Dummy_HS
 SG_ DgnInf_HS548 : 7|64@0+ (1,0) [0|1.8446744074e+19] ""  HMIM_HS,CSM_HS,CGM_HS,TCP_HS,ONSTAR_HS,TestTool_HS

BO_ 1354 UUDT_Resp_From_SAS_HS: 8 SAS_HS
 SG_ DgnInf_HS54A : 7|64@0+ (1,0) [0|1.8446744074e+19] ""  HMIM_HS,CSM_HS,CGM_HS,TCP_HS,ONSTAR_HS,TestTool_HS

BO_ 1605 USDT_Resp_From_ALC_HS: 8 ALC_HS
 SG_ DgnInf : 7|64@0+ (1,0) [0|1.8446744074e+19] ""  HMIM_HS,CSM_HS,CGM_HS,TCP_HS,ONSTAR_HS,TestTool_HS

BO_ 1620 USDT_Resp_From_EPB_HS: 8 EPB_HS
 SG_ DgnInf : 7|64@0+ (1,0) [0|1.8446744074e+19] ""  HMIM_HS,CSM_HS,CGM_HS,TCP_HS,ONSTAR_HS,TestTool_HS

BO_ 1604 USDT_Resp_From_OBCM_HS: 8 DCDC_HS
 SG_ DgnInf : 7|64@0+ (1,0) [0|1.8446744074e+19] ""  HMIM_HS,CSM_HS,CGM_HS,TCP_HS,ONSTAR_HS,TestTool_HS

BO_ 1612 USDT_Resp_From_PFAF_HS: 8 EOCM2B_K1_HS
 SG_ DgnInf : 7|64@0+ (1,0) [0|1.8446744074e+19] ""  HMIM_HS,CSM_HS,CGM_HS,TCP_HS,ONSTAR_HS,TestTool_HS

BO_ 1615 USDT_Resp_From_RDCM_HS: 8 RDCM_HS
 SG_ DgnInf : 7|64@0+ (1,0) [0|1.8446744074e+19] ""  HMIM_HS,CSM_HS,CGM_HS,TCP_HS,ONSTAR_HS,TestTool_HS

CM_ SG_ 801 WBRP_RtFrt "Negative values indicate Compression, Positive values indicate Extension.";
CM_ SG_ 801 WBRP_RtRr "Negative values indicate Compression, Positive values indicate Extension.";
CM_ SG_ 801 WBRP_LftRr "Negative values indicate Compression, Positive values indicate Extension.";
CM_ SG_ 801 WBRP_LftFrt "Negative values indicate Compression, Positive values indicate Extension.";
CM_ SG_ 320 MainLghtSw "Operator selection for the main lighting switch";
CM_ SG_ 320 AutLghtCtrl "This signal represents if Automatic Lights Control feature is active/inactive";
CM_ SG_ 1904 DTCI_DTCSource_770 "This shall be equal to the Diagnostic Address of the transmittting device.";
CM_ SG_ 1904 DTCI_DTCFaultType_770 "Based on Powertrain definition.  Not expected to be supported by all devices.";
CM_ SG_ 1904 DTCI_DTCFailType_770 "Assigned per GMW3110, Appendix E";
CM_ SG_ 1908 DTCI_DTCFaultType_774 "Based on Powertrain definition.  Not expected to be supported by all devices.";
CM_ SG_ 1908 DTCI_DTCFailType_774 "Assigned per GMW3110, Appendix E";
CM_ SG_ 1908 DTCI_DTCSource_774 "This shall be equal to the Diagnostic Address of the transmittting device.";
CM_ SG_ 1909 DTCI_DTCFaultType_775 "Based on Powertrain definition.  Not expected to be supported by all devices.";
CM_ SG_ 1909 DTCI_DTCFailType_775 "Assigned per GMW3110, Appendix E";
CM_ SG_ 1909 DTCI_DTCSource_775 "This shall be equal to the Diagnostic Address of the transmittting device.";
CM_ SG_ 1910 DTCI_DTCFaultType_776 "Based on Powertrain definition.  Not expected to be supported by all devices.";
CM_ SG_ 1910 DTCI_DTCFailType_776 "Assigned per GMW3110, Appendix E";
CM_ SG_ 1910 DTCI_DTCSource_776 "This shall be equal to the Diagnostic Address of the transmittting device.";
CM_ SG_ 1912 DTCI_DTCFaultType_778 "Based on Powertrain definition.  Not expected to be supported by all devices.";
CM_ SG_ 1912 DTCI_DTCFailType_778 "Assigned per GMW3110, Appendix E";
CM_ SG_ 1912 DTCI_DTCSource_778 "This shall be equal to the Diagnostic Address of the transmittting device.";
CM_ SG_ 1913 DTCI_DTCFaultType_779 "Based on Powertrain definition.  Not expected to be supported by all devices.";
CM_ SG_ 1913 DTCI_DTCFailType_779 "Assigned per GMW3110, Appendix E";
CM_ SG_ 1913 DTCI_DTCSource_779 "This shall be equal to the Diagnostic Address of the transmittting device.";
CM_ SG_ 1916 DTCI_DTCFaultType_77C "Based on Powertrain definition.  Not expected to be supported by all devices.";
CM_ SG_ 1916 DTCI_DTCFailType_77C "Assigned per GMW3110, Appendix E";
CM_ SG_ 1916 DTCI_DTCSource_77C "This shall be equal to the Diagnostic Address of the transmittting device.";
CM_ SG_ 1917 DTCI_DTCFaultType_77D "Based on Powertrain definition.  Not expected to be supported by all devices.";
CM_ SG_ 1917 DTCI_DTCFailType_77D "Assigned per GMW3110, Appendix E";
CM_ SG_ 1917 DTCI_DTCSource_77D "This shall be equal to the Diagnostic Address of the transmittting device.";
CM_ SG_ 1918 DTCI_DTCFaultType_77E "Based on Powertrain definition.  Not expected to be supported by all devices.";
CM_ SG_ 1918 DTCI_DTCFailType_77E "Assigned per GMW3110, Appendix E";
CM_ SG_ 1918 DTCI_DTCSource_77E "This shall be equal to the Diagnostic Address of the transmittting device.";
CM_ SG_ 1919 DTCI_DTCFaultType_77F "Based on Powertrain definition.  Not expected to be supported by all devices.";
CM_ SG_ 1919 DTCI_DTCFailType_77F "Assigned per GMW3110, Appendix E";
CM_ SG_ 1919 DTCI_DTCSource_77F "This shall be equal to the Diagnostic Address of the transmittting device.";
CM_ SG_ 499 PFTrnsTUDSecSwSt "Added 2006 Nov 10 according to CR1112";
CM_ BO_ 1282 "ALC will not (and cannot) be present on vehicles where the ICCM will transmit HS $502. Currently, this is only envisioned for high-performance vehicles.";
CM_ SG_ 1921 DTCI_DTCSource_781 "This shall be equal to the Diagnostic Address of the transmittting device.";
CM_ SG_ 1921 DTCI_DTCFaultType_781 "Based on Powertrain definition.  Not expected to be supported by all devices.";
CM_ SG_ 1921 DTCI_DTCFailType_781 "Assigned per GMW3110, Appendix E";
CM_ SG_ 1920 DTCI_DTCSource_780 "This shall be equal to the Diagnostic Address of the transmittting device.";
CM_ SG_ 1920 DTCI_DTCFaultType_780 "Based on Powertrain definition.  Not expected to be supported by all devices.";
CM_ SG_ 1920 DTCI_DTCFailType_780 "Assigned per GMW3110, Appendix E";
CM_ SG_ 1914 DTCI_DTCFaultType_77A "Based on Powertrain definition.  Not expected to be supported by all devices.";
CM_ SG_ 1914 DTCI_DTCFailType_77A "Assigned per GMW3110, Appendix E";
CM_ SG_ 1914 DTCI_DTCSource_77A "This shall be equal to the Diagnostic Address of the transmittting device.";
CM_ SG_ 1911 DTCI_DTCFaultType_777 "Based on Powertrain definition.  Not expected to be supported by all devices.";
CM_ SG_ 1911 DTCI_DTCFailType_777 "Assigned per GMW3110, Appendix E";
CM_ SG_ 1911 DTCI_DTCSource_777 "This shall be equal to the Diagnostic Address of the transmittting device.";
CM_ SG_ 1906 DTCI_DTCFaultType_772 "Based on Powertrain definition.  Not expected to be supported by all devices.";
CM_ SG_ 1906 DTCI_DTCFailType_772 "Assigned per GMW3110, Appendix E";
CM_ SG_ 1906 DTCI_DTCSource_772 "This shall be equal to the Diagnostic Address of the transmittting device.";
CM_ SG_ 1907 DTCI_DTCFaultType_773 "Based on Powertrain definition.  Not expected to be supported by all devices.";
CM_ SG_ 1907 DTCI_DTCFailType_773 "Assigned per GMW3110, Appendix E";
CM_ SG_ 1907 DTCI_DTCSource_773 "This shall be equal to the Diagnostic Address of the transmittting device.";
CM_ SG_ 1915 DTCI_DTCFaultType_77B "Based on Powertrain definition.  Not expected to be supported by all devices.";
CM_ SG_ 1915 DTCI_DTCFailType_77B "Assigned per GMW3110, Appendix E";
CM_ SG_ 1915 DTCI_DTCSource_77B "This shall be equal to the Diagnostic Address of the transmittting device.";
CM_ BO_ 880 "Note that the stand-alone radar ACC and EBCM algorithm will transmit this message at a 50 ms periodic rate and the EOCM and FCM algorithm will transmit this message at a 40 ms periodic rate";
CM_ SG_ 880 ACCHdwyStg "Headway is the  time which results from dividing the following distance (or gap) between vehicles by the vehicle speed.  This setting allows the driver to choose a Headway Setting without actually knowing the value of this time.";
CM_ SG_ 298 DrId "Driver 8 changed to Unknown on 3/30/99";
CM_ SG_ 1300 VehIdNmDig2_9 "Desc: 8 ASCII Characters";
CM_ BO_ 485 "6443-Power Steering Indication On in this frame not used by GlobalA /JD";
CM_ BO_ 491 "Changed for PPEI 3.6 - Should be gated from FSCM
";
CM_ SG_ 401 EngTrqTnsRqFld "Indicates that the Engine controller will not honor the torque request from the Transmission Controller due to a failure in the Rolling count, protection value, etc.";
CM_ SG_ 401 EngNTrnsRegStdyStTqV "ETEI 3.1";
CM_ SG_ 401 EngNTrnsRegStdyStTq "ETEI 3.1";
CM_ SG_ 401 EngAirflwStdyStTorqV "ETEI 3.1";
CM_ SG_ 401 EngAirflwStdyStTorq "ETEI 3.1";
CM_ SG_ 401 EngActStdyStTorqV "ETEI 3.1";
CM_ SG_ 401 EngActStdyStTorq "ETEI 3.1";
CM_ SG_ 417 DslPrtFltrIdlRgtnMdReq "Diesel signal could be shared with a Gasoline application";
CM_ SG_ 417 DslPartFltrClngAlgActM "Diesel signal could be shared with a Gasoline application";
CM_ SG_ 417 DslPartFltrClngAlgAct "Diesel signal could be shared with a Gasoline application";
CM_ SG_ 417 TracCntlSysPwrtrnInhbt "ETEI 3.1";
CM_ SG_ 977 ACCmpNrmLdGrdAld "dm3/m/s = dm3/minute/second";
CM_ BO_ 201 "Changed for PPEI 3.6";
CM_ SG_ 201 EngRunAtv "Indication from powertrain that the engine is running (Has RPM > 0)";
CM_ SG_ 501 TrnShftPtrnActStat "(PT = Powertrain)";
CM_ SG_ 409 TDslPrtFltrIdlRgtnMdAtv "Diesel signal could be shared with a Gasoline application";
CM_ SG_ 1249 VehIdNmDig10_17 "Desc: 8 ASCII Characters";
CM_ SG_ 481 AuxHtrRq "Auxiliary Heater shall be used to denote a heater function that uses some kind of power, electrical or mechanical,  that was generated by the engine.";
CM_ SG_ 481 AuxHtrAtv "Auxiliary Heater shall be used to denote a heater function that uses some kind of power, electrical or mechanical,  that was generated by the engine.";
CM_ BO_ 489 "Changed for PPEI 3.6";
CM_ SG_ 241 BrkPdlModTrvlV "Indicates that the brake pedal position has passed a threshold for brake torque management and some 2 channel Vehicle Dynamics Control systems.";
CM_ SG_ 241 BrkPdlModTrvl "Indicates that the brake pedal position has passed a threshold for brake torque management and some 2 channel Vehicle Dynamics Control systems.";
BA_DEF_ SG_  "VNSigSLHSSharedDiagnostic" ENUM  "No","Yes","DLCLS","DLCHS","DLCCE","DLCFO";
BA_DEF_ SG_  "SignalType" STRING ;
BA_DEF_ SG_  "PacketOrder" INT 0 65535;
BA_DEF_ SG_  "SignalLongName" STRING ;
BA_DEF_ SG_  "GenSigStartValue" INT 0 65535;
BA_DEF_ SG_  "VNSigAllNodes" ENUM  "No","Yes","DLCLS","DLCHS","DLCCE","DLCFO";
BA_DEF_ SG_  "GenSigSendType" ENUM  "not used","not used","not used","not used","not used","not used","not used","NoSigSendType","not used","not used","OnAnyChange","OnChangeIfActive","OnDelta","DLCLS","DLCHS","DLCCE","DLCFO";
BA_DEF_ SG_  "GenSigSendOnInit" ENUM  "Not Initialized","Application","Handler","DLCLS","DLCHS","DLCCE","DLCFO";
BA_DEF_ BO_  "AppGenMsgCycleTime" INT 0 0;
BA_DEF_ BO_  "GenMsgILSupport" ENUM  "No","Yes","DLCLS","DLCHS","DLCCE","DLCFO";
BA_DEF_ BO_  "TpApplType" STRING ;
BA_DEF_ BO_  "Prio" INT 0 7;
BA_DEF_ BO_  "MessageSubnet" ENUM  "LS","MS","HS","CE","PE","HV","FO","S1","HE","LE","HE2","DLCLS","DLCHS","DLCCE","DLCFO";
BA_DEF_ BO_  "DiagState" ENUM  "No","Yes","DLCLS","DLCHS","DLCCE","DLCFO";
BA_DEF_ BO_  "GenMsgStartDelayTime" INT 0 100000;
BA_DEF_ BO_  "GenMsgDelayTime" INT 0 100000;
BA_DEF_ BO_  "GenMsgCycleTime" INT 0 100000;
BA_DEF_ BO_  "GenMsgSendType" ENUM  "cyclicX","spontanX","cyclicIfActiveX","spontanWithDelay","cyclicAndSpontanX","cyclicAndSpontanWithDelay","spontanWithRepitition","cyclicIfActiveAndSpontanWD","DLCLS","DLCHS","DLCCE","DLCFO";
BA_DEF_ BO_  "DiagResponse" ENUM  "No","Yes","DLCLS","DLCHS","DLCCE","DLCFO";
BA_DEF_ BO_  "DiagRequest" ENUM  "No","Yes","DLCLS","DLCHS","DLCCE","DLCFO";
BA_DEF_ BO_  "NmMessage" ENUM  "No","Yes","DLCLS","DLCHS","DLCCE","DLCFO";
BA_DEF_DEF_  "VNSigSLHSSharedDiagnostic" "No";
BA_DEF_DEF_  "SignalType" "";
BA_DEF_DEF_  "PacketOrder" 0;
BA_DEF_DEF_  "SignalLongName" "";
BA_DEF_DEF_  "GenSigStartValue" 0;
BA_DEF_DEF_  "VNSigAllNodes" "No";
BA_DEF_DEF_  "GenSigSendType" "NoSigSendType";
BA_DEF_DEF_  "GenSigSendOnInit" "Not Initialized";
BA_DEF_DEF_  "AppGenMsgCycleTime" 0;
BA_DEF_DEF_  "GenMsgILSupport" "Yes";
BA_DEF_DEF_  "TpApplType" "";
BA_DEF_DEF_  "Prio" 4;
BA_DEF_DEF_  "MessageSubnet" "FO";
BA_DEF_DEF_  "DiagState" "No";
BA_DEF_DEF_  "GenMsgStartDelayTime" 0;
BA_DEF_DEF_  "GenMsgDelayTime" 0;
BA_DEF_DEF_  "GenMsgCycleTime" 0;
BA_DEF_DEF_  "GenMsgSendType" "spontanX";
BA_DEF_DEF_  "DiagResponse" "No";
BA_DEF_DEF_  "DiagRequest" "No";
BA_DEF_DEF_  "NmMessage" "No";
BA_ "GenMsgSendType" BO_ 560 0;
BA_ "GenMsgCycleTime" BO_ 560 50;
BA_ "MessageSubnet" BO_ 560 2;
BA_ "Prio" BO_ 560 0;
BA_ "GenMsgSendType" BO_ 451 0;
BA_ "GenMsgCycleTime" BO_ 451 25;
BA_ "MessageSubnet" BO_ 451 2;
BA_ "Prio" BO_ 451 0;
BA_ "GenMsgSendType" BO_ 801 0;
BA_ "GenMsgCycleTime" BO_ 801 25;
BA_ "MessageSubnet" BO_ 801 2;
BA_ "Prio" BO_ 801 0;
BA_ "GenMsgSendType" BO_ 320 0;
BA_ "GenMsgCycleTime" BO_ 320 1000;
BA_ "GenMsgDelayTime" BO_ 320 10;
BA_ "GenMsgStartDelayTime" BO_ 320 30;
BA_ "MessageSubnet" BO_ 320 2;
BA_ "Prio" BO_ 320 0;
BA_ "GenMsgSendType" BO_ 957 0;
BA_ "GenMsgCycleTime" BO_ 957 100;
BA_ "MessageSubnet" BO_ 957 2;
BA_ "Prio" BO_ 957 0;
BA_ "MessageSubnet" BO_ 1364 2;
BA_ "Prio" BO_ 1364 0;
BA_ "TpApplType" BO_ 1364 "DiagUUDTResponse";
BA_ "GenMsgILSupport" BO_ 1364 0;
BA_ "MessageSubnet" BO_ 2041 2;
BA_ "Prio" BO_ 2041 0;
BA_ "GenMsgSendType" BO_ 1904 0;
BA_ "GenMsgCycleTime" BO_ 1904 1000;
BA_ "MessageSubnet" BO_ 1904 2;
BA_ "Prio" BO_ 1904 6;
BA_ "GenMsgSendType" BO_ 1908 0;
BA_ "GenMsgCycleTime" BO_ 1908 1000;
BA_ "MessageSubnet" BO_ 1908 2;
BA_ "Prio" BO_ 1908 6;
BA_ "GenMsgSendType" BO_ 1909 0;
BA_ "GenMsgCycleTime" BO_ 1909 1000;
BA_ "MessageSubnet" BO_ 1909 2;
BA_ "Prio" BO_ 1909 6;
BA_ "GenMsgSendType" BO_ 1910 0;
BA_ "GenMsgCycleTime" BO_ 1910 1000;
BA_ "MessageSubnet" BO_ 1910 2;
BA_ "Prio" BO_ 1910 6;
BA_ "GenMsgSendType" BO_ 1912 0;
BA_ "GenMsgCycleTime" BO_ 1912 1000;
BA_ "MessageSubnet" BO_ 1912 2;
BA_ "Prio" BO_ 1912 6;
BA_ "GenMsgSendType" BO_ 1913 0;
BA_ "GenMsgCycleTime" BO_ 1913 1000;
BA_ "MessageSubnet" BO_ 1913 2;
BA_ "Prio" BO_ 1913 6;
BA_ "GenMsgSendType" BO_ 1916 0;
BA_ "GenMsgCycleTime" BO_ 1916 1000;
BA_ "MessageSubnet" BO_ 1916 2;
BA_ "Prio" BO_ 1916 6;
BA_ "GenMsgSendType" BO_ 1917 0;
BA_ "GenMsgCycleTime" BO_ 1917 1000;
BA_ "MessageSubnet" BO_ 1917 2;
BA_ "Prio" BO_ 1917 6;
BA_ "GenMsgSendType" BO_ 1918 0;
BA_ "GenMsgCycleTime" BO_ 1918 1000;
BA_ "MessageSubnet" BO_ 1918 2;
BA_ "Prio" BO_ 1918 6;
BA_ "GenMsgSendType" BO_ 1919 0;
BA_ "GenMsgCycleTime" BO_ 1919 1000;
BA_ "MessageSubnet" BO_ 1919 2;
BA_ "Prio" BO_ 1919 6;
BA_ "DiagRequest" BO_ 589 1;
BA_ "MessageSubnet" BO_ 589 2;
BA_ "Prio" BO_ 589 0;
BA_ "MessageSubnet" BO_ 1357 2;
BA_ "Prio" BO_ 1357 0;
BA_ "TpApplType" BO_ 1357 "DiagUUDTResponse";
BA_ "GenMsgILSupport" BO_ 1357 0;
BA_ "DiagResponse" BO_ 1613 1;
BA_ "MessageSubnet" BO_ 1613 2;
BA_ "Prio" BO_ 1613 0;
BA_ "DiagResponse" BO_ 1606 1;
BA_ "MessageSubnet" BO_ 1606 2;
BA_ "Prio" BO_ 1606 0;
BA_ "DiagRequest" BO_ 582 1;
BA_ "MessageSubnet" BO_ 582 2;
BA_ "Prio" BO_ 582 0;
BA_ "DiagRequest" BO_ 590 1;
BA_ "MessageSubnet" BO_ 590 2;
BA_ "Prio" BO_ 590 0;
BA_ "DiagRequest" BO_ 601 1;
BA_ "MessageSubnet" BO_ 601 2;
BA_ "Prio" BO_ 601 0;
BA_ "MessageSubnet" BO_ 1369 2;
BA_ "Prio" BO_ 1369 0;
BA_ "TpApplType" BO_ 1369 "DiagUUDTResponse";
BA_ "GenMsgILSupport" BO_ 1369 0;
BA_ "DiagResponse" BO_ 1625 1;
BA_ "MessageSubnet" BO_ 1625 2;
BA_ "Prio" BO_ 1625 0;
BA_ "MessageSubnet" BO_ 1356 2;
BA_ "Prio" BO_ 1356 0;
BA_ "TpApplType" BO_ 1356 "DiagUUDTResponse";
BA_ "GenMsgILSupport" BO_ 1356 0;
BA_ "MessageSubnet" BO_ 1358 2;
BA_ "Prio" BO_ 1358 0;
BA_ "TpApplType" BO_ 1358 "DiagUUDTResponse";
BA_ "GenMsgILSupport" BO_ 1358 0;
BA_ "MessageSubnet" BO_ 1359 2;
BA_ "Prio" BO_ 1359 0;
BA_ "TpApplType" BO_ 1359 "DiagUUDTResponse";
BA_ "GenMsgILSupport" BO_ 1359 0;
BA_ "DiagRequest" BO_ 2023 1;
BA_ "MessageSubnet" BO_ 2023 2;
BA_ "Prio" BO_ 2023 0;
BA_ "DiagRequest" BO_ 2021 1;
BA_ "MessageSubnet" BO_ 2021 2;
BA_ "Prio" BO_ 2021 0;
BA_ "DiagRequest" BO_ 2017 1;
BA_ "MessageSubnet" BO_ 2017 2;
BA_ "Prio" BO_ 2017 0;
BA_ "DiagRequest" BO_ 2019 1;
BA_ "MessageSubnet" BO_ 2019 2;
BA_ "Prio" BO_ 2019 0;
BA_ "DiagRequest" BO_ 585 1;
BA_ "MessageSubnet" BO_ 585 2;
BA_ "Prio" BO_ 585 0;
BA_ "DiagRequest" BO_ 578 1;
BA_ "MessageSubnet" BO_ 578 2;
BA_ "Prio" BO_ 578 0;
BA_ "DiagRequest" BO_ 2022 1;
BA_ "MessageSubnet" BO_ 2022 2;
BA_ "Prio" BO_ 2022 0;
BA_ "DiagRequest" BO_ 584 1;
BA_ "MessageSubnet" BO_ 584 2;
BA_ "Prio" BO_ 584 0;
BA_ "DiagRequest" BO_ 591 1;
BA_ "MessageSubnet" BO_ 591 2;
BA_ "Prio" BO_ 591 0;
BA_ "DiagRequest" BO_ 581 1;
BA_ "MessageSubnet" BO_ 581 2;
BA_ "Prio" BO_ 581 0;
BA_ "DiagRequest" BO_ 586 1;
BA_ "MessageSubnet" BO_ 586 2;
BA_ "Prio" BO_ 586 0;
BA_ "DiagRequest" BO_ 588 1;
BA_ "MessageSubnet" BO_ 588 2;
BA_ "Prio" BO_ 588 0;
BA_ "GenMsgILSupport" BO_ 588 0;
BA_ "DiagRequest" BO_ 580 1;
BA_ "MessageSubnet" BO_ 580 2;
BA_ "Prio" BO_ 580 0;
BA_ "GenMsgSendType" BO_ 499 0;
BA_ "GenMsgCycleTime" BO_ 499 30;
BA_ "GenMsgStartDelayTime" BO_ 499 20;
BA_ "MessageSubnet" BO_ 499 2;
BA_ "Prio" BO_ 499 0;
BA_ "GenMsgSendType" BO_ 1282 0;
BA_ "GenMsgCycleTime" BO_ 1282 500;
BA_ "MessageSubnet" BO_ 1282 2;
BA_ "Prio" BO_ 1282 0;
BA_ "MessageSubnet" BO_ 1360 2;
BA_ "Prio" BO_ 1360 0;
BA_ "TpApplType" BO_ 1360 "DiagUUDTResponse";
BA_ "GenMsgILSupport" BO_ 1360 0;
BA_ "DiagResponse" BO_ 1616 1;
BA_ "MessageSubnet" BO_ 1616 2;
BA_ "Prio" BO_ 1616 0;
BA_ "GenMsgSendType" BO_ 1921 0;
BA_ "GenMsgCycleTime" BO_ 1921 1000;
BA_ "MessageSubnet" BO_ 1921 2;
BA_ "Prio" BO_ 1921 0;
BA_ "GenMsgSendType" BO_ 1920 0;
BA_ "GenMsgCycleTime" BO_ 1920 1000;
BA_ "MessageSubnet" BO_ 1920 2;
BA_ "Prio" BO_ 1920 0;
BA_ "DiagRequest" BO_ 596 1;
BA_ "MessageSubnet" BO_ 596 2;
BA_ "Prio" BO_ 596 0;
BA_ "MessageSubnet" BO_ 2033 2;
BA_ "Prio" BO_ 2033 0;
BA_ "GenMsgSendType" BO_ 495 0;
BA_ "GenMsgCycleTime" BO_ 495 12;
BA_ "MessageSubnet" BO_ 495 2;
BA_ "Prio" BO_ 495 0;
BA_ "MessageSubnet" BO_ 1350 2;
BA_ "Prio" BO_ 1350 0;
BA_ "TpApplType" BO_ 1350 "DiagUUDTResponse";
BA_ "GenMsgILSupport" BO_ 1350 0;
BA_ "GenMsgSendType" BO_ 1914 0;
BA_ "GenMsgCycleTime" BO_ 1914 1000;
BA_ "MessageSubnet" BO_ 1914 2;
BA_ "Prio" BO_ 1914 6;
BA_ "GenMsgSendType" BO_ 1911 0;
BA_ "GenMsgCycleTime" BO_ 1911 1000;
BA_ "MessageSubnet" BO_ 1911 2;
BA_ "Prio" BO_ 1911 6;
BA_ "DiagRequest" BO_ 583 1;
BA_ "MessageSubnet" BO_ 583 2;
BA_ "Prio" BO_ 583 0;
BA_ "MessageSubnet" BO_ 1351 2;
BA_ "Prio" BO_ 1351 0;
BA_ "TpApplType" BO_ 1351 "DiagUUDTResponse";
BA_ "GenMsgILSupport" BO_ 1351 0;
BA_ "DiagResponse" BO_ 1607 1;
BA_ "MessageSubnet" BO_ 1607 2;
BA_ "Prio" BO_ 1607 0;
BA_ "GenMsgSendType" BO_ 1906 0;
BA_ "GenMsgCycleTime" BO_ 1906 1000;
BA_ "MessageSubnet" BO_ 1906 2;
BA_ "Prio" BO_ 1906 6;
BA_ "GenMsgSendType" BO_ 1907 0;
BA_ "GenMsgCycleTime" BO_ 1907 1000;
BA_ "MessageSubnet" BO_ 1907 2;
BA_ "Prio" BO_ 1907 6;
BA_ "DiagRequest" BO_ 579 1;
BA_ "MessageSubnet" BO_ 579 2;
BA_ "Prio" BO_ 579 0;
BA_ "DiagResponse" BO_ 1603 1;
BA_ "MessageSubnet" BO_ 1603 2;
BA_ "Prio" BO_ 1603 0;
BA_ "MessageSubnet" BO_ 1347 2;
BA_ "Prio" BO_ 1347 0;
BA_ "TpApplType" BO_ 1347 "DiagUUDTResponse";
BA_ "GenMsgILSupport" BO_ 1347 0;
BA_ "GenMsgSendType" BO_ 1915 0;
BA_ "GenMsgCycleTime" BO_ 1915 1000;
BA_ "MessageSubnet" BO_ 1915 2;
BA_ "Prio" BO_ 1915 6;
BA_ "DiagRequest" BO_ 587 1;
BA_ "MessageSubnet" BO_ 587 2;
BA_ "Prio" BO_ 587 0;
BA_ "GenMsgILSupport" BO_ 587 0;
BA_ "DiagResponse" BO_ 1611 1;
BA_ "MessageSubnet" BO_ 1611 2;
BA_ "Prio" BO_ 1611 0;
BA_ "GenMsgILSupport" BO_ 1611 0;
BA_ "MessageSubnet" BO_ 1355 2;
BA_ "Prio" BO_ 1355 0;
BA_ "TpApplType" BO_ 1355 "DiagUUDTResponse";
BA_ "GenMsgILSupport" BO_ 1355 0;
BA_ "MessageSubnet" BO_ 880 2;
BA_ "Prio" BO_ 880 0;
BA_ "AppGenMsgCycleTime" BO_ 880 40;
BA_ "GenMsgSendType" BO_ 894 0;
BA_ "GenMsgCycleTime" BO_ 894 1500;
BA_ "MessageSubnet" BO_ 894 2;
BA_ "Prio" BO_ 894 0;
BA_ "DiagRequest" BO_ 577 1;
BA_ "MessageSubnet" BO_ 577 2;
BA_ "Prio" BO_ 577 0;
BA_ "GenMsgSendType" BO_ 298 0;
BA_ "GenMsgCycleTime" BO_ 298 100;
BA_ "GenMsgStartDelayTime" BO_ 298 40;
BA_ "MessageSubnet" BO_ 298 2;
BA_ "Prio" BO_ 298 0;
BA_ "GenMsgSendType" BO_ 1322 0;
BA_ "GenMsgCycleTime" BO_ 1322 1000;
BA_ "GenMsgStartDelayTime" BO_ 1322 40;
BA_ "MessageSubnet" BO_ 1322 2;
BA_ "Prio" BO_ 1322 0;
BA_ "DiagResponse" BO_ 1601 1;
BA_ "MessageSubnet" BO_ 1601 2;
BA_ "Prio" BO_ 1601 0;
BA_ "DiagRequest" BO_ 2018 1;
BA_ "MessageSubnet" BO_ 2018 2;
BA_ "Prio" BO_ 2018 0;
BA_ "DiagResponse" BO_ 2026 1;
BA_ "MessageSubnet" BO_ 2026 2;
BA_ "Prio" BO_ 2026 0;
BA_ "MessageSubnet" BO_ 1514 2;
BA_ "Prio" BO_ 1514 0;
BA_ "TpApplType" BO_ 1514 "DiagUUDTResponse";
BA_ "GenMsgILSupport" BO_ 1514 0;
BA_ "GenMsgSendType" BO_ 1300 0;
BA_ "GenMsgCycleTime" BO_ 1300 1000;
BA_ "GenMsgStartDelayTime" BO_ 1300 70;
BA_ "MessageSubnet" BO_ 1300 2;
BA_ "Prio" BO_ 1300 0;
BA_ "GenMsgSendType" BO_ 288 0;
BA_ "GenMsgCycleTime" BO_ 288 5000;
BA_ "GenMsgStartDelayTime" BO_ 288 10;
BA_ "MessageSubnet" BO_ 288 2;
BA_ "Prio" BO_ 288 0;
BA_ "DiagRequest" BO_ 2020 1;
BA_ "MessageSubnet" BO_ 2020 2;
BA_ "Prio" BO_ 2020 0;
BA_ "DiagResponse" BO_ 2028 1;
BA_ "MessageSubnet" BO_ 2028 2;
BA_ "Prio" BO_ 2028 0;
BA_ "MessageSubnet" BO_ 1516 2;
BA_ "Prio" BO_ 1516 0;
BA_ "TpApplType" BO_ 1516 "DiagUUDTResponse";
BA_ "GenMsgILSupport" BO_ 1516 0;
BA_ "GenMsgSendType" BO_ 485 0;
BA_ "GenMsgCycleTime" BO_ 485 10;
BA_ "MessageSubnet" BO_ 485 2;
BA_ "Prio" BO_ 485 0;
BA_ "GenMsgSendType" BO_ 1001 0;
BA_ "GenMsgCycleTime" BO_ 1001 100;
BA_ "MessageSubnet" BO_ 1001 2;
BA_ "Prio" BO_ 1001 0;
BA_ "GenMsgSendType" BO_ 961 0;
BA_ "GenMsgCycleTime" BO_ 961 100;
BA_ "MessageSubnet" BO_ 961 2;
BA_ "Prio" BO_ 961 0;
BA_ "GenMsgSendType" BO_ 804 0;
BA_ "GenMsgCycleTime" BO_ 804 500;
BA_ "MessageSubnet" BO_ 804 2;
BA_ "Prio" BO_ 804 0;
BA_ "GenMsgSendType" BO_ 842 0;
BA_ "GenMsgCycleTime" BO_ 842 50;
BA_ "MessageSubnet" BO_ 842 2;
BA_ "Prio" BO_ 842 0;
BA_ "GenMsgSendType" BO_ 1241 0;
BA_ "GenMsgCycleTime" BO_ 1241 500;
BA_ "MessageSubnet" BO_ 1241 2;
BA_ "Prio" BO_ 1241 0;
BA_ "GenMsgSendType" BO_ 491 0;
BA_ "GenMsgCycleTime" BO_ 491 12;
BA_ "MessageSubnet" BO_ 491 2;
BA_ "Prio" BO_ 491 0;
BA_ "GenMsgSendType" BO_ 1019 0;
BA_ "GenMsgCycleTime" BO_ 1019 250;
BA_ "MessageSubnet" BO_ 1019 2;
BA_ "Prio" BO_ 1019 0;
BA_ "GenMsgSendType" BO_ 493 0;
BA_ "GenMsgCycleTime" BO_ 493 12;
BA_ "MessageSubnet" BO_ 493 2;
BA_ "Prio" BO_ 493 0;
BA_ "GenMsgSendType" BO_ 401 0;
BA_ "GenMsgCycleTime" BO_ 401 12;
BA_ "MessageSubnet" BO_ 401 2;
BA_ "Prio" BO_ 401 0;
BA_ "GenMsgSendType" BO_ 707 0;
BA_ "GenMsgCycleTime" BO_ 707 50;
BA_ "MessageSubnet" BO_ 707 2;
BA_ "Prio" BO_ 707 0;
BA_ "GenMsgSendType" BO_ 1265 0;
BA_ "GenMsgCycleTime" BO_ 1265 1000;
BA_ "MessageSubnet" BO_ 1265 2;
BA_ "Prio" BO_ 1265 0;
BA_ "GenMsgSendType" BO_ 417 0;
BA_ "GenMsgCycleTime" BO_ 417 25;
BA_ "MessageSubnet" BO_ 417 2;
BA_ "Prio" BO_ 417 0;
BA_ "GenMsgSendType" BO_ 1233 0;
BA_ "GenMsgCycleTime" BO_ 1233 500;
BA_ "MessageSubnet" BO_ 1233 2;
BA_ "Prio" BO_ 1233 0;
BA_ "GenMsgSendType" BO_ 1217 0;
BA_ "GenMsgCycleTime" BO_ 1217 500;
BA_ "MessageSubnet" BO_ 1217 2;
BA_ "Prio" BO_ 1217 0;
BA_ "GenMsgSendType" BO_ 665 0;
BA_ "GenMsgCycleTime" BO_ 665 100;
BA_ "MessageSubnet" BO_ 665 2;
BA_ "Prio" BO_ 665 0;
BA_ "GenMsgSendType" BO_ 985 0;
BA_ "GenMsgCycleTime" BO_ 985 100;
BA_ "MessageSubnet" BO_ 985 2;
BA_ "Prio" BO_ 985 0;
BA_ "GenMsgSendType" BO_ 1017 0;
BA_ "GenMsgCycleTime" BO_ 1017 250;
BA_ "MessageSubnet" BO_ 1017 2;
BA_ "Prio" BO_ 1017 0;
BA_ "GenMsgSendType" BO_ 977 0;
BA_ "GenMsgCycleTime" BO_ 977 100;
BA_ "MessageSubnet" BO_ 977 2;
BA_ "Prio" BO_ 977 0;
BA_ "GenMsgSendType" BO_ 201 0;
BA_ "GenMsgCycleTime" BO_ 201 12;
BA_ "MessageSubnet" BO_ 201 2;
BA_ "Prio" BO_ 201 0;
BA_ "GenMsgSendType" BO_ 501 0;
BA_ "GenMsgCycleTime" BO_ 501 25;
BA_ "MessageSubnet" BO_ 501 2;
BA_ "Prio" BO_ 501 0;
BA_ "GenMsgSendType" BO_ 1225 0;
BA_ "GenMsgCycleTime" BO_ 1225 500;
BA_ "MessageSubnet" BO_ 1225 2;
BA_ "Prio" BO_ 1225 0;
BA_ "GenMsgSendType" BO_ 409 0;
BA_ "GenMsgCycleTime" BO_ 409 25;
BA_ "MessageSubnet" BO_ 409 2;
BA_ "Prio" BO_ 409 0;
BA_ "GenMsgSendType" BO_ 413 0;
BA_ "GenMsgCycleTime" BO_ 413 25;
BA_ "MessageSubnet" BO_ 413 2;
BA_ "Prio" BO_ 413 0;
BA_ "DiagState" BO_ 257 1;
BA_ "MessageSubnet" BO_ 257 2;
BA_ "Prio" BO_ 257 0;
BA_ "GenMsgILSupport" BO_ 257 0;
BA_ "MessageSubnet" BO_ 2015 2;
BA_ "Prio" BO_ 2015 0;
BA_ "GenMsgILSupport" BO_ 2015 0;
BA_ "DiagRequest" BO_ 2016 1;
BA_ "MessageSubnet" BO_ 2016 2;
BA_ "Prio" BO_ 2016 0;
BA_ "MessageSubnet" BO_ 197 2;
BA_ "Prio" BO_ 197 0;
BA_ "GenMsgSendType" BO_ 249 0;
BA_ "GenMsgCycleTime" BO_ 249 12;
BA_ "MessageSubnet" BO_ 249 2;
BA_ "Prio" BO_ 249 0;
BA_ "GenMsgSendType" BO_ 1009 0;
BA_ "GenMsgCycleTime" BO_ 1009 250;
BA_ "GenMsgStartDelayTime" BO_ 1009 10;
BA_ "MessageSubnet" BO_ 1009 2;
BA_ "Prio" BO_ 1009 0;
BA_ "GenMsgSendType" BO_ 1257 0;
BA_ "GenMsgCycleTime" BO_ 1257 1000;
BA_ "GenMsgStartDelayTime" BO_ 1257 10;
BA_ "MessageSubnet" BO_ 1257 2;
BA_ "Prio" BO_ 1257 0;
BA_ "GenMsgSendType" BO_ 505 0;
BA_ "GenMsgCycleTime" BO_ 505 30;
BA_ "GenMsgStartDelayTime" BO_ 505 20;
BA_ "MessageSubnet" BO_ 505 2;
BA_ "Prio" BO_ 505 0;
BA_ "GenMsgSendType" BO_ 497 0;
BA_ "GenMsgCycleTime" BO_ 497 100;
BA_ "GenMsgDelayTime" BO_ 497 30;
BA_ "GenMsgStartDelayTime" BO_ 497 10;
BA_ "MessageSubnet" BO_ 497 2;
BA_ "Prio" BO_ 497 0;
BA_ "GenMsgSendType" BO_ 969 0;
BA_ "GenMsgCycleTime" BO_ 969 100;
BA_ "GenMsgStartDelayTime" BO_ 969 20;
BA_ "MessageSubnet" BO_ 969 2;
BA_ "Prio" BO_ 969 0;
BA_ "GenMsgSendType" BO_ 1249 0;
BA_ "GenMsgCycleTime" BO_ 1249 1000;
BA_ "GenMsgStartDelayTime" BO_ 1249 60;
BA_ "MessageSubnet" BO_ 1249 2;
BA_ "Prio" BO_ 1249 0;
BA_ "DiagResponse" BO_ 2024 1;
BA_ "MessageSubnet" BO_ 2024 2;
BA_ "Prio" BO_ 2024 0;
BA_ "MessageSubnet" BO_ 1512 2;
BA_ "Prio" BO_ 1512 0;
BA_ "TpApplType" BO_ 1512 "DiagUUDTResponse";
BA_ "GenMsgILSupport" BO_ 1512 0;
BA_ "GenMsgSendType" BO_ 840 0;
BA_ "GenMsgCycleTime" BO_ 840 50;
BA_ "MessageSubnet" BO_ 840 2;
BA_ "Prio" BO_ 840 0;
BA_ "MessageSubnet" BO_ 193 2;
BA_ "Prio" BO_ 193 0;
BA_ "GenMsgSendType" BO_ 481 0;
BA_ "GenMsgCycleTime" BO_ 481 30;
BA_ "GenMsgStartDelayTime" BO_ 481 10;
BA_ "MessageSubnet" BO_ 481 2;
BA_ "Prio" BO_ 481 0;
BA_ "GenMsgSendType" BO_ 455 0;
BA_ "GenMsgCycleTime" BO_ 455 20;
BA_ "MessageSubnet" BO_ 455 2;
BA_ "Prio" BO_ 455 0;
BA_ "GenMsgSendType" BO_ 761 0;
BA_ "GenMsgCycleTime" BO_ 761 50;
BA_ "MessageSubnet" BO_ 761 2;
BA_ "Prio" BO_ 761 0;
BA_ "GenMsgSendType" BO_ 489 0;
BA_ "GenMsgCycleTime" BO_ 489 20;
BA_ "MessageSubnet" BO_ 489 2;
BA_ "Prio" BO_ 489 0;
BA_ "GenMsgSendType" BO_ 381 0;
BA_ "GenMsgCycleTime" BO_ 381 100;
BA_ "MessageSubnet" BO_ 381 2;
BA_ "Prio" BO_ 381 0;
BA_ "GenMsgSendType" BO_ 241 0;
BA_ "GenMsgCycleTime" BO_ 241 10;
BA_ "MessageSubnet" BO_ 241 2;
BA_ "Prio" BO_ 241 0;
BA_ "DiagResponse" BO_ 2025 1;
BA_ "MessageSubnet" BO_ 2025 2;
BA_ "Prio" BO_ 2025 0;
BA_ "DiagResponse" BO_ 2029 1;
BA_ "MessageSubnet" BO_ 2029 2;
BA_ "Prio" BO_ 2029 0;
BA_ "DiagResponse" BO_ 2031 1;
BA_ "MessageSubnet" BO_ 2031 2;
BA_ "Prio" BO_ 2031 0;
BA_ "MessageSubnet" BO_ 1513 2;
BA_ "Prio" BO_ 1513 0;
BA_ "TpApplType" BO_ 1513 "DiagUUDTResponse";
BA_ "GenMsgILSupport" BO_ 1513 0;
BA_ "MessageSubnet" BO_ 1517 2;
BA_ "Prio" BO_ 1517 0;
BA_ "TpApplType" BO_ 1517 "DiagUUDTResponse";
BA_ "GenMsgILSupport" BO_ 1517 0;
BA_ "MessageSubnet" BO_ 1519 2;
BA_ "Prio" BO_ 1519 0;
BA_ "TpApplType" BO_ 1519 "DiagUUDTResponse";
BA_ "GenMsgILSupport" BO_ 1519 0;
BA_ "DiagResponse" BO_ 2030 1;
BA_ "MessageSubnet" BO_ 2030 2;
BA_ "Prio" BO_ 2030 0;
BA_ "MessageSubnet" BO_ 1518 2;
BA_ "Prio" BO_ 1518 0;
BA_ "TpApplType" BO_ 1518 "DiagUUDTResponse";
BA_ "GenMsgILSupport" BO_ 1518 0;
BA_ "MessageSubnet" BO_ 1346 2;
BA_ "Prio" BO_ 1346 0;
BA_ "TpApplType" BO_ 1346 "DiagUUDTResponse";
BA_ "GenMsgILSupport" BO_ 1346 0;
BA_ "MessageSubnet" BO_ 1353 2;
BA_ "Prio" BO_ 1353 0;
BA_ "TpApplType" BO_ 1353 "DiagUUDTResponse";
BA_ "GenMsgILSupport" BO_ 1353 0;
BA_ "DiagResponse" BO_ 1609 1;
BA_ "MessageSubnet" BO_ 1609 2;
BA_ "Prio" BO_ 1609 0;
BA_ "DiagResponse" BO_ 1602 1;
BA_ "MessageSubnet" BO_ 1602 2;
BA_ "Prio" BO_ 1602 0;
BA_ "DiagResponse" BO_ 2027 1;
BA_ "MessageSubnet" BO_ 2027 2;
BA_ "Prio" BO_ 2027 0;
BA_ "MessageSubnet" BO_ 1515 2;
BA_ "Prio" BO_ 1515 0;
BA_ "TpApplType" BO_ 1515 "DiagUUDTResponse";
BA_ "GenMsgILSupport" BO_ 1515 0;
BA_ "DiagResponse" BO_ 1614 1;
BA_ "MessageSubnet" BO_ 1614 2;
BA_ "Prio" BO_ 1614 0;
BA_ "MessageSubnet" BO_ 1348 2;
BA_ "Prio" BO_ 1348 0;
BA_ "TpApplType" BO_ 1348 "DiagUUDTResponse";
BA_ "GenMsgILSupport" BO_ 1348 0;
BA_ "MessageSubnet" BO_ 1349 2;
BA_ "Prio" BO_ 1349 0;
BA_ "TpApplType" BO_ 1349 "DiagUUDTResponse";
BA_ "GenMsgILSupport" BO_ 1349 0;
BA_ "MessageSubnet" BO_ 1352 2;
BA_ "Prio" BO_ 1352 0;
BA_ "TpApplType" BO_ 1352 "DiagUUDTResponse";
BA_ "GenMsgILSupport" BO_ 1352 0;
BA_ "MessageSubnet" BO_ 1354 2;
BA_ "Prio" BO_ 1354 0;
BA_ "TpApplType" BO_ 1354 "DiagUUDTResponse";
BA_ "GenMsgILSupport" BO_ 1354 0;
BA_ "DiagResponse" BO_ 1605 1;
BA_ "MessageSubnet" BO_ 1605 2;
BA_ "Prio" BO_ 1605 0;
BA_ "DiagResponse" BO_ 1620 1;
BA_ "MessageSubnet" BO_ 1620 2;
BA_ "Prio" BO_ 1620 0;
BA_ "DiagResponse" BO_ 1604 1;
BA_ "MessageSubnet" BO_ 1604 2;
BA_ "Prio" BO_ 1604 0;
BA_ "DiagResponse" BO_ 1612 1;
BA_ "MessageSubnet" BO_ 1612 2;
BA_ "Prio" BO_ 1612 0;
BA_ "GenMsgILSupport" BO_ 1612 0;
BA_ "DiagResponse" BO_ 1615 1;
BA_ "MessageSubnet" BO_ 1615 2;
BA_ "Prio" BO_ 1615 0;
